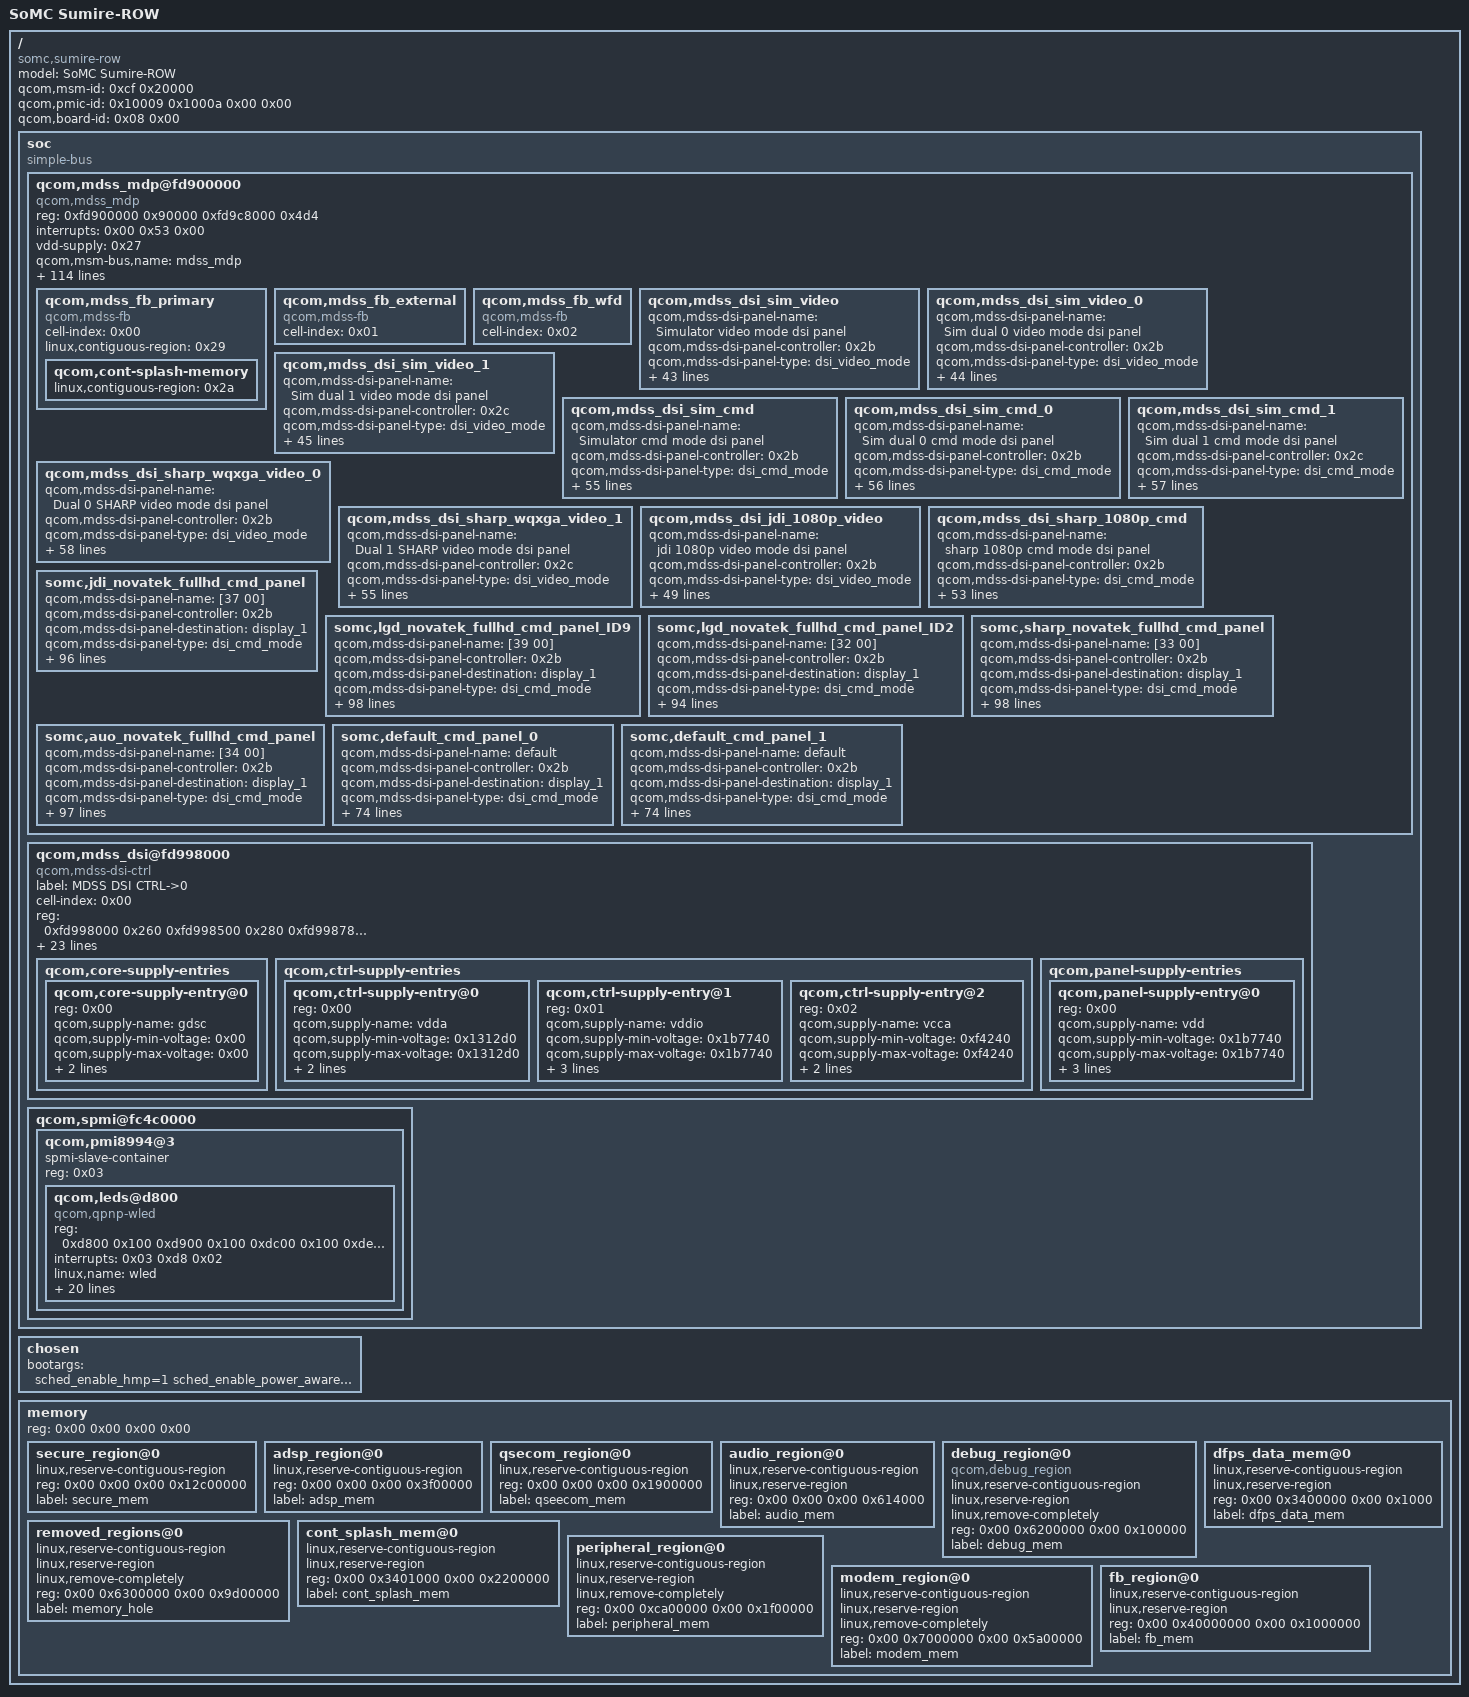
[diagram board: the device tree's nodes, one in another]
/dts-v1/;

/memreserve/	0x0000000000000000 0x0000000000001000;
/memreserve/	0x00000000ac1c0000 0x0000000000001000;
/ {
	model = "SoMC Sumire-ROW";
	compatible = "somc,sumire-row", "qcom,msm8994", "lk2nd,device";
	qcom,msm-id = <0xcf 0x20000>;
	qcom,pmic-id = <0x10009 0x1000a 0x00 0x00>;
	qcom,board-id = <0x08 0x00>;

	soc {
		#address-cells = <0x01>;
		#size-cells = <0x01>;
		ranges = <0x00 0x00 0x00 0xffffffff>;
		compatible = "simple-bus";

		qcom,mdss_mdp@fd900000 {
			compatible = "qcom,mdss_mdp";
			reg = <0xfd900000 0x90000 0xfd9c8000 0x4d4>;
			reg-names = "mdp_phys", "vbif_phys";
			interrupts = <0x00 0x53 0x00>;
			vdd-supply = <0x27>;
			qcom,msm-bus,name = "mdss_mdp";
			qcom,msm-bus,num-cases = <0x03>;
			qcom,msm-bus,num-paths = <0x02>;
			qcom,msm-bus,vectors-KBps = <0x16 0x200 0x00 0x00 0x17 0x200 0x00 0x00 0x16 0x200 0x00 0x61a800 0x17 0x200 0x00 0x61a800 0x16 0x200 0x00 0x61a800 0x17 0x200 0x00 0x61a800>;
			qcom,mdss-ab-factor = <0x01 0x01>;
			qcom,mdss-ib-factor = <0x01 0x01>;
			qcom,mdss-clk-factor = <0x69 0x64>;
			qcom,max-mixer-width = <0x800>;
			qcom,mdss-vbif-qos-rt-setting = <0x01 0x02 0x02 0x02>;
			qcom,mdss-vbif-qos-nrt-setting = <0x01 0x01 0x01 0x01>;
			qcom,mdss-mdp-reg-offset = <0x1000>;
			qcom,max-bandwidth-low-kbps = <0x6f63a0>;
			qcom,max-bandwidth-high-kbps = <0x6f63a0>;
			qcom,max-bandwidth-per-pipe-kbps = <0x1b7740>;
			qcom,max-clk-rate = <0x17d78400>;
			qcom,mdss-dram-channels = <0x02>;
			qcom,mdss-default-ot-wr-limit = <0x10>;
			qcom,mdss-default-ot-rd-limit = <0x10>;
			qcom,mdss-pipe-vig-off = <0x5000 0x7000 0x9000 0xb000>;
			qcom,mdss-pipe-rgb-off = <0x15000 0x17000 0x19000 0x1b000>;
			qcom,mdss-pipe-dma-off = <0x25000 0x27000>;
			qcom,mdss-pipe-cursor-off = <0x35000 0x37000>;
			qcom,mdss-pipe-vig-fetch-id = <0x01 0x04 0x07 0x13>;
			qcom,mdss-pipe-rgb-fetch-id = <0x10 0x11 0x12 0x16>;
			qcom,mdss-pipe-dma-fetch-id = <0x0a 0x0d>;
			qcom,mdss-pipe-vig-xin-id = <0x00 0x04 0x08 0x0c>;
			qcom,mdss-pipe-rgb-xin-id = <0x01 0x05 0x09 0x0d>;
			qcom,mdss-pipe-dma-xin-id = <0x02 0x0a>;
			qcom,mdss-pipe-cursor-xin-id = <0x07 0x07>;
			qcom,mdss-en-svs-high;
			qcom,mdss-has-panic-ctrl;
			qcom,mdss-pipe-vig-panic-ctrl-offsets = <0x00 0x01 0x02 0x03>;
			qcom,mdss-pipe-rgb-panic-ctrl-offsets = <0x04 0x05 0x06 0x07>;
			qcom,mdss-pipe-dma-panic-ctrl-offsets = <0x08 0x09>;
			qcom,mdss-pipe-rgb-fixed-mmb = <0x05 0x00 0x01 0x08 0x09 0x0a 0x05 0x02 0x03 0x0b 0x0c 0x0d 0x05 0x04 0x05 0x0e 0x0f 0x10 0x05 0x06 0x07 0x11 0x12 0x13>;
			qcom,mdss-pipe-vig-fixed-mmb = <0x01 0x14 0x01 0x15 0x01 0x16 0x01 0x17>;
			qcom,mdss-pipe-vig-clk-ctrl-offsets = <0x2ac 0x00 0x00 0x2b4 0x00 0x00 0x2bc 0x00 0x00 0x2c4 0x00 0x00>;
			qcom,mdss-pipe-rgb-clk-ctrl-offsets = <0x2ac 0x04 0x08 0x2b4 0x04 0x08 0x2bc 0x04 0x08 0x2c4 0x04 0x08>;
			qcom,mdss-pipe-dma-clk-ctrl-offsets = <0x2ac 0x08 0x0c 0x2b4 0x08 0x0c>;
			qcom,mdss-pipe-cursor-clk-ctrl-offsets = <0x3a8 0x10 0x0f 0x3b0 0x10 0x0f>;
			qcom,mdss-pipe-sw-reset-off = <0x28>;
			qcom,mdss-pipe-vig-sw-reset-map = <0x05 0x06 0x07 0x08>;
			qcom,mdss-pipe-rgb-sw-reset-map = <0x09 0x0a 0x0b 0x0c>;
			qcom,mdss-pipe-dma-sw-reset-map = <0x0d 0x0e>;
			qcom,mdss-smp-data = <0x2c 0x2000>;
			qcom,mdss-sspp-len = <0x2000>;
			qcom,mdss-ctl-off = <0x2000 0x2200 0x2400 0x2600 0x2800>;
			qcom,mdss-mixer-intf-off = <0x45000 0x46000 0x47000 0x4a000>;
			qcom,mdss-mixer-wb-off = <0x48000 0x49000>;
			qcom,mdss-dspp-off = <0x55000 0x57000 0x59000 0x5b000>;
			qcom,mdss-wb-off = <0x65000 0x65800 0x66000 0x66800 0x67000>;
			qcom,mdss-intf-off = <0x6b000 0x6b800 0x6c000 0x6c800 0x6d000>;
			qcom,mdss-pingpong-off = <0x71000 0x71800 0x72000 0x72800>;
			qcom,mdss-ad-off = <0x79000 0x79800 0x7a000>;
			qcom,mdss-highest-bank-bit = <0x03>;
			qcom,mdss-has-decimation;
			qcom,mdss-has-rotator-downscale;
			qcom,mdss-has-bwc;
			qcom,mdss-wfd-mode = "intf";
			qcom,mdss-has-source-split;
			qcom,mdss-ctl-len = <0x200>;
			clocks = <0x1e 0x684ccb41 0x1e 0xcc07d687 0x1e 0x6dc1f8f1 0x1e 0x618336ac 0x1e 0x42a022d3>;
			clock-names = "iface_clk", "bus_clk", "core_clk_src", "core_clk", "vsync_clk";
			qcom,mdp-settings = <0x117c 0xffff 0x1184 0xc000ff00 0x11e0 0xa4 0x11e4 0x00 0x12ac 0xc0000ccc 0x12b4 0xc0000ccc 0x12bc 0xcccccc 0x12c4 0xcc 0x13a8 0xcccc0c0 0x13b0 0xccccc0c0 0x13b8 0xccccc0c0 0x13d0 0xccc000>;
			qcom,regs-dump-mdp = <0x1000 0x1408 0x2000 0x2064 0x2200 0x2264 0x2400 0x2464 0x2600 0x2664 0x2800 0x2864 0x5000 0x5130 0x5200 0x5230 0x7000 0x7130 0x7200 0x7230 0x9000 0x9130 0x9200 0x9230 0xb000 0xb130 0xb200 0xb230 0x15000 0x15130 0x15200 0x15230 0x17000 0x17130 0x17200 0x17230 0x19000 0x19130 0x19200 0x19230 0x1b000 0x1b130 0x1b200 0x1b230 0x25000 0x2512c 0x27000 0x2712c 0x45000 0x4538c 0x46000 0x4638c 0x47000 0x4738c 0x48000 0x4838c 0x49000 0x4938c 0x4a000 0x4a38c 0x55000 0x5522c 0x57000 0x5722c 0x59000 0x5922c 0x5b000 0x5b22c 0x65000 0x652b4 0x65800 0x65ab4 0x66000 0x662b4 0x66800 0x66ab4 0x67000 0x672b4 0x6b800 0x6ba54 0x6c000 0x6c254 0x6c800 0x6ca54 0x71000 0x710d0 0x71800 0x718d0>;
			qcom,regs-dump-names-mdp = "MDP", "CTL_0", "CTL_1", "CTL_2", "CTL_3", "CTL_4", "VIG0_SSPP", "VIG0", "VIG1_SSPP", "VIG1", "VIG2_SSPP", "VIG2", "VIG3_SSPP", "VIG3", "RGB0_SSPP", "RGB0", "RGB1_SSPP", "RGB1", "RGB2_SSPP", "RGB2", "RGB3_SSPP", "RGB3", "DMA0_SSPP", "DMA1_SSPP", "LAYER_0", "LAYER_1", "LAYER_2", "LAYER_3", "LAYER_4", "LAYER_5", "DSPP_0", "DSPP_1", "DSPP_2", "DSPP_3", "WB_0", "WB_1", "WB_2", "WB_3", "WB_4", "INTF_1", "INTF_2", "INTF_3", "PP_0", "PP_1";
			qcom,mdss-prefill-outstanding-buffer-bytes = <0x800>;
			qcom,mdss-prefill-y-buffer-bytes = <0x1000>;
			qcom,mdss-prefill-scaler-buffer-lines-bilinear = <0x02>;
			qcom,mdss-prefill-scaler-buffer-lines-caf = <0x04>;
			qcom,mdss-prefill-post-scaler-buffer-pixels = <0x800>;
			qcom,mdss-prefill-pingpong-buffer-pixels = <0x1400>;
			qcom,mdss-prefill-fbc-lines = <0x02>;
			qcom,mdss-pref-prim-intf = "dsi";
			somc,dric-gpio = <0x28 0x38 0x00>;
			somc,mul-channel-scaling = <0x03>;
			linux,phandle = <0x32>;
			phandle = <0x32>;

			qcom,mdss_fb_primary {
				cell-index = <0x00>;
				compatible = "qcom,mdss-fb";
				linux,contiguous-region = <0x29>;
				linux,phandle = <0x31>;
				phandle = <0x31>;

				qcom,cont-splash-memory {
					linux,contiguous-region = <0x2a>;
				};
			};

			qcom,mdss_fb_external {
				cell-index = <0x01>;
				compatible = "qcom,mdss-fb";
				linux,phandle = <0x41>;
				phandle = <0x41>;
			};

			qcom,mdss_fb_wfd {
				cell-index = <0x02>;
				compatible = "qcom,mdss-fb";
				linux,phandle = <0x3e>;
				phandle = <0x3e>;
			};

			qcom,mdss_dsi_sim_video {
				qcom,mdss-dsi-panel-name = "Simulator video mode dsi panel";
				qcom,mdss-dsi-panel-controller = <0x2b>;
				qcom,mdss-dsi-panel-type = "dsi_video_mode";
				qcom,mdss-dsi-panel-destination = "display_1";
				qcom,mdss-dsi-panel-framerate = <0x3c>;
				qcom,mdss-dsi-virtual-channel-id = <0x00>;
				qcom,mdss-dsi-stream = <0x00>;
				qcom,mdss-dsi-panel-width = <0x280>;
				qcom,mdss-dsi-panel-height = <0x1e0>;
				qcom,mdss-dsi-h-front-porch = <0x06>;
				qcom,mdss-dsi-h-back-porch = <0x06>;
				qcom,mdss-dsi-h-pulse-width = <0x02>;
				qcom,mdss-dsi-h-sync-skew = <0x00>;
				qcom,mdss-dsi-v-back-porch = <0x06>;
				qcom,mdss-dsi-v-front-porch = <0x06>;
				qcom,mdss-dsi-v-pulse-width = <0x02>;
				qcom,mdss-dsi-h-left-border = <0x00>;
				qcom,mdss-dsi-h-right-border = <0x00>;
				qcom,mdss-dsi-v-top-border = <0x00>;
				qcom,mdss-dsi-v-bottom-border = <0x00>;
				qcom,mdss-dsi-bpp = <0x18>;
				qcom,mdss-dsi-underflow-color = <0xff>;
				qcom,mdss-dsi-border-color = <0x00>;
				qcom,mdss-dsi-on-command = [32 01 00 00 00 00 02 00 00];
				qcom,mdss-dsi-off-command = [22 01 00 00 00 00 02 00 00];
				qcom,mdss-dsi-on-command-state = "dsi_lp_mode";
				qcom,mdss-dsi-off-command-state = "dsi_lp_mode";
				qcom,mdss-dsi-h-sync-pulse = <0x00>;
				qcom,mdss-dsi-traffic-mode = "non_burst_sync_event";
				qcom,mdss-dsi-bllp-eof-power-mode;
				qcom,mdss-dsi-bllp-power-mode;
				qcom,mdss-dsi-lane-0-state;
				qcom,mdss-dsi-lane-1-state;
				qcom,mdss-dsi-lane-2-state;
				qcom,mdss-dsi-lane-3-state;
				qcom,mdss-dsi-panel-timings = <0x00 0x00 0x00>;
				qcom,mdss-dsi-t-clk-post = <0x04>;
				qcom,mdss-dsi-t-clk-pre = <0x1b>;
				qcom,mdss-dsi-dma-trigger = "trigger_sw";
				qcom,mdss-dsi-mdp-trigger = "none";
				qcom,mdss-dsi-reset-sequence = <0x01 0x00 0x00 0x00 0x01 0x00>;
				qcom,panel-ack-disabled;
			};

			qcom,mdss_dsi_sim_video_0 {
				qcom,mdss-dsi-panel-name = "Sim dual 0 video mode dsi panel";
				qcom,mdss-dsi-panel-controller = <0x2b>;
				qcom,mdss-dsi-panel-type = "dsi_video_mode";
				qcom,mdss-dsi-panel-destination = "display_1";
				qcom,mdss-dsi-panel-framerate = <0x3c>;
				qcom,mdss-dsi-virtual-channel-id = <0x00>;
				qcom,mdss-dsi-stream = <0x00>;
				qcom,mdss-dsi-panel-width = <0x500>;
				qcom,mdss-dsi-panel-height = <0x5a0>;
				qcom,mdss-dsi-h-front-porch = <0x78>;
				qcom,mdss-dsi-h-back-porch = <0x2c>;
				qcom,mdss-dsi-h-pulse-width = <0x10>;
				qcom,mdss-dsi-h-sync-skew = <0x00>;
				qcom,mdss-dsi-v-back-porch = <0x04>;
				qcom,mdss-dsi-v-front-porch = <0x08>;
				qcom,mdss-dsi-v-pulse-width = <0x04>;
				qcom,mdss-dsi-h-left-border = <0x00>;
				qcom,mdss-dsi-h-right-border = <0x00>;
				qcom,mdss-dsi-v-top-border = <0x00>;
				qcom,mdss-dsi-v-bottom-border = <0x00>;
				qcom,mdss-dsi-bpp = <0x18>;
				qcom,mdss-dsi-underflow-color = <0xff>;
				qcom,mdss-dsi-border-color = <0x00>;
				qcom,mdss-dsi-h-sync-pulse = <0x00>;
				qcom,mdss-dsi-traffic-mode = "non_burst_sync_event";
				qcom,mdss-dsi-bllp-eof-power-mode;
				qcom,mdss-dsi-bllp-power-mode;
				qcom,mdss-dsi-panel-broadcast-mode;
				qcom,mdss-dsi-lane-0-state;
				qcom,mdss-dsi-lane-1-state;
				qcom,mdss-dsi-lane-2-state;
				qcom,mdss-dsi-lane-3-state;
				qcom,mdss-dsi-panel-timings = <0xcd322200 0x60642634 0x29030400>;
				qcom,mdss-dsi-t-clk-post = <0x03>;
				qcom,mdss-dsi-t-clk-pre = <0x27>;
				qcom,mdss-dsi-bl-max-level = <0xfff>;
				qcom,mdss-dsi-dma-trigger = "trigger_sw";
				qcom,mdss-dsi-mdp-trigger = "none";
				qcom,mdss-dsi-on-command-state = "dsi_lp_mode";
				qcom,mdss-dsi-off-command = [05 01 00 00 32 00 02 28 00 05 01 00 00 78 00 02 10 00];
				qcom,mdss-dsi-off-command-state = "dsi_hs_mode";
				qcom,mdss-dsi-reset-sequence = <0x01 0x14 0x00 0xc8 0x01 0x14>;
				qcom,panel-ack-disabled;
			};

			qcom,mdss_dsi_sim_video_1 {
				qcom,mdss-dsi-panel-name = "Sim dual 1 video mode dsi panel";
				qcom,mdss-dsi-panel-controller = <0x2c>;
				qcom,mdss-dsi-panel-type = "dsi_video_mode";
				qcom,mdss-dsi-panel-destination = "display_2";
				qcom,mdss-dsi-panel-framerate = <0x3c>;
				qcom,mdss-dsi-virtual-channel-id = <0x00>;
				qcom,mdss-dsi-stream = <0x00>;
				qcom,mdss-dsi-panel-width = <0x500>;
				qcom,mdss-dsi-panel-height = <0x5a0>;
				qcom,mdss-dsi-h-front-porch = <0x78>;
				qcom,mdss-dsi-h-back-porch = <0x2c>;
				qcom,mdss-dsi-h-pulse-width = <0x10>;
				qcom,mdss-dsi-h-sync-skew = <0x00>;
				qcom,mdss-dsi-v-back-porch = <0x04>;
				qcom,mdss-dsi-v-front-porch = <0x08>;
				qcom,mdss-dsi-v-pulse-width = <0x04>;
				qcom,mdss-dsi-h-left-border = <0x00>;
				qcom,mdss-dsi-h-right-border = <0x00>;
				qcom,mdss-dsi-v-top-border = <0x00>;
				qcom,mdss-dsi-v-bottom-border = <0x00>;
				qcom,mdss-dsi-bpp = <0x18>;
				qcom,mdss-dsi-underflow-color = <0xff>;
				qcom,mdss-dsi-border-color = <0x00>;
				qcom,mdss-dsi-h-sync-pulse = <0x00>;
				qcom,mdss-dsi-traffic-mode = "non_burst_sync_event";
				qcom,mdss-dsi-bllp-eof-power-mode;
				qcom,mdss-dsi-bllp-power-mode;
				qcom,mdss-dsi-lane-0-state;
				qcom,mdss-dsi-lane-1-state;
				qcom,mdss-dsi-lane-2-state;
				qcom,mdss-dsi-lane-3-state;
				qcom,mdss-dsi-panel-broadcast-mode;
				qcom,mdss-dsi-panel-timings = <0xcd322200 0x60642634 0x29030400>;
				qcom,mdss-dsi-t-clk-post = <0x03>;
				qcom,mdss-dsi-t-clk-pre = <0x27>;
				qcom,mdss-dsi-bl-min-level = <0x01>;
				qcom,mdss-dsi-bl-max-level = <0xfff>;
				qcom,mdss-dsi-dma-trigger = "trigger_sw";
				qcom,mdss-dsi-mdp-trigger = "none";
				qcom,mdss-dsi-on-command-state = "dsi_lp_mode";
				qcom,mdss-dsi-off-command = [05 01 00 00 32 00 02 28 00 05 01 00 00 78 00 02 10 00];
				qcom,mdss-dsi-off-command-state = "dsi_hs_mode";
				qcom,mdss-dsi-reset-sequence = <0x01 0x14 0x00 0xc8 0x01 0x14>;
				qcom,panel-ack-disabled;
			};

			qcom,mdss_dsi_sim_cmd {
				qcom,mdss-dsi-panel-name = "Simulator cmd mode dsi panel";
				qcom,mdss-dsi-panel-controller = <0x2b>;
				qcom,mdss-dsi-panel-type = "dsi_cmd_mode";
				qcom,mdss-dsi-panel-destination = "display_1";
				qcom,mdss-dsi-panel-framerate = <0x3c>;
				qcom,mdss-dsi-virtual-channel-id = <0x00>;
				qcom,mdss-dsi-stream = <0x00>;
				qcom,mdss-dsi-panel-width = <0x438>;
				qcom,mdss-dsi-panel-height = <0x780>;
				qcom,mdss-dsi-h-front-porch = <0x60>;
				qcom,mdss-dsi-h-back-porch = <0x40>;
				qcom,mdss-dsi-h-pulse-width = <0x10>;
				qcom,mdss-dsi-h-sync-skew = <0x00>;
				qcom,mdss-dsi-v-back-porch = <0x10>;
				qcom,mdss-dsi-v-front-porch = <0x04>;
				qcom,mdss-dsi-v-pulse-width = <0x01>;
				qcom,mdss-dsi-h-left-border = <0x00>;
				qcom,mdss-dsi-h-right-border = <0x00>;
				qcom,mdss-dsi-v-top-border = <0x00>;
				qcom,mdss-dsi-v-bottom-border = <0x00>;
				qcom,mdss-dsi-bpp = <0x18>;
				qcom,mdss-dsi-color-order = "rgb_swap_rgb";
				qcom,mdss-dsi-underflow-color = <0xff>;
				qcom,mdss-dsi-border-color = <0x00>;
				qcom,mdss-dsi-h-sync-pulse = <0x00>;
				qcom,mdss-dsi-traffic-mode = "non_burst_sync_event";
				qcom,mdss-dsi-lane-map = "lane_map_0123";
				qcom,mdss-dsi-bllp-eof-power-mode;
				qcom,mdss-dsi-bllp-power-mode;
				qcom,mdss-dsi-lane-0-state;
				qcom,mdss-dsi-lane-1-state;
				qcom,mdss-dsi-lane-2-state;
				qcom,mdss-dsi-lane-3-state;
				qcom,mdss-dsi-hor-line-idle = <0x00 0x28 0x100 0x28 0x78 0x80 0x78 0xf0 0x40>;
				qcom,mdss-dsi-panel-timings = <0xcd322200 0x60642634 0x29030400>;
				qcom,mdss-dsi-reset-sequence = <0x01 0x0a 0x00 0x0a 0x01 0x0a>;
				qcom,mdss-dsi-t-clk-post = <0x03>;
				qcom,mdss-dsi-t-clk-pre = <0x27>;
				qcom,mdss-dsi-bl-max-level = <0xfff>;
				qcom,mdss-dsi-dma-trigger = "trigger_sw";
				qcom,mdss-dsi-mdp-trigger = "none";
				qcom,mdss-dsi-te-pin-select = <0x01>;
				qcom,mdss-dsi-wr-mem-start = <0x2c>;
				qcom,mdss-dsi-wr-mem-continue = <0x3c>;
				qcom,mdss-dsi-te-dcs-command = <0x01>;
				qcom,mdss-dsi-te-check-enable;
				qcom,mdss-dsi-te-using-te-pin;
				qcom,mdss-dsi-on-command = <0x29010000 0x2b0 0x3050100 0xa0001 0x150100 0xa0002 0x3a773901 0xa00 0x52a0000 0x4ff3901 0xa00 0x52b0000 0x59f1501 0xa00 0x2350039 0x100000a 0x34400 0x150100 0xa0002 0x51ff1501 0xa00 0x2532415 0x100000a 0x25500 0x5010000 0x78000111 0x5010000 0x10000129>;
				qcom,mdss-dsi-on-command-state = "dsi_lp_mode";
				qcom,mdss-dsi-off-command = [05 01 00 00 32 00 02 28 00 05 01 00 00 78 00 02 10 00];
				qcom,mdss-dsi-off-command-state = "dsi_hs_mode";
				qcom,panel-ack-disabled;
			};

			qcom,mdss_dsi_sim_cmd_0 {
				qcom,mdss-dsi-panel-name = "Sim dual 0 cmd mode dsi panel";
				qcom,mdss-dsi-panel-controller = <0x2b>;
				qcom,mdss-dsi-panel-type = "dsi_cmd_mode";
				qcom,mdss-dsi-panel-destination = "display_1";
				qcom,mdss-dsi-panel-framerate = <0x3c>;
				qcom,mdss-dsi-virtual-channel-id = <0x00>;
				qcom,mdss-dsi-stream = <0x00>;
				qcom,mdss-dsi-panel-width = <0x500>;
				qcom,mdss-dsi-panel-height = <0x5a0>;
				qcom,mdss-dsi-h-front-porch = <0x78>;
				qcom,mdss-dsi-h-back-porch = <0x2c>;
				qcom,mdss-dsi-h-pulse-width = <0x10>;
				qcom,mdss-dsi-h-sync-skew = <0x00>;
				qcom,mdss-dsi-v-back-porch = <0x04>;
				qcom,mdss-dsi-v-front-porch = <0x08>;
				qcom,mdss-dsi-v-pulse-width = <0x04>;
				qcom,mdss-dsi-h-left-border = <0x00>;
				qcom,mdss-dsi-h-right-border = <0x00>;
				qcom,mdss-dsi-v-top-border = <0x00>;
				qcom,mdss-dsi-v-bottom-border = <0x00>;
				qcom,mdss-dsi-bpp = <0x18>;
				qcom,mdss-dsi-color-order = "rgb_swap_rgb";
				qcom,mdss-dsi-underflow-color = <0xff>;
				qcom,mdss-dsi-border-color = <0x00>;
				qcom,mdss-dsi-h-sync-pulse = <0x00>;
				qcom,mdss-dsi-traffic-mode = "non_burst_sync_event";
				qcom,mdss-dsi-lane-map = "lane_map_0123";
				qcom,mdss-dsi-bllp-eof-power-mode;
				qcom,mdss-dsi-bllp-power-mode;
				qcom,cmd-sync-wait-broadcast;
				qcom,mdss-dsi-lane-0-state;
				qcom,mdss-dsi-lane-1-state;
				qcom,mdss-dsi-lane-2-state;
				qcom,mdss-dsi-lane-3-state;
				qcom,mdss-dsi-hor-line-idle = <0x00 0x28 0x100 0x28 0x78 0x80 0x78 0xf0 0x40>;
				qcom,mdss-dsi-panel-timings = <0xcd322200 0x60642634 0x29030400>;
				qcom,mdss-dsi-reset-sequence = <0x01 0x0a 0x00 0x0a 0x01 0x0a>;
				qcom,mdss-dsi-t-clk-post = <0x03>;
				qcom,mdss-dsi-t-clk-pre = <0x27>;
				qcom,mdss-dsi-bl-max-level = <0xfff>;
				qcom,mdss-dsi-dma-trigger = "trigger_sw";
				qcom,mdss-dsi-mdp-trigger = "none";
				qcom,mdss-dsi-te-pin-select = <0x01>;
				qcom,mdss-dsi-wr-mem-start = <0x2c>;
				qcom,mdss-dsi-wr-mem-continue = <0x3c>;
				qcom,mdss-dsi-te-dcs-command = <0x01>;
				qcom,mdss-dsi-te-check-enable;
				qcom,mdss-dsi-te-using-te-pin;
				qcom,mdss-dsi-on-command = <0x29010000 0x2b0 0x3050100 0xa0001 0x150100 0xa0002 0x3a773901 0xa00 0x52a0000 0x4ff3901 0xa00 0x52b0000 0x59f1501 0xa00 0x2350039 0x100000a 0x34400 0x150100 0xa0002 0x51ff1501 0xa00 0x2532415 0x100000a 0x25500 0x5010000 0x78000111 0x5010000 0x10000129>;
				qcom,mdss-dsi-on-command-state = "dsi_lp_mode";
				qcom,mdss-dsi-off-command = [05 01 00 00 32 00 02 28 00 05 01 00 00 78 00 02 10 00];
				qcom,mdss-dsi-off-command-state = "dsi_hs_mode";
				qcom,panel-ack-disabled;
			};

			qcom,mdss_dsi_sim_cmd_1 {
				qcom,mdss-dsi-panel-name = "Sim dual 1 cmd mode dsi panel";
				qcom,mdss-dsi-panel-controller = <0x2c>;
				qcom,mdss-dsi-panel-type = "dsi_cmd_mode";
				qcom,mdss-dsi-panel-destination = "display_2";
				qcom,mdss-dsi-panel-framerate = <0x3c>;
				qcom,mdss-dsi-virtual-channel-id = <0x00>;
				qcom,mdss-dsi-stream = <0x00>;
				qcom,mdss-dsi-panel-width = <0x500>;
				qcom,mdss-dsi-panel-height = <0x5a0>;
				qcom,mdss-dsi-h-front-porch = <0x78>;
				qcom,mdss-dsi-h-back-porch = <0x2c>;
				qcom,mdss-dsi-h-pulse-width = <0x10>;
				qcom,mdss-dsi-h-sync-skew = <0x00>;
				qcom,mdss-dsi-v-back-porch = <0x04>;
				qcom,mdss-dsi-v-front-porch = <0x08>;
				qcom,mdss-dsi-v-pulse-width = <0x04>;
				qcom,mdss-dsi-h-left-border = <0x00>;
				qcom,mdss-dsi-h-right-border = <0x00>;
				qcom,mdss-dsi-v-top-border = <0x00>;
				qcom,mdss-dsi-v-bottom-border = <0x00>;
				qcom,mdss-dsi-bpp = <0x18>;
				qcom,mdss-dsi-color-order = "rgb_swap_rgb";
				qcom,mdss-dsi-underflow-color = <0xff>;
				qcom,mdss-dsi-border-color = <0x00>;
				qcom,mdss-dsi-h-sync-pulse = <0x00>;
				qcom,mdss-dsi-traffic-mode = "non_burst_sync_event";
				qcom,mdss-dsi-lane-map = "lane_map_0123";
				qcom,mdss-dsi-bllp-eof-power-mode;
				qcom,mdss-dsi-bllp-power-mode;
				qcom,cmd-sync-wait-broadcast;
				qcom,cmd-sync-wait-trigger;
				qcom,mdss-dsi-lane-0-state;
				qcom,mdss-dsi-lane-1-state;
				qcom,mdss-dsi-lane-2-state;
				qcom,mdss-dsi-lane-3-state;
				qcom,mdss-dsi-hor-line-idle = <0x00 0x28 0x100 0x28 0x78 0x80 0x78 0xf0 0x40>;
				qcom,mdss-dsi-panel-timings = <0xcd322200 0x60642634 0x29030400>;
				qcom,mdss-dsi-reset-sequence = <0x01 0x0a 0x00 0x0a 0x01 0x0a>;
				qcom,mdss-dsi-t-clk-post = <0x03>;
				qcom,mdss-dsi-t-clk-pre = <0x27>;
				qcom,mdss-dsi-bl-max-level = <0xfff>;
				qcom,mdss-dsi-dma-trigger = "trigger_sw";
				qcom,mdss-dsi-mdp-trigger = "none";
				qcom,mdss-dsi-te-pin-select = <0x01>;
				qcom,mdss-dsi-wr-mem-start = <0x2c>;
				qcom,mdss-dsi-wr-mem-continue = <0x3c>;
				qcom,mdss-dsi-te-dcs-command = <0x01>;
				qcom,mdss-dsi-te-check-enable;
				qcom,mdss-dsi-te-using-te-pin;
				qcom,mdss-dsi-on-command = <0x29010000 0x2b0 0x3050100 0xa0001 0x150100 0xa0002 0x3a773901 0xa00 0x52a0000 0x4ff3901 0xa00 0x52b0000 0x59f1501 0xa00 0x2350039 0x100000a 0x34400 0x150100 0xa0002 0x51ff1501 0xa00 0x2532415 0x100000a 0x25500 0x5010000 0x78000111 0x5010000 0x10000129>;
				qcom,mdss-dsi-on-command-state = "dsi_lp_mode";
				qcom,mdss-dsi-off-command = [05 01 00 00 32 00 02 28 00 05 01 00 00 78 00 02 10 00];
				qcom,mdss-dsi-off-command-state = "dsi_hs_mode";
				qcom,panel-ack-disabled;
			};

			qcom,mdss_dsi_sharp_wqxga_video_0 {
				qcom,mdss-dsi-panel-name = "Dual 0 SHARP video mode dsi panel";
				qcom,mdss-dsi-panel-controller = <0x2b>;
				qcom,mdss-dsi-panel-type = "dsi_video_mode";
				qcom,mdss-dsi-panel-destination = "display_1";
				qcom,mdss-dsi-panel-framerate = <0x3c>;
				qcom,mdss-dsi-virtual-channel-id = <0x00>;
				qcom,mdss-dsi-stream = <0x00>;
				qcom,mdss-dsi-panel-width = <0x320>;
				qcom,mdss-dsi-panel-height = <0xa00>;
				qcom,mdss-dsi-h-front-porch = <0x4c>;
				qcom,mdss-dsi-h-back-porch = <0x20>;
				qcom,mdss-dsi-h-pulse-width = <0x10>;
				qcom,mdss-dsi-h-sync-skew = <0x00>;
				qcom,mdss-dsi-v-back-porch = <0x0b>;
				qcom,mdss-dsi-v-front-porch = <0x02>;
				qcom,mdss-dsi-v-pulse-width = <0x01>;
				qcom,mdss-dsi-bpp = <0x18>;
				qcom,mdss-dsi-underflow-color = <0xff>;
				qcom,mdss-dsi-border-color = <0x00>;
				qcom,mdss-dsi-on-command = [05 01 00 00 a0 00 02 11 00 05 01 00 00 02 00 02 29 00];
				qcom,mdss-dsi-off-command = [05 01 00 00 02 00 02 28 00 05 01 00 00 a0 00 02 10 00];
				qcom,mdss-dsi-on-command-state = "dsi_lp_mode";
				qcom,mdss-dsi-off-command-state = "dsi_hs_mode";
				qcom,mdss-dsi-h-sync-pulse = <0x00>;
				qcom,mdss-dsi-traffic-mode = "non_burst_sync_event";
				qcom,mdss-dsi-bllp-eof-power-mode;
				qcom,mdss-dsi-bllp-power-mode;
				qcom,mdss-dsi-lane-0-state;
				qcom,mdss-dsi-lane-1-state;
				qcom,mdss-dsi-lane-2-state;
				qcom,mdss-dsi-lane-3-state;
				qcom,cmd-sync-wait-broadcast;
				qcom,mdss-dsi-panel-timings = <0xe2362400 0x666a2838 0x2a030400>;
				qcom,mdss-dsi-t-clk-post = <0x02>;
				qcom,mdss-dsi-t-clk-pre = <0x2a>;
				qcom,mdss-dsi-bl-min-level = <0x01>;
				qcom,mdss-dsi-bl-max-level = <0xfff>;
				qcom,mdss-dsi-dma-trigger = "trigger_sw";
				qcom,mdss-dsi-mdp-trigger = "none";
				qcom,mdss-dsi-bl-pmic-control-type = "bl_ctrl_wled";
				qcom,mdss-dsi-bl-pmic-pwm-frequency = <0x32>;
				qcom,mdss-dsi-bl-pmic-bank-select = <0x02>;
				qcom,mdss-dsi-reset-sequence = <0x01 0x02 0x00 0x05 0x01 0x78>;
				qcom,mdss-pan-physical-width-dimension = <0x53>;
				qcom,mdss-pan-physical-height-dimension = <0x85>;
				qcom,mdss-dsi-min-refresh-rate = <0x1e>;
				qcom,mdss-dsi-max-refresh-rate = <0x3c>;
				qcom,mdss-dsi-panel-status-check-mode = "bta_check";
				qcom,mdss-dsi-tx-eot-append;
				qcom,esd-check-enabled;
				qcom,cont-splash-enabled;
				qcom,mdss-dsi-pan-enable-dynamic-fps;
				qcom,mdss-dsi-pan-fps-update = "dfps_immediate_porch_mode_vfp";
			};

			qcom,mdss_dsi_sharp_wqxga_video_1 {
				qcom,mdss-dsi-panel-name = "Dual 1 SHARP video mode dsi panel";
				qcom,mdss-dsi-panel-controller = <0x2c>;
				qcom,mdss-dsi-panel-type = "dsi_video_mode";
				qcom,mdss-dsi-panel-destination = "display_2";
				qcom,mdss-dsi-panel-framerate = <0x3c>;
				qcom,mdss-dsi-virtual-channel-id = <0x00>;
				qcom,mdss-dsi-stream = <0x00>;
				qcom,mdss-dsi-panel-width = <0x320>;
				qcom,mdss-dsi-panel-height = <0xa00>;
				qcom,mdss-dsi-h-front-porch = <0x4c>;
				qcom,mdss-dsi-h-back-porch = <0x20>;
				qcom,mdss-dsi-h-pulse-width = <0x10>;
				qcom,mdss-dsi-h-sync-skew = <0x00>;
				qcom,mdss-dsi-v-back-porch = <0x0b>;
				qcom,mdss-dsi-v-front-porch = <0x02>;
				qcom,mdss-dsi-v-pulse-width = <0x01>;
				qcom,mdss-dsi-bpp = <0x18>;
				qcom,mdss-dsi-underflow-color = <0xff>;
				qcom,mdss-dsi-border-color = <0x00>;
				qcom,mdss-dsi-on-command = [05 01 00 00 a0 00 02 11 00 05 01 00 00 02 00 02 29 00];
				qcom,mdss-dsi-off-command = [05 01 00 00 02 00 02 28 00 05 01 00 00 a0 00 02 10 00];
				qcom,mdss-dsi-on-command-state = "dsi_lp_mode";
				qcom,mdss-dsi-off-command-state = "dsi_hs_mode";
				qcom,mdss-dsi-h-sync-pulse = <0x00>;
				qcom,mdss-dsi-traffic-mode = "non_burst_sync_event";
				qcom,mdss-dsi-bllp-eof-power-mode;
				qcom,mdss-dsi-bllp-power-mode;
				qcom,mdss-dsi-lane-0-state;
				qcom,mdss-dsi-lane-1-state;
				qcom,mdss-dsi-lane-2-state;
				qcom,mdss-dsi-lane-3-state;
				qcom,cmd-sync-wait-broadcast;
				qcom,cmd-sync-wait-trigger;
				qcom,mdss-dsi-panel-timings = <0xe2362400 0x666a2838 0x2a030400>;
				qcom,mdss-dsi-t-clk-post = <0x02>;
				qcom,mdss-dsi-t-clk-pre = <0x2a>;
				qcom,mdss-dsi-bl-min-level = <0x01>;
				qcom,mdss-dsi-bl-max-level = <0xfff>;
				qcom,mdss-dsi-dma-trigger = "trigger_sw";
				qcom,mdss-dsi-mdp-trigger = "none";
				qcom,mdss-dsi-reset-sequence = <0x01 0x02 0x00 0x05 0x01 0x78>;
				qcom,mdss-pan-physical-width-dimension = <0x53>;
				qcom,mdss-pan-physical-height-dimension = <0x85>;
				qcom,mdss-dsi-min-refresh-rate = <0x1e>;
				qcom,mdss-dsi-max-refresh-rate = <0x3c>;
				qcom,mdss-dsi-panel-status-check-mode = "bta_check";
				qcom,mdss-dsi-tx-eot-append;
				qcom,esd-check-enabled;
				qcom,cont-splash-enabled;
				qcom,mdss-dsi-pan-enable-dynamic-fps;
				qcom,mdss-dsi-pan-fps-update = "dfps_immediate_porch_mode_vfp";
				linux,phandle = <0x3d>;
				phandle = <0x3d>;
			};

			qcom,mdss_dsi_jdi_1080p_video {
				qcom,mdss-dsi-panel-name = "jdi 1080p video mode dsi panel";
				qcom,mdss-dsi-panel-controller = <0x2b>;
				qcom,mdss-dsi-panel-type = "dsi_video_mode";
				qcom,mdss-dsi-panel-destination = "display_1";
				qcom,mdss-dsi-panel-framerate = <0x3c>;
				qcom,mdss-dsi-virtual-channel-id = <0x00>;
				qcom,mdss-dsi-stream = <0x00>;
				qcom,mdss-dsi-panel-width = <0x438>;
				qcom,mdss-dsi-panel-height = <0x780>;
				qcom,mdss-dsi-h-front-porch = <0x60>;
				qcom,mdss-dsi-h-back-porch = <0x40>;
				qcom,mdss-dsi-h-pulse-width = <0x10>;
				qcom,mdss-dsi-h-sync-skew = <0x00>;
				qcom,mdss-dsi-v-back-porch = <0x10>;
				qcom,mdss-dsi-v-front-porch = <0x04>;
				qcom,mdss-dsi-v-pulse-width = <0x01>;
				qcom,mdss-dsi-h-left-border = <0x00>;
				qcom,mdss-dsi-h-right-border = <0x00>;
				qcom,mdss-dsi-v-top-border = <0x00>;
				qcom,mdss-dsi-v-bottom-border = <0x00>;
				qcom,mdss-dsi-bpp = <0x18>;
				qcom,mdss-dsi-underflow-color = <0xff>;
				qcom,mdss-dsi-border-color = <0x00>;
				qcom,mdss-dsi-on-command = [15 01 00 00 00 00 02 55 00 15 01 00 00 00 00 02 53 2c 15 01 00 00 00 00 02 35 00 05 01 00 00 78 00 02 29 00 05 01 00 00 78 00 02 11 00];
				qcom,mdss-dsi-off-command = [05 01 00 00 02 00 02 28 00 05 01 00 00 79 00 02 10 00];
				qcom,mdss-dsi-on-command-state = "dsi_lp_mode";
				qcom,mdss-dsi-off-command-state = "dsi_hs_mode";
				qcom,mdss-dsi-h-sync-pulse = <0x00>;
				qcom,mdss-dsi-traffic-mode = "burst_mode";
				qcom,mdss-dsi-bllp-eof-power-mode;
				qcom,mdss-dsi-bllp-power-mode;
				qcom,mdss-dsi-lane-0-state;
				qcom,mdss-dsi-lane-1-state;
				qcom,mdss-dsi-lane-2-state;
				qcom,mdss-dsi-lane-3-state;
				qcom,mdss-dsi-panel-timings = <0xe7362400 0x666a2a3a 0x2d030400>;
				qcom,mdss-dsi-t-clk-post = <0x04>;
				qcom,mdss-dsi-t-clk-pre = <0x1b>;
				qcom,mdss-dsi-bl-min-level = <0x01>;
				qcom,mdss-dsi-bl-max-level = <0xfff>;
				qcom,mdss-dsi-dma-trigger = "trigger_sw";
				qcom,mdss-dsi-mdp-trigger = "none";
				qcom,mdss-dsi-bl-pmic-control-type = "bl_ctrl_wled";
				qcom,mdss-dsi-reset-sequence = <0x01 0x0a 0x00 0x0a 0x01 0x0a>;
				qcom,mdss-pan-physical-width-dimension = <0x3d>;
				qcom,mdss-pan-physical-height-dimension = <0x6e>;
				qcom,cont-splash-enabled;
			};

			qcom,mdss_dsi_sharp_1080p_cmd {
				qcom,mdss-dsi-panel-name = "sharp 1080p cmd mode dsi panel";
				qcom,mdss-dsi-panel-controller = <0x2b>;
				qcom,mdss-dsi-panel-type = "dsi_cmd_mode";
				qcom,mdss-dsi-panel-destination = "display_1";
				qcom,mdss-dsi-panel-framerate = <0x46>;
				qcom,mdss-dsi-virtual-channel-id = <0x00>;
				qcom,mdss-dsi-stream = <0x00>;
				qcom,mdss-dsi-panel-width = <0x438>;
				qcom,mdss-dsi-panel-height = <0x780>;
				qcom,mdss-dsi-h-front-porch = <0x00>;
				qcom,mdss-dsi-h-back-porch = <0x00>;
				qcom,mdss-dsi-h-pulse-width = <0x00>;
				qcom,mdss-dsi-h-sync-skew = <0x00>;
				qcom,mdss-dsi-v-back-porch = <0x00>;
				qcom,mdss-dsi-v-front-porch = <0x00>;
				qcom,mdss-dsi-v-pulse-width = <0x00>;
				qcom,mdss-dsi-h-left-border = <0x00>;
				qcom,mdss-dsi-h-right-border = <0x00>;
				qcom,mdss-dsi-v-top-border = <0x00>;
				qcom,mdss-dsi-v-bottom-border = <0x00>;
				qcom,mdss-dsi-bpp = <0x18>;
				qcom,mdss-dsi-underflow-color = <0xff>;
				qcom,mdss-dsi-border-color = <0x00>;
				qcom,mdss-dsi-reset-sequence = <0x01 0x0a 0x00 0x0a 0x01 0x0a>;
				qcom,mdss-dsi-on-command = [15 01 00 00 00 00 02 bb 10 15 01 00 00 00 00 02 b0 03 05 01 00 00 78 00 01 11 15 01 00 00 00 00 02 51 ff 15 01 00 00 00 00 02 53 24 15 01 00 00 00 00 02 ff 23 15 01 00 00 00 00 02 08 05 15 01 00 00 00 00 02 46 90 15 01 00 00 00 00 02 ff 10 15 01 00 00 00 00 02 ff f0 15 01 00 00 00 00 02 92 01 15 01 00 00 00 00 02 ff 10 05 01 00 00 28 00 01 29];
				qcom,mdss-dsi-off-command = <0x5010000 0x10000128 0x5010000 0x40000110>;
				qcom,mdss-dsi-on-command-state = "dsi_lp_mode";
				qcom,mdss-dsi-off-command-state = "dsi_hs_mode";
				qcom,mdss-dsi-h-sync-pulse = <0x00>;
				qcom,mdss-dsi-traffic-mode = "burst_mode";
				qcom,mdss-dsi-bllp-eof-power-mode;
				qcom,mdss-dsi-bllp-power-mode;
				qcom,mdss-dsi-lane-0-state;
				qcom,mdss-dsi-lane-1-state;
				qcom,mdss-dsi-lane-2-state;
				qcom,mdss-dsi-lane-3-state;
				qcom,mdss-dsi-panel-timings = <0xe7362400 0x666a2a3a 0x2d030400>;
				qcom,mdss-dsi-t-clk-post = <0x04>;
				qcom,mdss-dsi-t-clk-pre = <0x1b>;
				qcom,mdss-dsi-dma-trigger = "trigger_sw";
				qcom,mdss-dsi-mdp-trigger = "none";
				qcom,mdss-dsi-bl-pmic-control-type = "bl_ctrl_wled";
				qcom,mdss-dsi-te-pin-select = <0x01>;
				qcom,mdss-dsi-wr-mem-start = <0x2c>;
				qcom,mdss-dsi-wr-mem-continue = <0x3c>;
				qcom,mdss-dsi-te-dcs-command = <0x01>;
				qcom,mdss-dsi-te-check-enable;
				qcom,mdss-dsi-te-using-te-pin;
				qcom,mdss-dsi-bl-min-level = <0x01>;
				qcom,mdss-dsi-bl-max-level = <0xfff>;
				qcom,cont-splash-enabled;
			};

			somc,jdi_novatek_fullhd_cmd_panel {
				qcom,mdss-dsi-panel-name = [37 00];
				qcom,mdss-dsi-panel-controller = <0x2b>;
				qcom,mdss-dsi-panel-destination = "display_1";
				qcom,mdss-dsi-panel-type = "dsi_cmd_mode";
				qcom,mdss-dsi-panel-width = <0x438>;
				qcom,mdss-dsi-panel-height = <0x780>;
				qcom,mdss-dsi-bpp = <0x18>;
				qcom,mdss-dsi-h-back-porch = <0x08>;
				qcom,mdss-dsi-h-pulse-width = <0x08>;
				qcom,mdss-dsi-h-front-porch = <0x38>;
				qcom,mdss-dsi-v-back-porch = <0x08>;
				qcom,mdss-dsi-v-pulse-width = <0x02>;
				qcom,mdss-dsi-v-front-porch = <0xe9>;
				qcom,mdss-pan-physical-width-dimension = <0x40>;
				qcom,mdss-pan-physical-height-dimension = <0x72>;
				qcom,mdss-dsi-panel-framerate = <0x3c>;
				qcom,mdss-dsi-virtual-channel-id = <0x00>;
				qcom,mdss-dsi-stream = <0x00>;
				qcom,mdss-dsi-h-sync-skew = <0x00>;
				qcom,mdss-dsi-h-left-border = <0x00>;
				qcom,mdss-dsi-h-right-border = <0x00>;
				qcom,mdss-dsi-v-top-border = <0x00>;
				qcom,mdss-dsi-v-bottom-border = <0x00>;
				qcom,mdss-dsi-underflow-color = <0x00>;
				qcom,mdss-dsi-border-color = <0x00>;
				qcom,mdss-dsi-h-sync-pulse = <0x01>;
				qcom,mdss-dsi-traffic-mode = "non_burst_sync_event";
				qcom,mdss-dsi-bllp-eof-power-mode;
				qcom,mdss-dsi-bllp-power-mode;
				qcom,mdss-dsi-dma-trigger = "trigger_sw";
				qcom,mdss-dsi-mdp-trigger = "none";
				somc,mdss-dsi-init-command = [23 01 00 00 00 00 02 ff 10 05 01 00 00 14 00 01 01 23 01 00 00 00 00 02 fb 01 15 01 00 00 00 00 02 bb 10 15 01 00 00 00 00 02 35 00 39 01 00 00 00 00 03 44 03 00 39 01 00 00 00 00 04 3b 03 08 08 23 01 00 00 00 00 02 ff e0 23 01 00 00 00 00 02 b5 86 23 01 00 00 00 00 02 b6 77 23 01 00 00 00 00 02 b8 ad 23 01 00 00 00 00 02 fb 01 23 01 00 00 00 00 02 ff 24 23 01 00 00 00 00 02 fb 01 23 01 00 00 00 00 02 92 8e 23 01 00 00 00 00 02 ff 10 23 01 00 00 01 00 02 fb 01 05 01 00 00 00 00 01 29];
				qcom,mdss-dsi-on-command = <0x5010000 0xa000111>;
				qcom,mdss-dsi-off-command = <0x5010000 0x14000128 0x5010000 0x50000110>;
				qcom,mdss-dsi-on-command-state = "dsi_lp_mode";
				qcom,mdss-dsi-off-command-state = "dsi_hs_mode";
				qcom,mdss-dsi-te-pin-select = <0x01>;
				qcom,mdss-dsi-wr-mem-start = <0x2c>;
				qcom,mdss-dsi-wr-mem-continue = <0x3c>;
				qcom,mdss-dsi-te-dcs-command = <0x01>;
				qcom,mdss-dsi-te-check-enable;
				qcom,mdss-dsi-te-using-te-pin;
				qcom,mdss-dsi-lane-0-state;
				qcom,mdss-dsi-lane-1-state;
				qcom,mdss-dsi-lane-2-state;
				qcom,mdss-dsi-lane-3-state;
				qcom,mdss-dsi-panel-timings = <0xe6382600 0x6866323c 0x2c030400>;
				qcom,mdss-dsi-t-clk-post = <0x21>;
				qcom,mdss-dsi-t-clk-pre = <0x2b>;
				qcom,mdss-dsi-tx-eot-append;
				qcom,mdss-dsi-lp11-init;
				qcom,mdss-dsi-bl-min-level = <0x01>;
				qcom,mdss-dsi-bl-max-level = <0xfff>;
				qcom,mdss-brightness-max-level = <0xfff>;
				qcom,mdss-dsi-bl-pmic-control-type = "bl_ctrl_wled";
				qcom,qpnp-lab-limit-maximum-current = <0xc8>;
				qcom,qpnp-ibb-limit-maximum-current = <0x320>;
				somc,mdss-dsi-disp-on-in-hs = <0x00>;
				somc,mdss-dsi-wait-time-before-on-cmd = <0x00>;
				somc,platform-regulator-settings = [03 03 03 00 20 00 01];
				somc,mdss-dsi-lane-config = [02 00 ef 00 20 00 00 01 ff 02 00 ef 00 40 00 00 01 ff 02 00 ef 40 20 00 00 01 ff 02 00 ef 40 00 00 00 01 ff 00 00 45 80 00 00 00 01 97];
				somc,pw-on-rst-seq = <0x00 0x14 0x01 0x0f>;
				somc,disp-en-off-post = <0x46>;
				somc,pw-off-rst-seq = <0x00 0x00>;
				somc,pw-down-period = <0x64>;
				somc,lab-output-voltage = <0x5265c0>;
				somc,ibb-output-voltage = <0x5265c0>;
				somc,lcd-id = <0x01>;
				somc,lcd-id-adc = <0x562e8 0x65130>;
				somc,mdss-dsi-master;
				somc,change-fps-enable;
				somc,change-fps-command = [15 01 00 00 00 00 02 ff 24 15 01 00 00 00 00 02 92 8e 15 01 00 00 00 00 02 ff 10 39 01 00 00 00 00 03 44 03 00];
				somc,display-clock = <0xfe3620>;
				somc,driver-ic-vbp = <0x08>;
				somc,driver-ic-vfp = <0x08>;
				somc,change-fps-rtn-adj;
				somc,change-fps-rtn-pos = <0x01 0x01>;
				somc,fps-threshold = <0xb928>;
				somc,te-c-mode-60fps = <0x03 0x00>;
				somc,te-c-mode-45fps = <0x04 0xff>;
				somc,te-c-mode-pos = <0x03 0x01>;
				somc,mdss-dsi-lock-command = [15 01 00 00 00 00 02 ff 10 15 01 00 00 00 00 02 fb 01 15 01 00 00 00 00 02 f0 55 15 01 00 00 00 00 02 f1 aa 15 01 00 00 01 00 02 f2 66];
				somc,mdss-dsi-unlock-command = [15 01 00 00 00 00 02 ff 10 15 01 00 00 00 00 02 fb 01 15 01 00 00 00 00 02 f0 aa 15 01 00 00 00 00 02 f1 55 15 01 00 00 01 00 02 f2 99];
				somc,mdss-dsi-pcc-enable;
				somc,mdss-dsi-uv-command = <0x6010000 0x1da 0x6010000 0x1db>;
				somc,mdss-dsi-uv-param-type = <0x04>;
				somc,mdss-dsi-pcc-table-size = <0xe1>;
				somc,mdss-dsi-pcc-table = <0x00 0x01 0x38 0x3b 0x38 0x3b 0x5180 0x7000 0x8000 0x00 0x02 0x34 0x37 0x38 0x3b 0x5500 0x7000 0x8000 0x00 0x03 0x30 0x33 0x38 0x3b 0x5880 0x6f80 0x8000 0x00 0x04 0x2c 0x2f 0x38 0x3b 0x5d00 0x6f00 0x8000 0x00 0x05 0x28 0x2b 0x38 0x3b 0x6080 0x6e80 0x8000 0x00 0x06 0x24 0x27 0x38 0x3b 0x6500 0x6e80 0x8000 0x00 0x07 0x20 0x23 0x38 0x3b 0x6880 0x6e00 0x8000 0x00 0x08 0x1c 0x1f 0x38 0x3b 0x6b80 0x6d80 0x8000 0x00 0x09 0x18 0x1b 0x38 0x3b 0x6f00 0x6d80 0x8000 0x00 0x0a 0x14 0x17 0x38 0x3b 0x7400 0x6d00 0x8000 0x00 0x0b 0x10 0x13 0x38 0x3b 0x7b80 0x6d00 0x8000 0x00 0x0c 0x0c 0x0f 0x38 0x3b 0x8000 0x6c00 0x8000 0x00 0x0d 0x08 0x0b 0x38 0x3b 0x8000 0x6680 0x7900 0x00 0x0e 0x04 0x07 0x38 0x3b 0x8000 0x5f80 0x7200 0x00 0x0f 0x00 0x03 0x38 0x3b 0x8000 0x5780 0x6980 0x00 0x10 0x38 0x3b 0x34 0x37 0x5600 0x7380 0x8000 0x00 0x11 0x34 0x37 0x34 0x37 0x5980 0x7300 0x8000 0x00 0x12 0x30 0x33 0x34 0x37 0x5d80 0x7300 0x8000 0x00 0x13 0x2c 0x2f 0x34 0x37 0x6100 0x7280 0x8000 0x00 0x14 0x28 0x2b 0x34 0x37 0x6500 0x7200 0x8000 0x00 0x15 0x24 0x27 0x34 0x37 0x6880 0x7180 0x8000 0x00 0x16 0x20 0x23 0x34 0x37 0x6b80 0x7100 0x8000 0x00 0x17 0x1c 0x1f 0x34 0x37 0x6e80 0x7080 0x8000 0x00 0x18 0x18 0x1b 0x34 0x37 0x7300 0x7080 0x8000 0x00 0x19 0x14 0x17 0x34 0x37 0x7a00 0x7000 0x8000 0x00 0x1a 0x10 0x13 0x34 0x37 0x7e80 0x6f80 0x8000 0x00 0x1b 0x0c 0x0f 0x34 0x37 0x8000 0x6b00 0x7c80 0x00 0x1c 0x08 0x0b 0x34 0x37 0x8000 0x6500 0x7500 0x00 0x1d 0x04 0x07 0x34 0x37 0x8000 0x5d80 0x6d80 0x00 0x1e 0x00 0x03 0x34 0x37 0x8000 0x5500 0x6500 0x00 0x1f 0x38 0x3b 0x30 0x33 0x5a00 0x7700 0x8000 0x00 0x20 0x34 0x37 0x30 0x33 0x5e00 0x7600 0x8000 0x00 0x21 0x30 0x33 0x30 0x33 0x6100 0x7580 0x8000 0x00 0x22 0x2c 0x2f 0x30 0x33 0x6500 0x7500 0x8000 0x00 0x23 0x28 0x2b 0x30 0x33 0x6880 0x7480 0x8000 0x00 0x24 0x24 0x27 0x30 0x33 0x6b80 0x7400 0x8000 0x00 0x25 0x20 0x23 0x30 0x33 0x6e80 0x7380 0x8000 0x00 0x26 0x1c 0x1f 0x30 0x33 0x7200 0x7380 0x8000 0x00 0x27 0x18 0x1b 0x30 0x33 0x7880 0x7300 0x8000 0x00 0x28 0x14 0x17 0x30 0x33 0x7d80 0x7300 0x8000 0x00 0x29 0x10 0x13 0x30 0x33 0x8000 0x7080 0x7e80 0x00 0x2a 0x0c 0x0f 0x30 0x33 0x8000 0x6a80 0x7780 0x00 0x2b 0x08 0x0b 0x30 0x33 0x8000 0x6400 0x7180 0x00 0x2c 0x04 0x07 0x30 0x33 0x8000 0x5c00 0x6980 0x00 0x2d 0x00 0x03 0x30 0x33 0x8000 0x5280 0x6100 0x00 0x2e 0x38 0x3b 0x2c 0x2f 0x5e00 0x7a80 0x8000 0x00 0x2f 0x34 0x37 0x2c 0x2f 0x6180 0x7a00 0x8000 0x00 0x30 0x30 0x33 0x2c 0x2f 0x6580 0x7900 0x8000 0x00 0x31 0x2c 0x2f 0x2c 0x2f 0x6880 0x7880 0x8000 0x00 0x32 0x28 0x2b 0x2c 0x2f 0x6b00 0x7800 0x8000 0x00 0x33 0x24 0x27 0x2c 0x2f 0x6e00 0x7780 0x8000 0x00 0x34 0x20 0x23 0x2c 0x2f 0x7180 0x7700 0x8000 0x00 0x35 0x1c 0x1f 0x2c 0x2f 0x7780 0x7680 0x8000 0x00 0x36 0x18 0x1b 0x2c 0x2f 0x7c80 0x7600 0x8000 0x00 0x37 0x14 0x17 0x2c 0x2f 0x8000 0x7500 0x7f80 0x00 0x38 0x10 0x13 0x2c 0x2f 0x8000 0x7000 0x7a80 0x00 0x39 0x0c 0x0f 0x2c 0x2f 0x8000 0x6980 0x7400 0x00 0x3a 0x08 0x0b 0x2c 0x2f 0x8000 0x6280 0x6d80 0x00 0x3b 0x04 0x07 0x2c 0x2f 0x8000 0x5980 0x6600 0x00 0x3c 0x00 0x03 0x2c 0x2f 0x8000 0x5000 0x5d80 0x00 0x3d 0x38 0x3b 0x28 0x2b 0x6180 0x7e80 0x8000 0x00 0x3e 0x34 0x37 0x28 0x2b 0x6580 0x7e00 0x8000 0x00 0x3f 0x30 0x33 0x28 0x2b 0x6800 0x7d00 0x8000 0x00 0x40 0x2c 0x2f 0x28 0x2b 0x6a80 0x7c80 0x8000 0x00 0x41 0x28 0x2b 0x28 0x2b 0x6d80 0x7c00 0x8000 0x00 0x42 0x24 0x27 0x28 0x2b 0x7100 0x7b00 0x8000 0x00 0x43 0x20 0x23 0x28 0x2b 0x7600 0x7a80 0x8000 0x00 0x44 0x1c 0x1f 0x28 0x2b 0x7b80 0x7900 0x8000 0x00 0x45 0x18 0x1b 0x28 0x2b 0x7f80 0x7880 0x8000 0x00 0x46 0x14 0x17 0x28 0x2b 0x8000 0x7480 0x7c80 0x00 0x47 0x10 0x13 0x28 0x2b 0x8000 0x6f00 0x7680 0x00 0x48 0x0c 0x0f 0x28 0x2b 0x8000 0x6880 0x7100 0x00 0x49 0x08 0x0b 0x28 0x2b 0x8000 0x6080 0x6a80 0x00 0x4a 0x04 0x07 0x28 0x2b 0x8000 0x5780 0x6300 0x00 0x4b 0x00 0x03 0x28 0x2b 0x8000 0x4d00 0x5a00 0x00 0x4c 0x38 0x3b 0x24 0x27 0x6300 0x8000 0x7e80 0x00 0x4d 0x34 0x37 0x24 0x27 0x6780 0x8000 0x7f80 0x00 0x4e 0x30 0x33 0x24 0x27 0x6a80 0x8000 0x8000 0x00 0x4f 0x2c 0x2f 0x24 0x27 0x6d00 0x7f80 0x8000 0x00 0x50 0x28 0x2b 0x24 0x27 0x7000 0x7f00 0x8000 0x00 0x51 0x24 0x27 0x24 0x27 0x7400 0x7e80 0x8000 0x00 0x52 0x20 0x23 0x24 0x27 0x7a80 0x7e00 0x8000 0x00 0x53 0x1c 0x1f 0x24 0x27 0x7e00 0x7d00 0x8000 0x00 0x54 0x18 0x1b 0x24 0x27 0x8000 0x7a00 0x7e00 0x00 0x55 0x14 0x17 0x24 0x27 0x8000 0x7400 0x7880 0x00 0x56 0x10 0x13 0x24 0x27 0x8000 0x6e80 0x7380 0x00 0x57 0x0c 0x0f 0x24 0x27 0x8000 0x6780 0x6e00 0x00 0x58 0x08 0x0b 0x24 0x27 0x8000 0x5f00 0x6700 0x00 0x59 0x04 0x07 0x24 0x27 0x8000 0x5580 0x5f80 0x00 0x5a 0x00 0x03 0x24 0x27 0x8000 0x4a00 0x5700 0x00 0x5b 0x38 0x3b 0x20 0x23 0x6180 0x8000 0x7b00 0x00 0x5c 0x34 0x37 0x20 0x23 0x6680 0x8000 0x7c80 0x00 0x5d 0x30 0x33 0x20 0x23 0x6a00 0x8000 0x7d00 0x00 0x5e 0x2c 0x2f 0x20 0x23 0x6d00 0x8000 0x7e00 0x00 0x5f 0x28 0x2b 0x20 0x23 0x7100 0x8000 0x7e80 0x00 0x60 0x24 0x27 0x20 0x23 0x7800 0x8000 0x7f00 0x00 0x61 0x20 0x23 0x20 0x23 0x7d00 0x8000 0x8000 0x00 0x62 0x1c 0x1f 0x20 0x23 0x8000 0x7f00 0x7f80 0x00 0x63 0x18 0x1b 0x20 0x23 0x8000 0x7900 0x7b00 0x00 0x64 0x14 0x17 0x20 0x23 0x8000 0x7380 0x7600 0x00 0x65 0x10 0x13 0x20 0x23 0x8000 0x6d80 0x7100 0x00 0x66 0x0c 0x0f 0x20 0x23 0x8000 0x6600 0x6b00 0x00 0x67 0x08 0x0b 0x20 0x23 0x8000 0x5d80 0x6400 0x00 0x68 0x04 0x07 0x20 0x23 0x8000 0x5400 0x5d00 0x00 0x69 0x00 0x03 0x20 0x23 0x8000 0x4680 0x5480 0x00 0x6a 0x38 0x3b 0x1c 0x1f 0x6080 0x8000 0x7780 0x00 0x6b 0x34 0x37 0x1c 0x1f 0x6580 0x8000 0x7880 0x00 0x6c 0x30 0x33 0x1c 0x1f 0x6900 0x8000 0x7980 0x00 0x6d 0x2c 0x2f 0x1c 0x1f 0x6d00 0x8000 0x7a80 0x00 0x6e 0x28 0x2b 0x1c 0x1f 0x7080 0x8000 0x7c00 0x00 0x6f 0x24 0x27 0x1c 0x1f 0x7780 0x8000 0x7c80 0x00 0x70 0x20 0x23 0x1c 0x1f 0x7d00 0x8000 0x7d00 0x00 0x71 0x18 0x1b 0x1c 0x1f 0x8000 0x7900 0x7800 0x00 0x72 0x14 0x17 0x1c 0x1f 0x8000 0x7300 0x7380 0x00 0x73 0x10 0x13 0x1c 0x1f 0x8000 0x6d00 0x6e80 0x00 0x74 0x0c 0x0f 0x1c 0x1f 0x8000 0x6500 0x6880 0x00 0x75 0x08 0x0b 0x1c 0x1f 0x8000 0x5c00 0x6200 0x00 0x76 0x04 0x07 0x1c 0x1f 0x8000 0x5180 0x5a00 0x00 0x77 0x00 0x03 0x1c 0x1f 0x8000 0x4300 0x5200 0x00 0x78 0x38 0x3b 0x18 0x1b 0x5f80 0x8000 0x7500 0x00 0x79 0x34 0x37 0x18 0x1b 0x6480 0x8000 0x7600 0x00 0x7a 0x30 0x33 0x18 0x1b 0x6900 0x8000 0x7680 0x00 0x7b 0x2c 0x2f 0x18 0x1b 0x6c00 0x8000 0x7780 0x00 0x7c 0x28 0x2b 0x18 0x1b 0x7000 0x8000 0x7880 0x00 0x7d 0x24 0x27 0x18 0x1b 0x7600 0x8000 0x7900 0x00 0x7e 0x20 0x23 0x18 0x1b 0x7c80 0x8000 0x7980 0x00 0x7f 0x1c 0x1f 0x18 0x1b 0x8000 0x7f00 0x7980 0x00 0x80 0x18 0x1b 0x18 0x1b 0x8000 0x7880 0x7580 0x00 0x81 0x14 0x17 0x18 0x1b 0x8000 0x7300 0x7100 0x00 0x82 0x10 0x13 0x18 0x1b 0x8000 0x6c00 0x6b80 0x00 0x83 0x0c 0x0f 0x18 0x1b 0x8000 0x6400 0x6600 0x00 0x84 0x08 0x0b 0x18 0x1b 0x8000 0x5a00 0x5f80 0x00 0x85 0x04 0x07 0x18 0x1b 0x8000 0x4f00 0x5800 0x00 0x86 0x00 0x03 0x18 0x1b 0x8000 0x3f80 0x4f80 0x00 0x87 0x38 0x3b 0x14 0x17 0x5e00 0x8000 0x7200 0x00 0x88 0x34 0x37 0x14 0x17 0x6300 0x8000 0x7300 0x00 0x89 0x30 0x33 0x14 0x17 0x6800 0x8000 0x7400 0x00 0x8a 0x2c 0x2f 0x14 0x17 0x6b80 0x8000 0x7500 0x00 0x8b 0x28 0x2b 0x14 0x17 0x6f80 0x8000 0x7600 0x00 0x8c 0x24 0x27 0x14 0x17 0x7500 0x8000 0x7680 0x00 0x8d 0x20 0x23 0x14 0x17 0x7c80 0x8000 0x7780 0x00 0x8e 0x1c 0x1f 0x14 0x17 0x8000 0x7f00 0x7780 0x00 0x8f 0x18 0x1b 0x14 0x17 0x8000 0x7880 0x7380 0x00 0x90 0x14 0x17 0x14 0x17 0x8000 0x7280 0x6f00 0x00 0x91 0x10 0x13 0x14 0x17 0x8000 0x6b00 0x6980 0x00 0x92 0x0c 0x0f 0x14 0x17 0x8000 0x6280 0x6380 0x00 0x93 0x08 0x0b 0x14 0x17 0x8000 0x5880 0x5d80 0x00 0x94 0x04 0x07 0x14 0x17 0x8000 0x4c00 0x5600 0x00 0x95 0x00 0x03 0x14 0x17 0x8000 0x3b00 0x4d00 0x00 0x96 0x38 0x3b 0x10 0x13 0x5d00 0x8000 0x7000 0x00 0x97 0x34 0x37 0x10 0x13 0x6200 0x8000 0x7100 0x00 0x98 0x30 0x33 0x10 0x13 0x6780 0x8000 0x7200 0x00 0x99 0x2c 0x2f 0x10 0x13 0x6b00 0x8000 0x7300 0x00 0x9a 0x28 0x2b 0x10 0x13 0x6f00 0x8000 0x7380 0x00 0x9b 0x24 0x27 0x10 0x13 0x7500 0x8000 0x7480 0x00 0x9c 0x20 0x23 0x10 0x13 0x7c80 0x8000 0x7580 0x00 0x9d 0x1c 0x1f 0x10 0x13 0x8000 0x7f80 0x7580 0x00 0x9e 0x18 0x1b 0x10 0x13 0x8000 0x7880 0x7180 0x00 0x9f 0x14 0x17 0x10 0x13 0x8000 0x7200 0x6c00 0x00 0xa0 0x10 0x13 0x10 0x13 0x8000 0x6a80 0x6780 0x00 0xa1 0x0c 0x0f 0x10 0x13 0x8000 0x6180 0x6200 0x00 0xa2 0x08 0x0b 0x10 0x13 0x8000 0x5680 0x5b00 0x00 0xa3 0x04 0x07 0x10 0x13 0x8000 0x4980 0x5400 0x00 0xa4 0x00 0x03 0x10 0x13 0x8000 0x3680 0x4a80 0x00 0xa5 0x38 0x3b 0x0c 0x0f 0x5b00 0x8000 0x6d80 0x00 0xa6 0x34 0x37 0x0c 0x0f 0x6080 0x8000 0x6e80 0x00 0xa7 0x30 0x33 0x0c 0x0f 0x6680 0x8000 0x6f80 0x00 0xa8 0x2c 0x2f 0x0c 0x0f 0x6a80 0x8000 0x7080 0x00 0xa9 0x28 0x2b 0x0c 0x0f 0x6e80 0x8000 0x7180 0x00 0xaa 0x24 0x27 0x0c 0x0f 0x7400 0x8000 0x7280 0x00 0xab 0x20 0x23 0x0c 0x0f 0x7c00 0x8000 0x7380 0x00 0xac 0x1c 0x1f 0x0c 0x0f 0x8000 0x7f80 0x7380 0x00 0xad 0x18 0x1b 0x0c 0x0f 0x8000 0x7800 0x6f80 0x00 0xae 0x14 0x17 0x0c 0x0f 0x8000 0x7180 0x6b00 0x00 0xaf 0x10 0x13 0x0c 0x0f 0x8000 0x6980 0x6580 0x00 0xb0 0x0c 0x0f 0x0c 0x0f 0x8000 0x6000 0x6000 0x00 0xb1 0x08 0x0b 0x0c 0x0f 0x8000 0x5480 0x5980 0x00 0xb2 0x04 0x07 0x0c 0x0f 0x8000 0x4680 0x5280 0x00 0xb3 0x00 0x03 0x0c 0x0f 0x8000 0x3100 0x4880 0x00 0xb4 0x38 0x3b 0x08 0x0b 0x5980 0x8000 0x6b00 0x00 0xb5 0x34 0x37 0x08 0x0b 0x5f80 0x8000 0x6c00 0x00 0xb6 0x30 0x33 0x08 0x0b 0x6580 0x8000 0x6d80 0x00 0xb7 0x2c 0x2f 0x08 0x0b 0x6a00 0x8000 0x6e80 0x00 0xb8 0x28 0x2b 0x08 0x0b 0x6e80 0x8000 0x6f80 0x00 0xb9 0x24 0x27 0x08 0x0b 0x7380 0x8000 0x7080 0x00 0xba 0x20 0x23 0x08 0x0b 0x7c00 0x8000 0x7180 0x00 0xbb 0x1c 0x1f 0x08 0x0b 0x8000 0x7f80 0x7180 0x00 0xbc 0x18 0x1b 0x08 0x0b 0x8000 0x7800 0x6d80 0x00 0xbd 0x14 0x17 0x08 0x0b 0x8000 0x7100 0x6900 0x00 0xbe 0x10 0x13 0x08 0x0b 0x8000 0x6880 0x6400 0x00 0xbf 0x0c 0x0f 0x08 0x0b 0x8000 0x5e80 0x5e80 0x00 0xc0 0x08 0x0b 0x08 0x0b 0x8000 0x5380 0x5780 0x00 0xc1 0x04 0x07 0x08 0x0b 0x8000 0x4400 0x5080 0x00 0xc2 0x00 0x03 0x08 0x0b 0x8000 0x2b00 0x4680 0x00 0xc3 0x38 0x3b 0x04 0x07 0x5800 0x8000 0x6900 0x00 0xc4 0x34 0x37 0x04 0x07 0x5e80 0x8000 0x6a80 0x00 0xc5 0x30 0x33 0x04 0x07 0x6480 0x8000 0x6b00 0x00 0xc6 0x2c 0x2f 0x04 0x07 0x6980 0x8000 0x6d00 0x00 0xc7 0x28 0x2b 0x04 0x07 0x6d80 0x8000 0x6e00 0x00 0xc8 0x24 0x27 0x04 0x07 0x7300 0x8000 0x6f00 0x00 0xc9 0x20 0x23 0x04 0x07 0x7b80 0x8000 0x6f80 0x00 0xca 0x1c 0x1f 0x04 0x07 0x8000 0x7f80 0x7000 0x00 0xcb 0x18 0x1b 0x04 0x07 0x8000 0x7800 0x6b80 0x00 0xcc 0x14 0x17 0x04 0x07 0x8000 0x7080 0x6780 0x00 0xcd 0x10 0x13 0x04 0x07 0x8000 0x6800 0x6280 0x00 0xce 0x0c 0x0f 0x04 0x07 0x8000 0x5d80 0x5d00 0x00 0xcf 0x08 0x0b 0x04 0x07 0x8000 0x5180 0x5680 0x00 0xd0 0x04 0x07 0x04 0x07 0x8000 0x4080 0x4f00 0x00 0xd1 0x00 0x03 0x04 0x07 0x8000 0x2800 0x4500 0x00 0xd2 0x38 0x3b 0x00 0x03 0x5600 0x8000 0x6780 0x00 0xd3 0x34 0x37 0x00 0x03 0x5d00 0x8000 0x6880 0x00 0xd4 0x30 0x33 0x00 0x03 0x6300 0x8000 0x6a00 0x00 0xd5 0x2c 0x2f 0x00 0x03 0x6900 0x8000 0x6b00 0x00 0xd6 0x28 0x2b 0x00 0x03 0x6d00 0x8000 0x6b80 0x00 0xd7 0x24 0x27 0x00 0x03 0x7280 0x8000 0x6d00 0x00 0xd8 0x20 0x23 0x00 0x03 0x7b80 0x8000 0x6e00 0x00 0xd9 0x1c 0x1f 0x00 0x03 0x8000 0x7f80 0x6e80 0x00 0xda 0x18 0x1b 0x00 0x03 0x8000 0x7780 0x6a80 0x00 0xdb 0x14 0x17 0x00 0x03 0x8000 0x7000 0x6600 0x00 0xdc 0x10 0x13 0x00 0x03 0x8000 0x6700 0x6100 0x00 0xdd 0x0c 0x0f 0x00 0x03 0x8000 0x5c00 0x5b80 0x00 0xde 0x08 0x0b 0x00 0x03 0x8000 0x4f80 0x5480 0x00 0xdf 0x04 0x07 0x00 0x03 0x8000 0x3d00 0x4d00 0x00 0xe0 0x00 0x03 0x00 0x03 0x8000 0x2800 0x4380 0xff 0x00 0x00 0x3b 0x00 0x3b 0x8000 0x8000 0x8000>;
			};

			somc,lgd_novatek_fullhd_cmd_panel_ID9 {
				qcom,mdss-dsi-panel-name = [39 00];
				qcom,mdss-dsi-panel-controller = <0x2b>;
				qcom,mdss-dsi-panel-destination = "display_1";
				qcom,mdss-dsi-panel-type = "dsi_cmd_mode";
				qcom,mdss-dsi-panel-width = <0x438>;
				qcom,mdss-dsi-panel-height = <0x780>;
				qcom,mdss-dsi-bpp = <0x18>;
				qcom,mdss-dsi-h-back-porch = <0x08>;
				qcom,mdss-dsi-h-pulse-width = <0x08>;
				qcom,mdss-dsi-h-front-porch = <0x38>;
				qcom,mdss-dsi-v-back-porch = <0x08>;
				qcom,mdss-dsi-v-pulse-width = <0x02>;
				qcom,mdss-dsi-v-front-porch = <0xe9>;
				qcom,mdss-pan-physical-width-dimension = <0x40>;
				qcom,mdss-pan-physical-height-dimension = <0x72>;
				qcom,mdss-dsi-panel-framerate = <0x3c>;
				qcom,mdss-dsi-virtual-channel-id = <0x00>;
				qcom,mdss-dsi-stream = <0x00>;
				qcom,mdss-dsi-h-sync-skew = <0x00>;
				qcom,mdss-dsi-h-left-border = <0x00>;
				qcom,mdss-dsi-h-right-border = <0x00>;
				qcom,mdss-dsi-v-top-border = <0x00>;
				qcom,mdss-dsi-v-bottom-border = <0x00>;
				qcom,mdss-dsi-underflow-color = <0x00>;
				qcom,mdss-dsi-border-color = <0x00>;
				qcom,mdss-dsi-h-sync-pulse = <0x01>;
				qcom,mdss-dsi-traffic-mode = "non_burst_sync_event";
				qcom,mdss-dsi-bllp-eof-power-mode;
				qcom,mdss-dsi-bllp-power-mode;
				qcom,mdss-dsi-dma-trigger = "trigger_sw";
				qcom,mdss-dsi-mdp-trigger = "none";
				somc,mdss-dsi-init-command = [15 01 00 00 00 00 02 ff 20 15 01 00 00 00 00 02 fb 01 15 01 00 00 00 00 02 2d 94 15 01 00 00 00 00 02 60 05 15 01 00 00 00 00 02 ff e0 15 01 00 00 00 00 02 fb 01 15 01 00 00 00 00 02 b8 ad 15 01 00 00 00 00 02 b5 86 15 01 00 00 00 00 02 b6 77 15 01 00 00 00 00 02 ff 24 15 01 00 00 00 00 02 fb 01 15 01 00 00 00 00 02 c4 24 15 01 00 00 00 00 02 92 8e 15 01 00 00 00 00 02 ff 10 15 01 00 00 00 00 02 fb 01 15 01 00 00 00 00 02 35 00 39 01 00 00 00 00 03 44 03 00 05 01 00 00 1e 00 01 11];
				qcom,mdss-dsi-on-command = <0x5010000 0x129>;
				qcom,mdss-dsi-off-command = <0x5010000 0x14000128 0x5010000 0x64000110>;
				qcom,mdss-dsi-on-command-state = "dsi_lp_mode";
				qcom,mdss-dsi-off-command-state = "dsi_hs_mode";
				qcom,mdss-dsi-te-pin-select = <0x01>;
				qcom,mdss-dsi-wr-mem-start = <0x2c>;
				qcom,mdss-dsi-wr-mem-continue = <0x3c>;
				qcom,mdss-dsi-te-dcs-command = <0x01>;
				qcom,mdss-dsi-te-check-enable;
				qcom,mdss-dsi-te-using-te-pin;
				qcom,mdss-dsi-lane-0-state;
				qcom,mdss-dsi-lane-1-state;
				qcom,mdss-dsi-lane-2-state;
				qcom,mdss-dsi-lane-3-state;
				qcom,mdss-dsi-panel-timings = <0xe6382600 0x6866323c 0x2c030400>;
				qcom,mdss-dsi-t-clk-post = <0x21>;
				qcom,mdss-dsi-t-clk-pre = <0x2b>;
				qcom,mdss-dsi-tx-eot-append;
				qcom,mdss-dsi-lp11-init;
				qcom,mdss-dsi-bl-min-level = <0x01>;
				qcom,mdss-dsi-bl-max-level = <0xfff>;
				qcom,mdss-brightness-max-level = <0xfff>;
				qcom,mdss-dsi-bl-pmic-control-type = "bl_ctrl_wled";
				qcom,qpnp-lab-limit-maximum-current = <0xc8>;
				qcom,qpnp-ibb-limit-maximum-current = <0x320>;
				somc,mdss-dsi-disp-on-in-hs = <0x00>;
				somc,mdss-dsi-wait-time-before-on-cmd = <0x00>;
				somc,platform-regulator-settings = [03 03 03 00 20 00 01];
				somc,mdss-dsi-lane-config = [02 00 ef 00 20 00 00 01 ff 02 00 ef 00 40 00 00 01 ff 02 00 ef 40 20 00 00 01 ff 02 00 ef 40 00 00 00 01 ff 00 00 45 80 00 00 00 01 97];
				somc,disp-en-on-pre = <0x01>;
				somc,pw-on-rst-seq = <0x00 0x14 0x01 0x0a 0x00 0x01 0x01 0x14>;
				somc,disp-en-off-post = <0x0a>;
				somc,pw-off-rst-seq = <0x00 0x01>;
				somc,pw-down-period = <0x64>;
				somc,lab-output-voltage = <0x56f9a0>;
				somc,ibb-output-voltage = <0x56f9a0>;
				somc,lcd-id = <0x01>;
				somc,lcd-id-adc = <0x00 0xdea8>;
				somc,mdss-dsi-master;
				somc,change-fps-enable;
				somc,change-fps-command = [15 01 00 00 00 00 02 ff 24 15 01 00 00 00 00 02 92 8e 15 01 00 00 00 00 02 ff 10 39 01 00 00 00 00 03 44 03 00];
				somc,display-clock = <0xfe3620>;
				somc,driver-ic-vbp = <0x04>;
				somc,driver-ic-vfp = <0x0a>;
				somc,change-fps-rtn-adj;
				somc,change-fps-rtn-pos = <0x01 0x01>;
				somc,fps-threshold = <0xb928>;
				somc,te-c-mode-60fps = <0x03 0x00>;
				somc,te-c-mode-45fps = <0x04 0xff>;
				somc,te-c-mode-pos = <0x03 0x01>;
				somc,mdss-dsi-lock-command = [15 01 00 00 00 00 02 ff 10 15 01 00 00 00 00 02 fb 01 15 01 00 00 00 00 02 f0 55 15 01 00 00 00 00 02 f1 aa 15 01 00 00 01 00 02 f2 66];
				somc,mdss-dsi-unlock-command = [15 01 00 00 00 00 02 ff 10 15 01 00 00 00 00 02 fb 01 15 01 00 00 00 00 02 f0 aa 15 01 00 00 00 00 02 f1 55 15 01 00 00 01 00 02 f2 99];
				somc,mdss-dsi-pcc-enable;
				somc,mdss-dsi-uv-command = <0x6010000 0x1da 0x6010000 0x1db>;
				somc,mdss-dsi-uv-param-type = <0x04>;
				somc,mdss-dsi-pcc-table-size = <0xe1>;
				somc,mdss-dsi-pcc-table = <0x00 0x01 0x38 0x3b 0x38 0x3b 0x8000 0x8000 0x8000 0x00 0x02 0x34 0x37 0x38 0x3b 0x8000 0x8000 0x8000 0x00 0x03 0x30 0x33 0x38 0x3b 0x8000 0x8000 0x8000 0x00 0x04 0x2c 0x2f 0x38 0x3b 0x8000 0x8000 0x8000 0x00 0x05 0x28 0x2b 0x38 0x3b 0x8000 0x8000 0x8000 0x00 0x06 0x24 0x27 0x38 0x3b 0x8000 0x8000 0x8000 0x00 0x07 0x20 0x23 0x38 0x3b 0x8000 0x8000 0x8000 0x00 0x08 0x1c 0x1f 0x38 0x3b 0x8000 0x8000 0x8000 0x00 0x09 0x18 0x1b 0x38 0x3b 0x8000 0x8000 0x8000 0x00 0x0a 0x14 0x17 0x38 0x3b 0x8000 0x8000 0x8000 0x00 0x0b 0x10 0x13 0x38 0x3b 0x8000 0x8000 0x8000 0x00 0x0c 0x0c 0x0f 0x38 0x3b 0x8000 0x8000 0x8000 0x00 0x0d 0x08 0x0b 0x38 0x3b 0x8000 0x8000 0x8000 0x00 0x0e 0x04 0x07 0x38 0x3b 0x8000 0x8000 0x8000 0x00 0x0f 0x00 0x03 0x38 0x3b 0x8000 0x8000 0x8000 0x00 0x10 0x38 0x3b 0x34 0x37 0x8000 0x8000 0x8000 0x00 0x11 0x34 0x37 0x34 0x37 0x8000 0x8000 0x8000 0x00 0x12 0x30 0x33 0x34 0x37 0x8000 0x8000 0x8000 0x00 0x13 0x2c 0x2f 0x34 0x37 0x8000 0x8000 0x8000 0x00 0x14 0x28 0x2b 0x34 0x37 0x8000 0x8000 0x8000 0x00 0x15 0x24 0x27 0x34 0x37 0x8000 0x8000 0x8000 0x00 0x16 0x20 0x23 0x34 0x37 0x8000 0x8000 0x8000 0x00 0x17 0x1c 0x1f 0x34 0x37 0x8000 0x8000 0x8000 0x00 0x18 0x18 0x1b 0x34 0x37 0x8000 0x8000 0x8000 0x00 0x19 0x14 0x17 0x34 0x37 0x8000 0x8000 0x8000 0x00 0x1a 0x10 0x13 0x34 0x37 0x8000 0x8000 0x8000 0x00 0x1b 0x0c 0x0f 0x34 0x37 0x8000 0x8000 0x8000 0x00 0x1c 0x08 0x0b 0x34 0x37 0x8000 0x8000 0x8000 0x00 0x1d 0x04 0x07 0x34 0x37 0x8000 0x8000 0x8000 0x00 0x1e 0x00 0x03 0x34 0x37 0x8000 0x8000 0x8000 0x00 0x1f 0x38 0x3b 0x30 0x33 0x8000 0x8000 0x8000 0x00 0x20 0x34 0x37 0x30 0x33 0x8000 0x8000 0x8000 0x00 0x21 0x30 0x33 0x30 0x33 0x6b80 0x7280 0x8000 0x00 0x22 0x2c 0x2f 0x30 0x33 0x6f80 0x7200 0x8000 0x00 0x23 0x28 0x2b 0x30 0x33 0x7380 0x7180 0x8000 0x00 0x24 0x24 0x27 0x30 0x33 0x7780 0x7100 0x8000 0x00 0x25 0x20 0x23 0x30 0x33 0x7300 0x7180 0x8000 0x00 0x26 0x1c 0x1f 0x30 0x33 0x7700 0x7100 0x8000 0x00 0x27 0x18 0x1b 0x30 0x33 0x7b80 0x7080 0x8000 0x00 0x28 0x14 0x17 0x30 0x33 0x7600 0x7180 0x8000 0x00 0x29 0x10 0x13 0x30 0x33 0x7b00 0x7100 0x8000 0x00 0x2a 0x0c 0x0f 0x30 0x33 0x7580 0x7180 0x8000 0x00 0x2b 0x08 0x0b 0x30 0x33 0x7a00 0x7100 0x8000 0x00 0x2c 0x04 0x07 0x30 0x33 0x8000 0x8000 0x8000 0x00 0x2d 0x00 0x03 0x30 0x33 0x8000 0x8000 0x8000 0x00 0x2e 0x38 0x3b 0x2c 0x2f 0x8000 0x8000 0x8000 0x00 0x2f 0x34 0x37 0x2c 0x2f 0x8000 0x8000 0x8000 0x00 0x30 0x30 0x33 0x2c 0x2f 0x6f80 0x7580 0x8000 0x00 0x31 0x2c 0x2f 0x2c 0x2f 0x7300 0x7500 0x8000 0x00 0x32 0x28 0x2b 0x2c 0x2f 0x7700 0x7480 0x8000 0x00 0x33 0x24 0x27 0x2c 0x2f 0x7b00 0x7400 0x8000 0x00 0x34 0x20 0x23 0x2c 0x2f 0x7600 0x7480 0x8000 0x00 0x35 0x1c 0x1f 0x2c 0x2f 0x7580 0x7480 0x8000 0x00 0x36 0x18 0x1b 0x2c 0x2f 0x7480 0x7480 0x8000 0x00 0x37 0x14 0x17 0x2c 0x2f 0x7900 0x7400 0x8000 0x00 0x38 0x10 0x13 0x2c 0x2f 0x7400 0x7500 0x8000 0x00 0x39 0x0c 0x0f 0x2c 0x2f 0x7800 0x7400 0x8000 0x00 0x3a 0x08 0x0b 0x2c 0x2f 0x7c80 0x7380 0x8000 0x00 0x3b 0x04 0x07 0x2c 0x2f 0x8000 0x8000 0x8000 0x00 0x3c 0x00 0x03 0x2c 0x2f 0x8000 0x8000 0x8000 0x00 0x3d 0x38 0x3b 0x28 0x2b 0x8000 0x8000 0x8000 0x00 0x3e 0x34 0x37 0x28 0x2b 0x8000 0x8000 0x8000 0x00 0x3f 0x30 0x33 0x28 0x2b 0x7300 0x7880 0x8000 0x00 0x40 0x2c 0x2f 0x28 0x2b 0x7600 0x7800 0x8000 0x00 0x41 0x28 0x2b 0x28 0x2b 0x7a80 0x7780 0x8000 0x00 0x42 0x24 0x27 0x28 0x2b 0x7500 0x7800 0x8000 0x00 0x43 0x20 0x23 0x28 0x2b 0x7900 0x7780 0x8000 0x00 0x44 0x1c 0x1f 0x28 0x2b 0x7880 0x7780 0x8000 0x00 0x45 0x18 0x1b 0x28 0x2b 0x7c00 0x7700 0x8000 0x00 0x46 0x14 0x17 0x28 0x2b 0x8000 0x7600 0x7f80 0x00 0x47 0x10 0x13 0x28 0x2b 0x8000 0x7680 0x8000 0x00 0x48 0x0c 0x0f 0x28 0x2b 0x7a80 0x7700 0x8000 0x00 0x49 0x08 0x0b 0x28 0x2b 0x7f00 0x7680 0x8000 0x00 0x4a 0x04 0x07 0x28 0x2b 0x8000 0x8000 0x8000 0x00 0x4b 0x00 0x03 0x28 0x2b 0x8000 0x8000 0x8000 0x00 0x4c 0x38 0x3b 0x24 0x27 0x8000 0x8000 0x8000 0x00 0x4d 0x34 0x37 0x24 0x27 0x8000 0x8000 0x8000 0x00 0x4e 0x30 0x33 0x24 0x27 0x7580 0x7b80 0x8000 0x00 0x4f 0x2c 0x2f 0x24 0x27 0x7980 0x7b00 0x8000 0x00 0x50 0x28 0x2b 0x24 0x27 0x7400 0x7b80 0x8000 0x00 0x51 0x24 0x27 0x24 0x27 0x7800 0x7b00 0x8000 0x00 0x52 0x20 0x23 0x24 0x27 0x7700 0x7b00 0x8000 0x00 0x53 0x1c 0x1f 0x24 0x27 0x7b80 0x7a80 0x8000 0x00 0x54 0x18 0x1b 0x24 0x27 0x7f00 0x7a00 0x8000 0x00 0x55 0x14 0x17 0x24 0x27 0x8000 0x7580 0x7c00 0x00 0x56 0x10 0x13 0x24 0x27 0x8000 0x7600 0x7d80 0x00 0x57 0x0c 0x0f 0x24 0x27 0x7c80 0x7a00 0x8000 0x00 0x58 0x08 0x0b 0x24 0x27 0x8000 0x7800 0x7f00 0x00 0x59 0x04 0x07 0x24 0x27 0x8000 0x8000 0x8000 0x00 0x5a 0x00 0x03 0x24 0x27 0x8000 0x8000 0x8000 0x00 0x5b 0x38 0x3b 0x20 0x23 0x8000 0x8000 0x8000 0x00 0x5c 0x34 0x37 0x20 0x23 0x8000 0x8000 0x8000 0x00 0x5d 0x30 0x33 0x20 0x23 0x7900 0x7e80 0x8000 0x00 0x5e 0x2c 0x2f 0x20 0x23 0x7380 0x7f80 0x8000 0x00 0x5f 0x28 0x2b 0x20 0x23 0x7700 0x7e80 0x8000 0x00 0x60 0x24 0x27 0x20 0x23 0x7600 0x7e80 0x8000 0x00 0x61 0x20 0x23 0x20 0x23 0x7a00 0x7e00 0x8000 0x00 0x62 0x1c 0x1f 0x20 0x23 0x7d80 0x7d80 0x8000 0x00 0x63 0x18 0x1b 0x20 0x23 0x8000 0x7b00 0x7e80 0x00 0x64 0x14 0x17 0x20 0x23 0x8000 0x7500 0x7980 0x00 0x65 0x10 0x13 0x20 0x23 0x8000 0x7600 0x7a00 0x00 0x66 0x0c 0x0f 0x20 0x23 0x7f00 0x7d00 0x8000 0x00 0x67 0x08 0x0b 0x20 0x23 0x8000 0x7780 0x7b80 0x00 0x68 0x04 0x07 0x20 0x23 0x8000 0x8000 0x8000 0x00 0x69 0x00 0x03 0x20 0x23 0x8000 0x8000 0x8000 0x00 0x6a 0x38 0x3b 0x1c 0x1f 0x8000 0x8000 0x8000 0x00 0x6b 0x34 0x37 0x1c 0x1f 0x8000 0x8000 0x8000 0x00 0x6c 0x30 0x33 0x1c 0x1f 0x7a80 0x8000 0x7f80 0x00 0x6d 0x2c 0x2f 0x1c 0x1f 0x7400 0x8000 0x7e80 0x00 0x6e 0x28 0x2b 0x1c 0x1f 0x7880 0x8000 0x7f00 0x00 0x6f 0x24 0x27 0x1c 0x1f 0x7700 0x8000 0x7f00 0x00 0x70 0x20 0x23 0x1c 0x1f 0x7c00 0x8000 0x7f80 0x00 0x71 0x18 0x1b 0x1c 0x1f 0x8000 0x7b00 0x7b80 0x00 0x72 0x14 0x17 0x1c 0x1f 0x8000 0x7500 0x7680 0x00 0x73 0x10 0x13 0x1c 0x1f 0x8000 0x7580 0x7700 0x00 0x74 0x0c 0x0f 0x1c 0x1f 0x8000 0x7e80 0x7f00 0x00 0x75 0x08 0x0b 0x1c 0x1f 0x8000 0x7700 0x7800 0x00 0x76 0x04 0x07 0x1c 0x1f 0x8000 0x8000 0x8000 0x00 0x77 0x00 0x03 0x1c 0x1f 0x8000 0x8000 0x8000 0x00 0x78 0x38 0x3b 0x18 0x1b 0x8000 0x8000 0x8000 0x00 0x79 0x34 0x37 0x18 0x1b 0x8000 0x8000 0x8000 0x00 0x7a 0x30 0x33 0x18 0x1b 0x7a00 0x8000 0x7c80 0x00 0x7b 0x2c 0x2f 0x18 0x1b 0x7e80 0x8000 0x7d80 0x00 0x7c 0x28 0x2b 0x18 0x1b 0x7780 0x8000 0x7c00 0x00 0x7d 0x24 0x27 0x18 0x1b 0x7680 0x8000 0x7c00 0x00 0x7e 0x20 0x23 0x18 0x1b 0x7b80 0x8000 0x7c80 0x00 0x7f 0x1c 0x1f 0x18 0x1b 0x8000 0x8000 0x7d80 0x00 0x80 0x18 0x1b 0x18 0x1b 0x8000 0x7b00 0x7980 0x00 0x81 0x14 0x17 0x18 0x1b 0x8000 0x7c00 0x7a00 0x00 0x82 0x10 0x13 0x18 0x1b 0x8000 0x7500 0x7480 0x00 0x83 0x0c 0x0f 0x18 0x1b 0x8000 0x7e80 0x7c00 0x00 0x84 0x08 0x0b 0x18 0x1b 0x8000 0x7680 0x7580 0x00 0x85 0x04 0x07 0x18 0x1b 0x8000 0x8000 0x8000 0x00 0x86 0x00 0x03 0x18 0x1b 0x8000 0x8000 0x8000 0x00 0x87 0x38 0x3b 0x14 0x17 0x8000 0x8000 0x8000 0x00 0x88 0x34 0x37 0x14 0x17 0x8000 0x8000 0x8000 0x00 0x89 0x30 0x33 0x14 0x17 0x7980 0x8000 0x7a00 0x00 0x8a 0x2c 0x2f 0x14 0x17 0x7e00 0x8000 0x7a80 0x00 0x8b 0x28 0x2b 0x14 0x17 0x7700 0x8000 0x7980 0x00 0x8c 0x24 0x27 0x14 0x17 0x7600 0x8000 0x7980 0x00 0x8d 0x20 0x23 0x14 0x17 0x7b00 0x8000 0x7a00 0x00 0x8e 0x1c 0x1f 0x14 0x17 0x8000 0x8000 0x7b00 0x00 0x8f 0x18 0x1b 0x14 0x17 0x8000 0x7b00 0x7680 0x00 0x90 0x14 0x17 0x14 0x17 0x8000 0x7c00 0x7780 0x00 0x91 0x10 0x13 0x14 0x17 0x7c80 0x8000 0x7a80 0x00 0x92 0x0c 0x0f 0x14 0x17 0x8000 0x7e00 0x7980 0x00 0x93 0x08 0x0b 0x14 0x17 0x8000 0x7580 0x7300 0x00 0x94 0x04 0x07 0x14 0x17 0x8000 0x8000 0x8000 0x00 0x95 0x00 0x03 0x14 0x17 0x8000 0x8000 0x8000 0x00 0x96 0x38 0x3b 0x10 0x13 0x8000 0x8000 0x8000 0x00 0x97 0x34 0x37 0x10 0x13 0x8000 0x8000 0x8000 0x00 0x98 0x30 0x33 0x10 0x13 0x7880 0x8000 0x7700 0x00 0x99 0x2c 0x2f 0x10 0x13 0x7d80 0x8000 0x7800 0x00 0x9a 0x28 0x2b 0x10 0x13 0x7680 0x8000 0x7680 0x00 0x9b 0x24 0x27 0x10 0x13 0x7580 0x8000 0x7680 0x00 0x9c 0x20 0x23 0x10 0x13 0x7b00 0x8000 0x7780 0x00 0x9d 0x1c 0x1f 0x10 0x13 0x7f80 0x8000 0x7800 0x00 0x9e 0x18 0x1b 0x10 0x13 0x8000 0x7b00 0x7480 0x00 0x9f 0x14 0x17 0x10 0x13 0x8000 0x7c00 0x7500 0x00 0xa0 0x10 0x13 0x10 0x13 0x7c80 0x8000 0x7800 0x00 0xa1 0x0c 0x0f 0x10 0x13 0x8000 0x7e00 0x7700 0x00 0xa2 0x08 0x0b 0x10 0x13 0x8000 0x7500 0x7080 0x00 0xa3 0x04 0x07 0x10 0x13 0x8000 0x8000 0x8000 0x00 0xa4 0x00 0x03 0x10 0x13 0x8000 0x8000 0x8000 0x00 0xa5 0x38 0x3b 0x0c 0x0f 0x8000 0x8000 0x8000 0x00 0xa6 0x34 0x37 0x0c 0x0f 0x8000 0x8000 0x8000 0x00 0xa7 0x30 0x33 0x0c 0x0f 0x7800 0x8000 0x7500 0x00 0xa8 0x2c 0x2f 0x0c 0x0f 0x7d00 0x8000 0x7580 0x00 0xa9 0x28 0x2b 0x0c 0x0f 0x7600 0x8000 0x7480 0x00 0xaa 0x24 0x27 0x0c 0x0f 0x7500 0x8000 0x7480 0x00 0xab 0x20 0x23 0x0c 0x0f 0x7a80 0x8000 0x7580 0x00 0xac 0x1c 0x1f 0x0c 0x0f 0x7f80 0x8000 0x7600 0x00 0xad 0x18 0x1b 0x0c 0x0f 0x7e80 0x8000 0x7600 0x00 0xae 0x14 0x17 0x0c 0x0f 0x7780 0x8000 0x7500 0x00 0xaf 0x10 0x13 0x0c 0x0f 0x7c80 0x8000 0x7600 0x00 0xb0 0x0c 0x0f 0x0c 0x0f 0x8000 0x7e00 0x7480 0x00 0xb1 0x08 0x0b 0x0c 0x0f 0x8000 0x7480 0x6e80 0x00 0xb2 0x04 0x07 0x0c 0x0f 0x8000 0x8000 0x8000 0x00 0xb3 0x00 0x03 0x0c 0x0f 0x8000 0x8000 0x8000 0x00 0xb4 0x38 0x3b 0x08 0x0b 0x8000 0x8000 0x8000 0x00 0xb5 0x34 0x37 0x08 0x0b 0x8000 0x8000 0x8000 0x00 0xb6 0x30 0x33 0x08 0x0b 0x7700 0x8000 0x7280 0x00 0xb7 0x2c 0x2f 0x08 0x0b 0x7c80 0x8000 0x7380 0x00 0xb8 0x28 0x2b 0x08 0x0b 0x8000 0x7e80 0x7380 0x00 0xb9 0x24 0x27 0x08 0x0b 0x7b00 0x8000 0x7380 0x00 0xba 0x20 0x23 0x08 0x0b 0x8000 0x8000 0x7480 0x00 0xbb 0x1c 0x1f 0x08 0x0b 0x7900 0x8000 0x7380 0x00 0xbc 0x18 0x1b 0x08 0x0b 0x7e00 0x8000 0x7400 0x00 0xbd 0x14 0x17 0x08 0x0b 0x7700 0x8000 0x7300 0x00 0xbe 0x10 0x13 0x08 0x0b 0x7c80 0x8000 0x7400 0x00 0xbf 0x0c 0x0f 0x08 0x0b 0x8000 0x7d80 0x7300 0x00 0xc0 0x08 0x0b 0x08 0x0b 0x8000 0x7400 0x6c80 0x00 0xc1 0x04 0x07 0x08 0x0b 0x8000 0x8000 0x8000 0x00 0xc2 0x00 0x03 0x08 0x0b 0x8000 0x8000 0x8000 0x00 0xc3 0x38 0x3b 0x04 0x07 0x8000 0x8000 0x8000 0x00 0xc4 0x34 0x37 0x04 0x07 0x8000 0x8000 0x8000 0x00 0xc5 0x30 0x33 0x04 0x07 0x8000 0x8000 0x8000 0x00 0xc6 0x2c 0x2f 0x04 0x07 0x8000 0x8000 0x8000 0x00 0xc7 0x28 0x2b 0x04 0x07 0x8000 0x8000 0x8000 0x00 0xc8 0x24 0x27 0x04 0x07 0x8000 0x8000 0x8000 0x00 0xc9 0x20 0x23 0x04 0x07 0x8000 0x8000 0x8000 0x00 0xca 0x1c 0x1f 0x04 0x07 0x8000 0x8000 0x8000 0x00 0xcb 0x18 0x1b 0x04 0x07 0x8000 0x8000 0x8000 0x00 0xcc 0x14 0x17 0x04 0x07 0x8000 0x8000 0x8000 0x00 0xcd 0x10 0x13 0x04 0x07 0x8000 0x8000 0x8000 0x00 0xce 0x0c 0x0f 0x04 0x07 0x8000 0x8000 0x8000 0x00 0xcf 0x08 0x0b 0x04 0x07 0x8000 0x8000 0x8000 0x00 0xd0 0x04 0x07 0x04 0x07 0x8000 0x8000 0x8000 0x00 0xd1 0x00 0x03 0x04 0x07 0x8000 0x8000 0x8000 0x00 0xd2 0x38 0x3b 0x00 0x03 0x8000 0x8000 0x8000 0x00 0xd3 0x34 0x37 0x00 0x03 0x8000 0x8000 0x8000 0x00 0xd4 0x30 0x33 0x00 0x03 0x8000 0x8000 0x8000 0x00 0xd5 0x2c 0x2f 0x00 0x03 0x8000 0x8000 0x8000 0x00 0xd6 0x28 0x2b 0x00 0x03 0x8000 0x8000 0x8000 0x00 0xd7 0x24 0x27 0x00 0x03 0x8000 0x8000 0x8000 0x00 0xd8 0x20 0x23 0x00 0x03 0x8000 0x8000 0x8000 0x00 0xd9 0x1c 0x1f 0x00 0x03 0x8000 0x8000 0x8000 0x00 0xda 0x18 0x1b 0x00 0x03 0x8000 0x8000 0x8000 0x00 0xdb 0x14 0x17 0x00 0x03 0x8000 0x8000 0x8000 0x00 0xdc 0x10 0x13 0x00 0x03 0x8000 0x8000 0x8000 0x00 0xdd 0x0c 0x0f 0x00 0x03 0x8000 0x8000 0x8000 0x00 0xde 0x08 0x0b 0x00 0x03 0x8000 0x8000 0x8000 0x00 0xdf 0x04 0x07 0x00 0x03 0x8000 0x8000 0x8000 0x00 0xe0 0x00 0x03 0x00 0x03 0x8000 0x8000 0x8000 0xff 0x00 0x00 0x3b 0x00 0x3b 0x8000 0x8000 0x8000>;
			};

			somc,lgd_novatek_fullhd_cmd_panel_ID2 {
				qcom,mdss-dsi-panel-name = [32 00];
				qcom,mdss-dsi-panel-controller = <0x2b>;
				qcom,mdss-dsi-panel-destination = "display_1";
				qcom,mdss-dsi-panel-type = "dsi_cmd_mode";
				qcom,mdss-dsi-panel-width = <0x438>;
				qcom,mdss-dsi-panel-height = <0x780>;
				qcom,mdss-dsi-bpp = <0x18>;
				qcom,mdss-dsi-h-back-porch = <0x08>;
				qcom,mdss-dsi-h-pulse-width = <0x08>;
				qcom,mdss-dsi-h-front-porch = <0x38>;
				qcom,mdss-dsi-v-back-porch = <0x08>;
				qcom,mdss-dsi-v-pulse-width = <0x02>;
				qcom,mdss-dsi-v-front-porch = <0xe9>;
				qcom,mdss-pan-physical-width-dimension = <0x40>;
				qcom,mdss-pan-physical-height-dimension = <0x72>;
				qcom,mdss-dsi-panel-framerate = <0x3c>;
				qcom,mdss-dsi-virtual-channel-id = <0x00>;
				qcom,mdss-dsi-stream = <0x00>;
				qcom,mdss-dsi-h-sync-skew = <0x00>;
				qcom,mdss-dsi-h-left-border = <0x00>;
				qcom,mdss-dsi-h-right-border = <0x00>;
				qcom,mdss-dsi-v-top-border = <0x00>;
				qcom,mdss-dsi-v-bottom-border = <0x00>;
				qcom,mdss-dsi-underflow-color = <0x00>;
				qcom,mdss-dsi-border-color = <0x00>;
				qcom,mdss-dsi-h-sync-pulse = <0x01>;
				qcom,mdss-dsi-traffic-mode = "non_burst_sync_event";
				qcom,mdss-dsi-bllp-eof-power-mode;
				qcom,mdss-dsi-bllp-power-mode;
				qcom,mdss-dsi-dma-trigger = "trigger_sw";
				qcom,mdss-dsi-mdp-trigger = "none";
				somc,mdss-dsi-init-command = [15 01 00 00 00 00 02 ff 20 15 01 00 00 00 00 02 fb 01 15 01 00 00 00 00 02 2d 94 15 01 00 00 00 00 02 ff e0 15 01 00 00 00 00 02 fb 01 15 01 00 00 00 00 02 b8 ad 15 01 00 00 00 00 02 b5 86 15 01 00 00 00 00 02 b6 77 15 01 00 00 00 00 02 ff 24 15 01 00 00 00 00 02 fb 01 15 01 00 00 00 00 02 c4 24 15 01 00 00 00 00 02 92 8e 15 01 00 00 00 00 02 ff 10 15 01 00 00 00 00 02 fb 01 15 01 00 00 00 00 02 35 00 39 01 00 00 00 00 03 44 03 00 05 01 00 00 1e 00 01 11];
				qcom,mdss-dsi-on-command = <0x5010000 0x129>;
				qcom,mdss-dsi-off-command = <0x5010000 0x14000128 0x5010000 0x64000110>;
				qcom,mdss-dsi-on-command-state = "dsi_lp_mode";
				qcom,mdss-dsi-off-command-state = "dsi_hs_mode";
				qcom,mdss-dsi-te-pin-select = <0x01>;
				qcom,mdss-dsi-wr-mem-start = <0x2c>;
				qcom,mdss-dsi-wr-mem-continue = <0x3c>;
				qcom,mdss-dsi-te-dcs-command = <0x01>;
				qcom,mdss-dsi-te-check-enable;
				qcom,mdss-dsi-te-using-te-pin;
				qcom,mdss-dsi-lane-0-state;
				qcom,mdss-dsi-lane-1-state;
				qcom,mdss-dsi-lane-2-state;
				qcom,mdss-dsi-lane-3-state;
				qcom,mdss-dsi-panel-timings = <0xe6382600 0x6866323c 0x2c030400>;
				qcom,mdss-dsi-t-clk-post = <0x21>;
				qcom,mdss-dsi-t-clk-pre = <0x2b>;
				qcom,mdss-dsi-tx-eot-append;
				qcom,mdss-dsi-lp11-init;
				qcom,mdss-dsi-bl-min-level = <0x01>;
				qcom,mdss-dsi-bl-max-level = <0xfff>;
				qcom,mdss-brightness-max-level = <0xfff>;
				qcom,mdss-dsi-bl-pmic-control-type = "bl_ctrl_wled";
				qcom,qpnp-lab-limit-maximum-current = <0xc8>;
				qcom,qpnp-ibb-limit-maximum-current = <0x320>;
				somc,mdss-dsi-disp-on-in-hs = <0x00>;
				somc,mdss-dsi-wait-time-before-on-cmd = <0x00>;
				somc,platform-regulator-settings = [03 03 03 00 20 00 01];
				somc,mdss-dsi-lane-config = [02 00 ef 00 20 00 00 01 ff 02 00 ef 00 40 00 00 01 ff 02 00 ef 40 20 00 00 01 ff 02 00 ef 40 00 00 00 01 ff 00 00 45 80 00 00 00 01 97];
				somc,disp-en-on-pre = <0x01>;
				somc,pw-on-rst-seq = <0x00 0x14 0x01 0x0a 0x00 0x01 0x01 0x14>;
				somc,disp-en-off-post = <0x0a>;
				somc,pw-off-rst-seq = <0x00 0x01>;
				somc,pw-down-period = <0x64>;
				somc,lab-output-voltage = <0x56f9a0>;
				somc,ibb-output-voltage = <0x56f9a0>;
				somc,lcd-id = <0x01>;
				somc,lcd-id-adc = <0x15aae0 0x185290>;
				somc,mdss-dsi-master;
				somc,change-fps-enable;
				somc,change-fps-command = [15 01 00 00 00 00 02 ff 24 15 01 00 00 00 00 02 92 8e 15 01 00 00 00 00 02 ff 10 39 01 00 00 00 00 03 44 03 00];
				somc,display-clock = <0xfe3620>;
				somc,driver-ic-vbp = <0x04>;
				somc,driver-ic-vfp = <0x0a>;
				somc,change-fps-rtn-adj;
				somc,change-fps-rtn-pos = <0x01 0x01>;
				somc,fps-threshold = <0xb928>;
				somc,te-c-mode-60fps = <0x03 0x00>;
				somc,te-c-mode-45fps = <0x04 0xff>;
				somc,te-c-mode-pos = <0x03 0x01>;
				somc,mdss-dsi-pcc-enable;
				somc,mdss-dsi-uv-command = <0x6010000 0x1da 0x6010000 0x1db>;
				somc,mdss-dsi-uv-param-type = <0x04>;
				somc,mdss-dsi-pcc-table-size = <0xe1>;
				somc,mdss-dsi-pcc-table = <0x00 0x01 0x38 0x3b 0x38 0x3b 0x8000 0x8000 0x8000 0x00 0x02 0x34 0x37 0x38 0x3b 0x8000 0x8000 0x8000 0x00 0x03 0x30 0x33 0x38 0x3b 0x8000 0x8000 0x8000 0x00 0x04 0x2c 0x2f 0x38 0x3b 0x8000 0x8000 0x8000 0x00 0x05 0x28 0x2b 0x38 0x3b 0x8000 0x8000 0x8000 0x00 0x06 0x24 0x27 0x38 0x3b 0x8000 0x8000 0x8000 0x00 0x07 0x20 0x23 0x38 0x3b 0x8000 0x8000 0x8000 0x00 0x08 0x1c 0x1f 0x38 0x3b 0x8000 0x8000 0x8000 0x00 0x09 0x18 0x1b 0x38 0x3b 0x8000 0x8000 0x8000 0x00 0x0a 0x14 0x17 0x38 0x3b 0x8000 0x8000 0x8000 0x00 0x0b 0x10 0x13 0x38 0x3b 0x8000 0x8000 0x8000 0x00 0x0c 0x0c 0x0f 0x38 0x3b 0x8000 0x8000 0x8000 0x00 0x0d 0x08 0x0b 0x38 0x3b 0x8000 0x8000 0x8000 0x00 0x0e 0x04 0x07 0x38 0x3b 0x8000 0x8000 0x8000 0x00 0x0f 0x00 0x03 0x38 0x3b 0x8000 0x8000 0x8000 0x00 0x10 0x38 0x3b 0x34 0x37 0x8000 0x8000 0x8000 0x00 0x11 0x34 0x37 0x34 0x37 0x8000 0x8000 0x8000 0x00 0x12 0x30 0x33 0x34 0x37 0x8000 0x8000 0x8000 0x00 0x13 0x2c 0x2f 0x34 0x37 0x8000 0x8000 0x8000 0x00 0x14 0x28 0x2b 0x34 0x37 0x8000 0x8000 0x8000 0x00 0x15 0x24 0x27 0x34 0x37 0x8000 0x8000 0x8000 0x00 0x16 0x20 0x23 0x34 0x37 0x8000 0x8000 0x8000 0x00 0x17 0x1c 0x1f 0x34 0x37 0x8000 0x8000 0x8000 0x00 0x18 0x18 0x1b 0x34 0x37 0x8000 0x8000 0x8000 0x00 0x19 0x14 0x17 0x34 0x37 0x8000 0x8000 0x8000 0x00 0x1a 0x10 0x13 0x34 0x37 0x8000 0x8000 0x8000 0x00 0x1b 0x0c 0x0f 0x34 0x37 0x8000 0x8000 0x8000 0x00 0x1c 0x08 0x0b 0x34 0x37 0x8000 0x8000 0x8000 0x00 0x1d 0x04 0x07 0x34 0x37 0x8000 0x8000 0x8000 0x00 0x1e 0x00 0x03 0x34 0x37 0x8000 0x8000 0x8000 0x00 0x1f 0x38 0x3b 0x30 0x33 0x8000 0x8000 0x8000 0x00 0x20 0x34 0x37 0x30 0x33 0x8000 0x8000 0x8000 0x00 0x21 0x30 0x33 0x30 0x33 0x6b80 0x7280 0x8000 0x00 0x22 0x2c 0x2f 0x30 0x33 0x6f80 0x7200 0x8000 0x00 0x23 0x28 0x2b 0x30 0x33 0x7380 0x7180 0x8000 0x00 0x24 0x24 0x27 0x30 0x33 0x7780 0x7100 0x8000 0x00 0x25 0x20 0x23 0x30 0x33 0x7300 0x7180 0x8000 0x00 0x26 0x1c 0x1f 0x30 0x33 0x7700 0x7100 0x8000 0x00 0x27 0x18 0x1b 0x30 0x33 0x7b80 0x7080 0x8000 0x00 0x28 0x14 0x17 0x30 0x33 0x7600 0x7180 0x8000 0x00 0x29 0x10 0x13 0x30 0x33 0x7b00 0x7100 0x8000 0x00 0x2a 0x0c 0x0f 0x30 0x33 0x7580 0x7180 0x8000 0x00 0x2b 0x08 0x0b 0x30 0x33 0x7a00 0x7100 0x8000 0x00 0x2c 0x04 0x07 0x30 0x33 0x8000 0x8000 0x8000 0x00 0x2d 0x00 0x03 0x30 0x33 0x8000 0x8000 0x8000 0x00 0x2e 0x38 0x3b 0x2c 0x2f 0x8000 0x8000 0x8000 0x00 0x2f 0x34 0x37 0x2c 0x2f 0x8000 0x8000 0x8000 0x00 0x30 0x30 0x33 0x2c 0x2f 0x6f80 0x7580 0x8000 0x00 0x31 0x2c 0x2f 0x2c 0x2f 0x7300 0x7500 0x8000 0x00 0x32 0x28 0x2b 0x2c 0x2f 0x7700 0x7480 0x8000 0x00 0x33 0x24 0x27 0x2c 0x2f 0x7b00 0x7400 0x8000 0x00 0x34 0x20 0x23 0x2c 0x2f 0x7600 0x7480 0x8000 0x00 0x35 0x1c 0x1f 0x2c 0x2f 0x7580 0x7480 0x8000 0x00 0x36 0x18 0x1b 0x2c 0x2f 0x7480 0x7480 0x8000 0x00 0x37 0x14 0x17 0x2c 0x2f 0x7900 0x7400 0x8000 0x00 0x38 0x10 0x13 0x2c 0x2f 0x7400 0x7500 0x8000 0x00 0x39 0x0c 0x0f 0x2c 0x2f 0x7800 0x7400 0x8000 0x00 0x3a 0x08 0x0b 0x2c 0x2f 0x7c80 0x7380 0x8000 0x00 0x3b 0x04 0x07 0x2c 0x2f 0x8000 0x8000 0x8000 0x00 0x3c 0x00 0x03 0x2c 0x2f 0x8000 0x8000 0x8000 0x00 0x3d 0x38 0x3b 0x28 0x2b 0x8000 0x8000 0x8000 0x00 0x3e 0x34 0x37 0x28 0x2b 0x8000 0x8000 0x8000 0x00 0x3f 0x30 0x33 0x28 0x2b 0x7300 0x7880 0x8000 0x00 0x40 0x2c 0x2f 0x28 0x2b 0x7600 0x7800 0x8000 0x00 0x41 0x28 0x2b 0x28 0x2b 0x7a80 0x7780 0x8000 0x00 0x42 0x24 0x27 0x28 0x2b 0x7500 0x7800 0x8000 0x00 0x43 0x20 0x23 0x28 0x2b 0x7900 0x7780 0x8000 0x00 0x44 0x1c 0x1f 0x28 0x2b 0x7880 0x7780 0x8000 0x00 0x45 0x18 0x1b 0x28 0x2b 0x7c00 0x7700 0x8000 0x00 0x46 0x14 0x17 0x28 0x2b 0x8000 0x7600 0x7f80 0x00 0x47 0x10 0x13 0x28 0x2b 0x8000 0x7680 0x8000 0x00 0x48 0x0c 0x0f 0x28 0x2b 0x7a80 0x7700 0x8000 0x00 0x49 0x08 0x0b 0x28 0x2b 0x7f00 0x7680 0x8000 0x00 0x4a 0x04 0x07 0x28 0x2b 0x8000 0x8000 0x8000 0x00 0x4b 0x00 0x03 0x28 0x2b 0x8000 0x8000 0x8000 0x00 0x4c 0x38 0x3b 0x24 0x27 0x8000 0x8000 0x8000 0x00 0x4d 0x34 0x37 0x24 0x27 0x8000 0x8000 0x8000 0x00 0x4e 0x30 0x33 0x24 0x27 0x7580 0x7b80 0x8000 0x00 0x4f 0x2c 0x2f 0x24 0x27 0x7980 0x7b00 0x8000 0x00 0x50 0x28 0x2b 0x24 0x27 0x7400 0x7b80 0x8000 0x00 0x51 0x24 0x27 0x24 0x27 0x7800 0x7b00 0x8000 0x00 0x52 0x20 0x23 0x24 0x27 0x7700 0x7b00 0x8000 0x00 0x53 0x1c 0x1f 0x24 0x27 0x7b80 0x7a80 0x8000 0x00 0x54 0x18 0x1b 0x24 0x27 0x7f00 0x7a00 0x8000 0x00 0x55 0x14 0x17 0x24 0x27 0x8000 0x7580 0x7c00 0x00 0x56 0x10 0x13 0x24 0x27 0x8000 0x7600 0x7d80 0x00 0x57 0x0c 0x0f 0x24 0x27 0x7c80 0x7a00 0x8000 0x00 0x58 0x08 0x0b 0x24 0x27 0x8000 0x7800 0x7f00 0x00 0x59 0x04 0x07 0x24 0x27 0x8000 0x8000 0x8000 0x00 0x5a 0x00 0x03 0x24 0x27 0x8000 0x8000 0x8000 0x00 0x5b 0x38 0x3b 0x20 0x23 0x8000 0x8000 0x8000 0x00 0x5c 0x34 0x37 0x20 0x23 0x8000 0x8000 0x8000 0x00 0x5d 0x30 0x33 0x20 0x23 0x7900 0x7e80 0x8000 0x00 0x5e 0x2c 0x2f 0x20 0x23 0x7380 0x7f80 0x8000 0x00 0x5f 0x28 0x2b 0x20 0x23 0x7700 0x7e80 0x8000 0x00 0x60 0x24 0x27 0x20 0x23 0x7600 0x7e80 0x8000 0x00 0x61 0x20 0x23 0x20 0x23 0x7a00 0x7e00 0x8000 0x00 0x62 0x1c 0x1f 0x20 0x23 0x7d80 0x7d80 0x8000 0x00 0x63 0x18 0x1b 0x20 0x23 0x8000 0x7b00 0x7e80 0x00 0x64 0x14 0x17 0x20 0x23 0x8000 0x7500 0x7980 0x00 0x65 0x10 0x13 0x20 0x23 0x8000 0x7600 0x7a00 0x00 0x66 0x0c 0x0f 0x20 0x23 0x7f00 0x7d00 0x8000 0x00 0x67 0x08 0x0b 0x20 0x23 0x8000 0x7780 0x7b80 0x00 0x68 0x04 0x07 0x20 0x23 0x8000 0x8000 0x8000 0x00 0x69 0x00 0x03 0x20 0x23 0x8000 0x8000 0x8000 0x00 0x6a 0x38 0x3b 0x1c 0x1f 0x8000 0x8000 0x8000 0x00 0x6b 0x34 0x37 0x1c 0x1f 0x8000 0x8000 0x8000 0x00 0x6c 0x30 0x33 0x1c 0x1f 0x7a80 0x8000 0x7f80 0x00 0x6d 0x2c 0x2f 0x1c 0x1f 0x7400 0x8000 0x7e80 0x00 0x6e 0x28 0x2b 0x1c 0x1f 0x7880 0x8000 0x7f00 0x00 0x6f 0x24 0x27 0x1c 0x1f 0x7700 0x8000 0x7f00 0x00 0x70 0x20 0x23 0x1c 0x1f 0x7c00 0x8000 0x7f80 0x00 0x71 0x18 0x1b 0x1c 0x1f 0x8000 0x7b00 0x7b80 0x00 0x72 0x14 0x17 0x1c 0x1f 0x8000 0x7500 0x7680 0x00 0x73 0x10 0x13 0x1c 0x1f 0x8000 0x7580 0x7700 0x00 0x74 0x0c 0x0f 0x1c 0x1f 0x8000 0x7e80 0x7f00 0x00 0x75 0x08 0x0b 0x1c 0x1f 0x8000 0x7700 0x7800 0x00 0x76 0x04 0x07 0x1c 0x1f 0x8000 0x8000 0x8000 0x00 0x77 0x00 0x03 0x1c 0x1f 0x8000 0x8000 0x8000 0x00 0x78 0x38 0x3b 0x18 0x1b 0x8000 0x8000 0x8000 0x00 0x79 0x34 0x37 0x18 0x1b 0x8000 0x8000 0x8000 0x00 0x7a 0x30 0x33 0x18 0x1b 0x7a00 0x8000 0x7c80 0x00 0x7b 0x2c 0x2f 0x18 0x1b 0x7e80 0x8000 0x7d80 0x00 0x7c 0x28 0x2b 0x18 0x1b 0x7780 0x8000 0x7c00 0x00 0x7d 0x24 0x27 0x18 0x1b 0x7680 0x8000 0x7c00 0x00 0x7e 0x20 0x23 0x18 0x1b 0x7b80 0x8000 0x7c80 0x00 0x7f 0x1c 0x1f 0x18 0x1b 0x8000 0x8000 0x7d80 0x00 0x80 0x18 0x1b 0x18 0x1b 0x8000 0x7b00 0x7980 0x00 0x81 0x14 0x17 0x18 0x1b 0x8000 0x7c00 0x7a00 0x00 0x82 0x10 0x13 0x18 0x1b 0x8000 0x7500 0x7480 0x00 0x83 0x0c 0x0f 0x18 0x1b 0x8000 0x7e80 0x7c00 0x00 0x84 0x08 0x0b 0x18 0x1b 0x8000 0x7680 0x7580 0x00 0x85 0x04 0x07 0x18 0x1b 0x8000 0x8000 0x8000 0x00 0x86 0x00 0x03 0x18 0x1b 0x8000 0x8000 0x8000 0x00 0x87 0x38 0x3b 0x14 0x17 0x8000 0x8000 0x8000 0x00 0x88 0x34 0x37 0x14 0x17 0x8000 0x8000 0x8000 0x00 0x89 0x30 0x33 0x14 0x17 0x7980 0x8000 0x7a00 0x00 0x8a 0x2c 0x2f 0x14 0x17 0x7e00 0x8000 0x7a80 0x00 0x8b 0x28 0x2b 0x14 0x17 0x7700 0x8000 0x7980 0x00 0x8c 0x24 0x27 0x14 0x17 0x7600 0x8000 0x7980 0x00 0x8d 0x20 0x23 0x14 0x17 0x7b00 0x8000 0x7a00 0x00 0x8e 0x1c 0x1f 0x14 0x17 0x8000 0x8000 0x7b00 0x00 0x8f 0x18 0x1b 0x14 0x17 0x8000 0x7b00 0x7680 0x00 0x90 0x14 0x17 0x14 0x17 0x8000 0x7c00 0x7780 0x00 0x91 0x10 0x13 0x14 0x17 0x7c80 0x8000 0x7a80 0x00 0x92 0x0c 0x0f 0x14 0x17 0x8000 0x7e00 0x7980 0x00 0x93 0x08 0x0b 0x14 0x17 0x8000 0x7580 0x7300 0x00 0x94 0x04 0x07 0x14 0x17 0x8000 0x8000 0x8000 0x00 0x95 0x00 0x03 0x14 0x17 0x8000 0x8000 0x8000 0x00 0x96 0x38 0x3b 0x10 0x13 0x8000 0x8000 0x8000 0x00 0x97 0x34 0x37 0x10 0x13 0x8000 0x8000 0x8000 0x00 0x98 0x30 0x33 0x10 0x13 0x7880 0x8000 0x7700 0x00 0x99 0x2c 0x2f 0x10 0x13 0x7d80 0x8000 0x7800 0x00 0x9a 0x28 0x2b 0x10 0x13 0x7680 0x8000 0x7680 0x00 0x9b 0x24 0x27 0x10 0x13 0x7580 0x8000 0x7680 0x00 0x9c 0x20 0x23 0x10 0x13 0x7b00 0x8000 0x7780 0x00 0x9d 0x1c 0x1f 0x10 0x13 0x7f80 0x8000 0x7800 0x00 0x9e 0x18 0x1b 0x10 0x13 0x8000 0x7b00 0x7480 0x00 0x9f 0x14 0x17 0x10 0x13 0x8000 0x7c00 0x7500 0x00 0xa0 0x10 0x13 0x10 0x13 0x7c80 0x8000 0x7800 0x00 0xa1 0x0c 0x0f 0x10 0x13 0x8000 0x7e00 0x7700 0x00 0xa2 0x08 0x0b 0x10 0x13 0x8000 0x7500 0x7080 0x00 0xa3 0x04 0x07 0x10 0x13 0x8000 0x8000 0x8000 0x00 0xa4 0x00 0x03 0x10 0x13 0x8000 0x8000 0x8000 0x00 0xa5 0x38 0x3b 0x0c 0x0f 0x8000 0x8000 0x8000 0x00 0xa6 0x34 0x37 0x0c 0x0f 0x8000 0x8000 0x8000 0x00 0xa7 0x30 0x33 0x0c 0x0f 0x7800 0x8000 0x7500 0x00 0xa8 0x2c 0x2f 0x0c 0x0f 0x7d00 0x8000 0x7580 0x00 0xa9 0x28 0x2b 0x0c 0x0f 0x7600 0x8000 0x7480 0x00 0xaa 0x24 0x27 0x0c 0x0f 0x7500 0x8000 0x7480 0x00 0xab 0x20 0x23 0x0c 0x0f 0x7a80 0x8000 0x7580 0x00 0xac 0x1c 0x1f 0x0c 0x0f 0x7f80 0x8000 0x7600 0x00 0xad 0x18 0x1b 0x0c 0x0f 0x7e80 0x8000 0x7600 0x00 0xae 0x14 0x17 0x0c 0x0f 0x7780 0x8000 0x7500 0x00 0xaf 0x10 0x13 0x0c 0x0f 0x7c80 0x8000 0x7600 0x00 0xb0 0x0c 0x0f 0x0c 0x0f 0x8000 0x7e00 0x7480 0x00 0xb1 0x08 0x0b 0x0c 0x0f 0x8000 0x7480 0x6e80 0x00 0xb2 0x04 0x07 0x0c 0x0f 0x8000 0x8000 0x8000 0x00 0xb3 0x00 0x03 0x0c 0x0f 0x8000 0x8000 0x8000 0x00 0xb4 0x38 0x3b 0x08 0x0b 0x8000 0x8000 0x8000 0x00 0xb5 0x34 0x37 0x08 0x0b 0x8000 0x8000 0x8000 0x00 0xb6 0x30 0x33 0x08 0x0b 0x7700 0x8000 0x7280 0x00 0xb7 0x2c 0x2f 0x08 0x0b 0x7c80 0x8000 0x7380 0x00 0xb8 0x28 0x2b 0x08 0x0b 0x8000 0x7e80 0x7380 0x00 0xb9 0x24 0x27 0x08 0x0b 0x7b00 0x8000 0x7380 0x00 0xba 0x20 0x23 0x08 0x0b 0x8000 0x8000 0x7480 0x00 0xbb 0x1c 0x1f 0x08 0x0b 0x7900 0x8000 0x7380 0x00 0xbc 0x18 0x1b 0x08 0x0b 0x7e00 0x8000 0x7400 0x00 0xbd 0x14 0x17 0x08 0x0b 0x7700 0x8000 0x7300 0x00 0xbe 0x10 0x13 0x08 0x0b 0x7c80 0x8000 0x7400 0x00 0xbf 0x0c 0x0f 0x08 0x0b 0x8000 0x7d80 0x7300 0x00 0xc0 0x08 0x0b 0x08 0x0b 0x8000 0x7400 0x6c80 0x00 0xc1 0x04 0x07 0x08 0x0b 0x8000 0x8000 0x8000 0x00 0xc2 0x00 0x03 0x08 0x0b 0x8000 0x8000 0x8000 0x00 0xc3 0x38 0x3b 0x04 0x07 0x8000 0x8000 0x8000 0x00 0xc4 0x34 0x37 0x04 0x07 0x8000 0x8000 0x8000 0x00 0xc5 0x30 0x33 0x04 0x07 0x8000 0x8000 0x8000 0x00 0xc6 0x2c 0x2f 0x04 0x07 0x8000 0x8000 0x8000 0x00 0xc7 0x28 0x2b 0x04 0x07 0x8000 0x8000 0x8000 0x00 0xc8 0x24 0x27 0x04 0x07 0x8000 0x8000 0x8000 0x00 0xc9 0x20 0x23 0x04 0x07 0x8000 0x8000 0x8000 0x00 0xca 0x1c 0x1f 0x04 0x07 0x8000 0x8000 0x8000 0x00 0xcb 0x18 0x1b 0x04 0x07 0x8000 0x8000 0x8000 0x00 0xcc 0x14 0x17 0x04 0x07 0x8000 0x8000 0x8000 0x00 0xcd 0x10 0x13 0x04 0x07 0x8000 0x8000 0x8000 0x00 0xce 0x0c 0x0f 0x04 0x07 0x8000 0x8000 0x8000 0x00 0xcf 0x08 0x0b 0x04 0x07 0x8000 0x8000 0x8000 0x00 0xd0 0x04 0x07 0x04 0x07 0x8000 0x8000 0x8000 0x00 0xd1 0x00 0x03 0x04 0x07 0x8000 0x8000 0x8000 0x00 0xd2 0x38 0x3b 0x00 0x03 0x8000 0x8000 0x8000 0x00 0xd3 0x34 0x37 0x00 0x03 0x8000 0x8000 0x8000 0x00 0xd4 0x30 0x33 0x00 0x03 0x8000 0x8000 0x8000 0x00 0xd5 0x2c 0x2f 0x00 0x03 0x8000 0x8000 0x8000 0x00 0xd6 0x28 0x2b 0x00 0x03 0x8000 0x8000 0x8000 0x00 0xd7 0x24 0x27 0x00 0x03 0x8000 0x8000 0x8000 0x00 0xd8 0x20 0x23 0x00 0x03 0x8000 0x8000 0x8000 0x00 0xd9 0x1c 0x1f 0x00 0x03 0x8000 0x8000 0x8000 0x00 0xda 0x18 0x1b 0x00 0x03 0x8000 0x8000 0x8000 0x00 0xdb 0x14 0x17 0x00 0x03 0x8000 0x8000 0x8000 0x00 0xdc 0x10 0x13 0x00 0x03 0x8000 0x8000 0x8000 0x00 0xdd 0x0c 0x0f 0x00 0x03 0x8000 0x8000 0x8000 0x00 0xde 0x08 0x0b 0x00 0x03 0x8000 0x8000 0x8000 0x00 0xdf 0x04 0x07 0x00 0x03 0x8000 0x8000 0x8000 0x00 0xe0 0x00 0x03 0x00 0x03 0x8000 0x8000 0x8000 0xff 0x00 0x00 0x3b 0x00 0x3b 0x8000 0x8000 0x8000>;
			};

			somc,sharp_novatek_fullhd_cmd_panel {
				qcom,mdss-dsi-panel-name = [33 00];
				qcom,mdss-dsi-panel-controller = <0x2b>;
				qcom,mdss-dsi-panel-destination = "display_1";
				qcom,mdss-dsi-panel-type = "dsi_cmd_mode";
				qcom,mdss-dsi-panel-width = <0x438>;
				qcom,mdss-dsi-panel-height = <0x780>;
				qcom,mdss-dsi-bpp = <0x18>;
				qcom,mdss-dsi-h-back-porch = <0x08>;
				qcom,mdss-dsi-h-pulse-width = <0x08>;
				qcom,mdss-dsi-h-front-porch = <0x38>;
				qcom,mdss-dsi-v-back-porch = <0x08>;
				qcom,mdss-dsi-v-pulse-width = <0x02>;
				qcom,mdss-dsi-v-front-porch = <0xe9>;
				qcom,mdss-pan-physical-width-dimension = <0x40>;
				qcom,mdss-pan-physical-height-dimension = <0x72>;
				qcom,mdss-dsi-panel-framerate = <0x3c>;
				qcom,mdss-dsi-virtual-channel-id = <0x00>;
				qcom,mdss-dsi-stream = <0x00>;
				qcom,mdss-dsi-h-sync-skew = <0x00>;
				qcom,mdss-dsi-h-left-border = <0x00>;
				qcom,mdss-dsi-h-right-border = <0x00>;
				qcom,mdss-dsi-v-top-border = <0x00>;
				qcom,mdss-dsi-v-bottom-border = <0x00>;
				qcom,mdss-dsi-underflow-color = <0x00>;
				qcom,mdss-dsi-border-color = <0x00>;
				qcom,mdss-dsi-h-sync-pulse = <0x01>;
				qcom,mdss-dsi-traffic-mode = "non_burst_sync_event";
				qcom,mdss-dsi-bllp-eof-power-mode;
				qcom,mdss-dsi-bllp-power-mode;
				qcom,mdss-dsi-dma-trigger = "trigger_sw";
				qcom,mdss-dsi-mdp-trigger = "none";
				somc,mdss-dsi-init-command = [15 01 00 00 00 00 02 bb 10 15 01 00 00 00 00 02 ff 20 15 01 00 00 00 00 02 fb 01 15 01 00 00 00 00 02 75 00 15 01 00 00 00 00 02 76 39 15 01 00 00 00 00 02 77 00 15 01 00 00 00 00 02 78 64 15 01 00 00 00 00 02 79 00 15 01 00 00 00 00 02 7a 9b 15 01 00 00 00 00 02 7b 00 15 01 00 00 00 00 02 7c bd 15 01 00 00 00 00 02 7d 00 15 01 00 00 00 00 02 7e da 15 01 00 00 00 00 02 7f 00 15 01 00 00 00 00 02 80 f1 15 01 00 00 00 00 02 81 01 15 01 00 00 00 00 02 82 03 15 01 00 00 00 00 02 83 01 15 01 00 00 00 00 02 84 10 15 01 00 00 00 00 02 85 01 15 01 00 00 00 00 02 86 1f 15 01 00 00 00 00 02 87 01 15 01 00 00 00 00 02 88 4e 15 01 00 00 00 00 02 89 01 15 01 00 00 00 00 02 8a 72 15 01 00 00 00 00 02 8b 01 15 01 00 00 00 00 02 8c b0 15 01 00 00 00 00 02 8d 01 15 01 00 00 00 00 02 8e e0 15 01 00 00 00 00 02 8f 02 15 01 00 00 00 00 02 90 27 15 01 00 00 00 00 02 91 02 15 01 00 00 00 00 02 92 5a 15 01 00 00 00 00 02 93 02 15 01 00 00 00 00 02 94 5c 15 01 00 00 00 00 02 95 02 15 01 00 00 00 00 02 96 8c 15 01 00 00 00 00 02 97 02 15 01 00 00 00 00 02 98 b9 15 01 00 00 00 00 02 99 02 15 01 00 00 00 00 02 9a d9 15 01 00 00 00 00 02 9b 03 15 01 00 00 00 00 02 9c 0a 15 01 00 00 00 00 02 9d 03 15 01 00 00 00 00 02 9e 23 15 01 00 00 00 00 02 9f 03 15 01 00 00 00 00 02 a0 7e 15 01 00 00 00 00 02 a2 03 15 01 00 00 00 00 02 a3 a6 15 01 00 00 00 00 02 a4 03 15 01 00 00 00 00 02 a5 ca 15 01 00 00 00 00 02 a6 03 15 01 00 00 00 00 02 a7 d7 15 01 00 00 00 00 02 a9 03 15 01 00 00 00 00 02 aa da 15 01 00 00 00 00 02 ab 03 15 01 00 00 00 00 02 ac dc 15 01 00 00 00 00 02 ad 03 15 01 00 00 00 00 02 ae dc 15 01 00 00 00 00 02 af 03 15 01 00 00 00 00 02 b0 dc 15 01 00 00 00 00 02 b1 03 15 01 00 00 00 00 02 b2 dc 15 01 00 00 00 00 02 b3 00 15 01 00 00 00 00 02 b4 74 15 01 00 00 00 00 02 b5 00 15 01 00 00 00 00 02 b6 9e 15 01 00 00 00 00 02 b7 00 15 01 00 00 00 00 02 b8 d2 15 01 00 00 00 00 02 b9 00 15 01 00 00 00 00 02 ba f1 15 01 00 00 00 00 02 bb 01 15 01 00 00 00 00 02 bc 0b 15 01 00 00 00 00 02 bd 01 15 01 00 00 00 00 02 be 20 15 01 00 00 00 00 02 bf 01 15 01 00 00 00 00 02 c0 2f 15 01 00 00 00 00 02 c1 01 15 01 00 00 00 00 02 c2 3b 15 01 00 00 00 00 02 c3 01 15 01 00 00 00 00 02 c4 48 15 01 00 00 00 00 02 c5 01 15 01 00 00 00 00 02 c6 6f 15 01 00 00 00 00 02 c7 01 15 01 00 00 00 00 02 c8 8c 15 01 00 00 00 00 02 c9 01 15 01 00 00 00 00 02 ca b9 15 01 00 00 00 00 02 cb 01 15 01 00 00 00 00 02 cc db 15 01 00 00 00 00 02 cd 02 15 01 00 00 00 00 02 ce 15 15 01 00 00 00 00 02 cf 02 15 01 00 00 00 00 02 d0 48 15 01 00 00 00 00 02 d1 02 15 01 00 00 00 00 02 d2 49 15 01 00 00 00 00 02 d3 02 15 01 00 00 00 00 02 d4 79 15 01 00 00 00 00 02 d5 02 15 01 00 00 00 00 02 d6 bf 15 01 00 00 00 00 02 d7 02 15 01 00 00 00 00 02 d8 ee 15 01 00 00 00 00 02 d9 03 15 01 00 00 00 00 02 da 21 15 01 00 00 00 00 02 db 03 15 01 00 00 00 00 02 dc 39 15 01 00 00 00 00 02 dd 03 15 01 00 00 00 00 02 de 94 15 01 00 00 00 00 02 df 03 15 01 00 00 00 00 02 e0 bb 15 01 00 00 00 00 02 e1 03 15 01 00 00 00 00 02 e2 e2 15 01 00 00 00 00 02 e3 03 15 01 00 00 00 00 02 e4 ee 15 01 00 00 00 00 02 e5 03 15 01 00 00 00 00 02 e6 f2 15 01 00 00 00 00 02 e7 03 15 01 00 00 00 00 02 e8 f3 15 01 00 00 00 00 02 e9 03 15 01 00 00 00 00 02 ea f3 15 01 00 00 00 00 02 eb 03 15 01 00 00 00 00 02 ec f3 15 01 00 00 00 00 02 ed 03 15 01 00 00 00 00 02 ee f3 15 01 00 00 00 00 02 ef 00 15 01 00 00 00 00 02 f0 7c 15 01 00 00 00 00 02 f1 00 15 01 00 00 00 00 02 f2 8b 15 01 00 00 00 00 02 f3 00 15 01 00 00 00 00 02 f4 ab 15 01 00 00 00 00 02 f5 00 15 01 00 00 00 00 02 f6 c7 15 01 00 00 00 00 02 f7 00 15 01 00 00 00 00 02 f8 de 15 01 00 00 00 00 02 f9 00 15 01 00 00 00 00 02 fa f0 15 01 00 00 00 00 02 ff 21 15 01 00 00 00 00 02 fb 01 15 01 00 00 00 00 02 00 01 15 01 00 00 00 00 02 01 01 15 01 00 00 00 00 02 02 01 15 01 00 00 00 00 02 03 0e 15 01 00 00 00 00 02 04 01 15 01 00 00 00 00 02 05 1c 15 01 00 00 00 00 02 06 01 15 01 00 00 00 00 02 07 4c 15 01 00 00 00 00 02 08 01 15 01 00 00 00 00 02 09 70 15 01 00 00 00 00 02 0a 01 15 01 00 00 00 00 02 0b ad 15 01 00 00 00 00 02 0c 01 15 01 00 00 00 00 02 0d de 15 01 00 00 00 00 02 0e 02 15 01 00 00 00 00 02 0f 26 15 01 00 00 00 00 02 10 02 15 01 00 00 00 00 02 11 5a 15 01 00 00 00 00 02 12 02 15 01 00 00 00 00 02 13 5b 15 01 00 00 00 00 02 14 02 15 01 00 00 00 00 02 15 8b 15 01 00 00 00 00 02 16 02 15 01 00 00 00 00 02 17 b9 15 01 00 00 00 00 02 18 02 15 01 00 00 00 00 02 19 d6 15 01 00 00 00 00 02 1a 03 15 01 00 00 00 00 02 1b 02 15 01 00 00 00 00 02 1c 03 15 01 00 00 00 00 02 1d 1f 15 01 00 00 00 00 02 1e 03 15 01 00 00 00 00 02 1f 81 15 01 00 00 00 00 02 20 03 15 01 00 00 00 00 02 21 a9 15 01 00 00 00 00 02 22 03 15 01 00 00 00 00 02 23 cd 15 01 00 00 00 00 02 24 03 15 01 00 00 00 00 02 25 d8 15 01 00 00 00 00 02 26 03 15 01 00 00 00 00 02 27 da 15 01 00 00 00 00 02 28 03 15 01 00 00 00 00 02 29 dc 15 01 00 00 00 00 02 2a 03 15 01 00 00 00 00 02 2b dc 15 01 00 00 00 00 02 2d 03 15 01 00 00 00 00 02 2f dc 15 01 00 00 00 00 02 30 03 15 01 00 00 00 00 02 31 dc 15 01 00 00 00 00 02 32 00 15 01 00 00 00 00 02 33 bc 15 01 00 00 00 00 02 34 00 15 01 00 00 00 00 02 35 cc 15 01 00 00 00 00 02 36 00 15 01 00 00 00 00 02 37 ea 15 01 00 00 00 00 02 38 01 15 01 00 00 00 00 02 39 06 15 01 00 00 00 00 02 3a 01 15 01 00 00 00 00 02 3b 1b 15 01 00 00 00 00 02 3d 01 15 01 00 00 00 00 02 3f 2a 15 01 00 00 00 00 02 40 01 15 01 00 00 00 00 02 41 39 15 01 00 00 00 00 02 42 01 15 01 00 00 00 00 02 43 45 15 01 00 00 00 00 02 44 01 15 01 00 00 00 00 02 45 50 15 01 00 00 00 00 02 46 01 15 01 00 00 00 00 02 47 76 15 01 00 00 00 00 02 48 01 15 01 00 00 00 00 02 49 90 15 01 00 00 00 00 02 4a 01 15 01 00 00 00 00 02 4b bb 15 01 00 00 00 00 02 4c 01 15 01 00 00 00 00 02 4d dd 15 01 00 00 00 00 02 4e 02 15 01 00 00 00 00 02 4f 15 15 01 00 00 00 00 02 50 02 15 01 00 00 00 00 02 51 49 15 01 00 00 00 00 02 52 02 15 01 00 00 00 00 02 53 4a 15 01 00 00 00 00 02 54 02 15 01 00 00 00 00 02 55 79 15 01 00 00 00 00 02 56 02 15 01 00 00 00 00 02 58 bf 15 01 00 00 00 00 02 59 02 15 01 00 00 00 00 02 5a eb 15 01 00 00 00 00 02 5b 03 15 01 00 00 00 00 02 5c 19 15 01 00 00 00 00 02 5d 03 15 01 00 00 00 00 02 5e 36 15 01 00 00 00 00 02 5f 03 15 01 00 00 00 00 02 60 99 15 01 00 00 00 00 02 61 03 15 01 00 00 00 00 02 62 c2 15 01 00 00 00 00 02 63 03 15 01 00 00 00 00 02 64 e6 15 01 00 00 00 00 02 65 03 15 01 00 00 00 00 02 66 f1 15 01 00 00 00 00 02 67 03 15 01 00 00 00 00 02 68 f3 15 01 00 00 00 00 02 69 03 15 01 00 00 00 00 02 6a f4 15 01 00 00 00 00 02 6b 03 15 01 00 00 00 00 02 6c f4 15 01 00 00 00 00 02 6d 03 15 01 00 00 00 00 02 6e f4 15 01 00 00 00 00 02 6f 03 15 01 00 00 00 00 02 70 f4 15 01 00 00 00 00 02 71 00 15 01 00 00 00 00 02 72 ef 15 01 00 00 00 00 02 73 00 15 01 00 00 00 00 02 74 f4 15 01 00 00 00 00 02 75 01 15 01 00 00 00 00 02 76 03 15 01 00 00 00 00 02 77 01 15 01 00 00 00 00 02 78 11 15 01 00 00 00 00 02 79 01 15 01 00 00 00 00 02 7a 1c 15 01 00 00 00 00 02 7b 01 15 01 00 00 00 00 02 7c 27 15 01 00 00 00 00 02 7d 01 15 01 00 00 00 00 02 7e 31 15 01 00 00 00 00 02 7f 01 15 01 00 00 00 00 02 80 3c 15 01 00 00 00 00 02 81 01 15 01 00 00 00 00 02 82 46 15 01 00 00 00 00 02 83 01 15 01 00 00 00 00 02 84 6a 15 01 00 00 00 00 02 85 01 15 01 00 00 00 00 02 86 89 15 01 00 00 00 00 02 87 01 15 01 00 00 00 00 02 88 be 15 01 00 00 00 00 02 89 01 15 01 00 00 00 00 02 8a ea 15 01 00 00 00 00 02 8b 02 15 01 00 00 00 00 02 8c 2f 15 01 00 00 00 00 02 8d 02 15 01 00 00 00 00 02 8e 60 15 01 00 00 00 00 02 8f 02 15 01 00 00 00 00 02 90 62 15 01 00 00 00 00 02 91 02 15 01 00 00 00 00 02 92 90 15 01 00 00 00 00 02 93 02 15 01 00 00 00 00 02 94 bc 15 01 00 00 00 00 02 95 02 15 01 00 00 00 00 02 96 dd 15 01 00 00 00 00 02 97 03 15 01 00 00 00 00 02 98 0e 15 01 00 00 00 00 02 99 03 15 01 00 00 00 00 02 9a 27 15 01 00 00 00 00 02 9b 03 15 01 00 00 00 00 02 9c 7a 15 01 00 00 00 00 02 9d 03 15 01 00 00 00 00 02 9e a1 15 01 00 00 00 00 02 9f 03 15 01 00 00 00 00 02 a0 c8 15 01 00 00 00 00 02 a2 03 15 01 00 00 00 00 02 a3 d7 15 01 00 00 00 00 02 a4 03 15 01 00 00 00 00 02 a5 db 15 01 00 00 00 00 02 a6 03 15 01 00 00 00 00 02 a7 dc 15 01 00 00 00 00 02 a9 03 15 01 00 00 00 00 02 aa dd 15 01 00 00 00 00 02 ab 03 15 01 00 00 00 00 02 ac dd 15 01 00 00 00 00 02 ad 03 15 01 00 00 00 00 02 ae dd 15 01 00 00 00 00 02 af 01 15 01 00 00 00 00 02 b0 32 15 01 00 00 00 00 02 b1 01 15 01 00 00 00 00 02 b2 39 15 01 00 00 00 00 02 b3 01 15 01 00 00 00 00 02 b4 45 15 01 00 00 00 00 02 b5 01 15 01 00 00 00 00 02 b6 4f 15 01 00 00 00 00 02 b7 01 15 01 00 00 00 00 02 b8 59 15 01 00 00 00 00 02 b9 01 15 01 00 00 00 00 02 ba 62 15 01 00 00 00 00 02 bb 01 15 01 00 00 00 00 02 bc 6a 15 01 00 00 00 00 02 bd 01 15 01 00 00 00 00 02 be 71 15 01 00 00 00 00 02 bf 01 15 01 00 00 00 00 02 c0 78 15 01 00 00 00 00 02 c1 01 15 01 00 00 00 00 02 c2 92 15 01 00 00 00 00 02 c3 01 15 01 00 00 00 00 02 c4 a8 15 01 00 00 00 00 02 c5 01 15 01 00 00 00 00 02 c6 cd 15 01 00 00 00 00 02 c7 01 15 01 00 00 00 00 02 c8 ea 15 01 00 00 00 00 02 c9 02 15 01 00 00 00 00 02 ca 1d 15 01 00 00 00 00 02 cb 02 15 01 00 00 00 00 02 cc 4e 15 01 00 00 00 00 02 cd 02 15 01 00 00 00 00 02 ce 4f 15 01 00 00 00 00 02 cf 02 15 01 00 00 00 00 02 d0 7d 15 01 00 00 00 00 02 d1 02 15 01 00 00 00 00 02 d2 c2 15 01 00 00 00 00 02 d3 02 15 01 00 00 00 00 02 d4 f1 15 01 00 00 00 00 02 d5 03 15 01 00 00 00 00 02 d6 24 15 01 00 00 00 00 02 d7 03 15 01 00 00 00 00 02 d8 3e 15 01 00 00 00 00 02 d9 03 15 01 00 00 00 00 02 da 91 15 01 00 00 00 00 02 db 03 15 01 00 00 00 00 02 dc b8 15 01 00 00 00 00 02 dd 03 15 01 00 00 00 00 02 de df 15 01 00 00 00 00 02 df 03 15 01 00 00 00 00 02 e0 ee 15 01 00 00 00 00 02 e1 03 15 01 00 00 00 00 02 e2 f1 15 01 00 00 00 00 02 e3 03 15 01 00 00 00 00 02 e4 f3 15 01 00 00 00 00 02 e5 03 15 01 00 00 00 00 02 e6 f3 15 01 00 00 00 00 02 e7 03 15 01 00 00 00 00 02 e8 f3 15 01 00 00 00 00 02 e9 03 15 01 00 00 00 00 02 ea f3 15 01 00 00 00 00 02 ff 24 15 01 00 00 00 00 02 fb 01 15 01 00 00 00 00 02 86 39 15 01 00 00 00 00 02 87 1b 15 01 00 00 00 00 02 88 39 15 01 00 00 00 00 02 89 1b 15 01 00 00 00 00 02 8c 01 15 01 00 00 00 00 02 ff 10 15 01 00 00 00 00 02 35 00 39 01 00 00 00 00 03 44 03 00 15 01 00 00 00 00 02 ff e0 15 01 00 00 00 00 02 fb 01 15 01 00 00 00 00 02 b5 86 15 01 00 00 00 00 02 b6 77 15 01 00 00 00 00 02 b8 ad 15 01 00 00 00 00 02 ff 20 15 01 00 00 00 00 02 fb 01 15 01 00 00 00 00 02 10 04 15 01 00 00 00 00 02 ff 10 05 01 00 00 1e 00 01 11];
				qcom,mdss-dsi-on-command = <0x5010000 0x129>;
				qcom,mdss-dsi-off-command = [15 01 00 00 00 00 02 ff 10 05 01 00 00 14 00 01 28 05 01 00 00 50 00 01 10];
				qcom,mdss-dsi-on-command-state = "dsi_lp_mode";
				qcom,mdss-dsi-off-command-state = "dsi_hs_mode";
				qcom,mdss-dsi-te-pin-select = <0x01>;
				qcom,mdss-dsi-wr-mem-start = <0x2c>;
				qcom,mdss-dsi-wr-mem-continue = <0x3c>;
				qcom,mdss-dsi-te-dcs-command = <0x01>;
				qcom,mdss-dsi-te-check-enable;
				qcom,mdss-dsi-te-using-te-pin;
				qcom,mdss-dsi-lane-0-state;
				qcom,mdss-dsi-lane-1-state;
				qcom,mdss-dsi-lane-2-state;
				qcom,mdss-dsi-lane-3-state;
				qcom,mdss-dsi-panel-timings = <0xe6382600 0x6866323c 0x2c030400>;
				qcom,mdss-dsi-t-clk-post = <0x21>;
				qcom,mdss-dsi-t-clk-pre = <0x2b>;
				qcom,mdss-dsi-tx-eot-append;
				qcom,mdss-dsi-lp11-init;
				qcom,mdss-dsi-bl-min-level = <0x01>;
				qcom,mdss-dsi-bl-max-level = <0xfff>;
				qcom,mdss-brightness-max-level = <0xfff>;
				qcom,mdss-dsi-bl-pmic-control-type = "bl_ctrl_wled";
				qcom,qpnp-lab-limit-maximum-current = <0xc8>;
				qcom,qpnp-ibb-limit-maximum-current = <0x320>;
				somc,mdss-dsi-disp-on-in-hs = <0x00>;
				somc,mdss-dsi-wait-time-before-on-cmd = <0x00>;
				somc,platform-regulator-settings = [03 03 03 00 20 00 01];
				somc,mdss-dsi-lane-config = [02 00 ef 00 20 00 00 01 ff 02 00 ef 00 40 00 00 01 ff 02 00 ef 40 20 00 00 01 ff 02 00 ef 40 00 00 00 01 ff 00 00 45 80 00 00 00 01 97];
				somc,disp-en-on-pre = <0x01>;
				somc,pw-on-rst-seq = <0x00 0x14 0x01 0x01 0x00 0x01 0x01 0x0a>;
				somc,disp-en-off-post = <0x0a>;
				somc,pw-off-rst-seq = <0x00 0x01>;
				somc,pw-down-period = <0x64>;
				somc,lab-output-voltage = <0x557300>;
				somc,ibb-output-voltage = <0x557300>;
				somc,lcd-id = <0x01>;
				somc,lcd-id-adc = <0x12dc20 0x154938>;
				somc,mdss-dsi-master;
				somc,change-fps-enable;
				somc,change-fps-command = [15 01 00 00 00 00 02 ff 24 15 01 00 00 00 00 02 92 8f 15 01 00 00 00 00 02 ff 10 39 01 00 00 00 00 03 44 03 00];
				somc,display-clock = <0xfe3620>;
				somc,driver-ic-vbp = <0x06>;
				somc,driver-ic-vfp = <0x02>;
				somc,change-fps-rtn-adj;
				somc,change-fps-rtn-pos = <0x01 0x01>;
				somc,fps-threshold = <0xb928>;
				somc,te-c-mode-60fps = <0x03 0x00>;
				somc,te-c-mode-45fps = <0x04 0xff>;
				somc,te-c-mode-pos = <0x03 0x01>;
				somc,mdss-dsi-lock-command = [15 01 00 00 00 00 02 ff 10 15 01 00 00 00 00 02 fb 01 15 01 00 00 00 00 02 f0 55 15 01 00 00 00 00 02 f1 aa 15 01 00 00 01 00 02 f2 66];
				somc,mdss-dsi-unlock-command = [15 01 00 00 00 00 02 ff 10 15 01 00 00 00 00 02 fb 01 15 01 00 00 00 00 02 f0 aa 15 01 00 00 00 00 02 f1 55 15 01 00 00 01 00 02 f2 99];
				somc,mdss-dsi-pcc-enable;
				somc,mdss-dsi-uv-command = <0x6010000 0x1da 0x6010000 0x1db>;
				somc,mdss-dsi-uv-param-type = <0x04>;
				somc,mdss-dsi-pcc-table-size = <0xe1>;
				somc,mdss-dsi-pcc-table = <0x00 0x01 0x38 0x3b 0x38 0x3b 0x3d00 0x6b80 0x8000 0x00 0x02 0x34 0x37 0x38 0x3b 0x4200 0x6b00 0x8000 0x00 0x03 0x30 0x33 0x38 0x3b 0x4700 0x6a80 0x8000 0x00 0x04 0x2c 0x2f 0x38 0x3b 0x4c80 0x6a00 0x8000 0x00 0x05 0x28 0x2b 0x38 0x3b 0x5280 0x6a00 0x8000 0x00 0x06 0x24 0x27 0x38 0x3b 0x5700 0x6980 0x8000 0x00 0x07 0x20 0x23 0x38 0x3b 0x5d00 0x6900 0x8000 0x00 0x08 0x1c 0x1f 0x38 0x3b 0x6280 0x6900 0x8000 0x00 0x09 0x18 0x1b 0x38 0x3b 0x6880 0x6880 0x8000 0x00 0x0a 0x14 0x17 0x38 0x3b 0x6e00 0x6800 0x8000 0x00 0x0b 0x10 0x13 0x38 0x3b 0x7480 0x6880 0x8000 0x00 0x0c 0x0c 0x0f 0x38 0x3b 0x7b00 0x6800 0x8000 0x00 0x0d 0x08 0x0b 0x38 0x3b 0x8000 0x6580 0x7e00 0x00 0x0e 0x04 0x07 0x38 0x3b 0x8000 0x5e00 0x7600 0x00 0x0f 0x00 0x03 0x38 0x3b 0x8000 0x5580 0x6c80 0x00 0x10 0x38 0x3b 0x34 0x37 0x4300 0x6f00 0x8000 0x00 0x11 0x34 0x37 0x34 0x37 0x4880 0x6e80 0x8000 0x00 0x12 0x30 0x33 0x34 0x37 0x4d80 0x6e00 0x8000 0x00 0x13 0x2c 0x2f 0x34 0x37 0x5280 0x6d80 0x8000 0x00 0x14 0x28 0x2b 0x34 0x37 0x5700 0x6d80 0x8000 0x00 0x15 0x24 0x27 0x34 0x37 0x5c80 0x6d00 0x8000 0x00 0x16 0x20 0x23 0x34 0x37 0x6200 0x6c80 0x8000 0x00 0x17 0x1c 0x1f 0x34 0x37 0x6780 0x6c00 0x8000 0x00 0x18 0x18 0x1b 0x34 0x37 0x6d00 0x6b80 0x8000 0x00 0x19 0x14 0x17 0x34 0x37 0x7300 0x6b80 0x8000 0x00 0x1a 0x10 0x13 0x34 0x37 0x7900 0x6b00 0x8000 0x00 0x1b 0x0c 0x0f 0x34 0x37 0x8000 0x6a80 0x8000 0x00 0x1c 0x08 0x0b 0x34 0x37 0x8000 0x6400 0x7900 0x00 0x1d 0x04 0x07 0x34 0x37 0x8000 0x5c00 0x7180 0x00 0x1e 0x00 0x03 0x34 0x37 0x8000 0x5300 0x6800 0x00 0x1f 0x38 0x3b 0x30 0x33 0x4900 0x7300 0x8000 0x00 0x20 0x34 0x37 0x30 0x33 0x4e00 0x7280 0x8000 0x00 0x21 0x30 0x33 0x30 0x33 0x5280 0x7200 0x8000 0x00 0x22 0x2c 0x2f 0x30 0x33 0x5700 0x7100 0x8000 0x00 0x23 0x28 0x2b 0x30 0x33 0x5c80 0x7080 0x8000 0x00 0x24 0x24 0x27 0x30 0x33 0x6180 0x7000 0x8000 0x00 0x25 0x20 0x23 0x30 0x33 0x6680 0x6f80 0x8000 0x00 0x26 0x1c 0x1f 0x30 0x33 0x6b80 0x6f80 0x8000 0x00 0x27 0x18 0x1b 0x30 0x33 0x7180 0x6f00 0x8000 0x00 0x28 0x14 0x17 0x30 0x33 0x7700 0x6e80 0x8000 0x00 0x29 0x10 0x13 0x30 0x33 0x7e00 0x6e00 0x8000 0x00 0x2a 0x0c 0x0f 0x30 0x33 0x8000 0x6980 0x7c00 0x00 0x2b 0x08 0x0b 0x30 0x33 0x8000 0x6280 0x7500 0x00 0x2c 0x04 0x07 0x30 0x33 0x8000 0x5a80 0x6d00 0x00 0x2d 0x00 0x03 0x30 0x33 0x8000 0x5080 0x6400 0x00 0x2e 0x38 0x3b 0x2c 0x2f 0x4e80 0x7680 0x8000 0x00 0x2f 0x34 0x37 0x2c 0x2f 0x5300 0x7600 0x8000 0x00 0x30 0x30 0x33 0x2c 0x2f 0x5700 0x7580 0x8000 0x00 0x31 0x2c 0x2f 0x2c 0x2f 0x5c00 0x7480 0x8000 0x00 0x32 0x28 0x2b 0x2c 0x2f 0x6100 0x7400 0x8000 0x00 0x33 0x24 0x27 0x2c 0x2f 0x6600 0x7380 0x8000 0x00 0x34 0x20 0x23 0x2c 0x2f 0x6b00 0x7300 0x8000 0x00 0x35 0x1c 0x1f 0x2c 0x2f 0x7000 0x7280 0x8000 0x00 0x36 0x18 0x1b 0x2c 0x2f 0x7600 0x7200 0x8000 0x00 0x37 0x14 0x17 0x2c 0x2f 0x7b80 0x7180 0x8000 0x00 0x38 0x10 0x13 0x2c 0x2f 0x8000 0x6f00 0x7e80 0x00 0x39 0x0c 0x0f 0x2c 0x2f 0x8000 0x6880 0x7800 0x00 0x3a 0x08 0x0b 0x2c 0x2f 0x8000 0x6100 0x7180 0x00 0x3b 0x04 0x07 0x2c 0x2f 0x8000 0x5800 0x6980 0x00 0x3c 0x00 0x03 0x2c 0x2f 0x8000 0x4e00 0x6080 0x00 0x3d 0x38 0x3b 0x28 0x2b 0x5300 0x7a80 0x8000 0x00 0x3e 0x34 0x37 0x28 0x2b 0x5700 0x7980 0x8000 0x00 0x3f 0x30 0x33 0x28 0x2b 0x5c00 0x7880 0x8000 0x00 0x40 0x2c 0x2f 0x28 0x2b 0x6080 0x7800 0x8000 0x00 0x41 0x28 0x2b 0x28 0x2b 0x6500 0x7780 0x8000 0x00 0x42 0x24 0x27 0x28 0x2b 0x6a00 0x7700 0x8000 0x00 0x43 0x20 0x23 0x28 0x2b 0x6f80 0x7600 0x8000 0x00 0x44 0x1c 0x1f 0x28 0x2b 0x7480 0x7580 0x8000 0x00 0x45 0x18 0x1b 0x28 0x2b 0x7980 0x7500 0x8000 0x00 0x46 0x14 0x17 0x28 0x2b 0x8000 0x7480 0x8000 0x00 0x47 0x10 0x13 0x28 0x2b 0x8000 0x6e80 0x7b00 0x00 0x48 0x0c 0x0f 0x28 0x2b 0x8000 0x6780 0x7500 0x00 0x49 0x08 0x0b 0x28 0x2b 0x8000 0x5f80 0x6d80 0x00 0x4a 0x04 0x07 0x28 0x2b 0x8000 0x5600 0x6600 0x00 0x4b 0x00 0x03 0x28 0x2b 0x8000 0x4b00 0x5d00 0x00 0x4c 0x38 0x3b 0x24 0x27 0x5700 0x7e80 0x8000 0x00 0x4d 0x34 0x37 0x24 0x27 0x5b80 0x7e00 0x8000 0x00 0x4e 0x30 0x33 0x24 0x27 0x6000 0x7c80 0x8000 0x00 0x4f 0x2c 0x2f 0x24 0x27 0x6480 0x7c00 0x8000 0x00 0x50 0x28 0x2b 0x24 0x27 0x6980 0x7b00 0x8000 0x00 0x51 0x24 0x27 0x24 0x27 0x6d80 0x7a00 0x8000 0x00 0x52 0x20 0x23 0x24 0x27 0x7300 0x7980 0x8000 0x00 0x53 0x1c 0x1f 0x24 0x27 0x7800 0x7900 0x8000 0x00 0x54 0x18 0x1b 0x24 0x27 0x7e00 0x7800 0x8000 0x00 0x55 0x14 0x17 0x24 0x27 0x8000 0x7400 0x7d00 0x00 0x56 0x10 0x13 0x24 0x27 0x8000 0x6d80 0x7780 0x00 0x57 0x0c 0x0f 0x24 0x27 0x8000 0x6680 0x7180 0x00 0x58 0x08 0x0b 0x24 0x27 0x8000 0x5d80 0x6b00 0x00 0x59 0x04 0x07 0x24 0x27 0x8000 0x5400 0x6300 0x00 0x5a 0x00 0x03 0x24 0x27 0x8000 0x4780 0x5980 0x00 0x5b 0x38 0x3b 0x20 0x23 0x5800 0x8000 0x7e00 0x00 0x5c 0x34 0x37 0x20 0x23 0x5d80 0x8000 0x7f00 0x00 0x5d 0x30 0x33 0x20 0x23 0x6300 0x8000 0x7f80 0x00 0x5e 0x2c 0x2f 0x20 0x23 0x6880 0x8000 0x8000 0x00 0x5f 0x28 0x2b 0x20 0x23 0x6c80 0x7f00 0x8000 0x00 0x60 0x24 0x27 0x20 0x23 0x7180 0x7e00 0x8000 0x00 0x61 0x20 0x23 0x20 0x23 0x7680 0x7d00 0x8000 0x00 0x62 0x1c 0x1f 0x20 0x23 0x7b80 0x7c80 0x8000 0x00 0x63 0x18 0x1b 0x20 0x23 0x8000 0x7980 0x7f00 0x00 0x64 0x14 0x17 0x20 0x23 0x8000 0x7380 0x7a80 0x00 0x65 0x10 0x13 0x20 0x23 0x8000 0x6d00 0x7500 0x00 0x66 0x0c 0x0f 0x20 0x23 0x8000 0x6580 0x6f00 0x00 0x67 0x08 0x0b 0x20 0x23 0x8000 0x5c00 0x6800 0x00 0x68 0x04 0x07 0x20 0x23 0x8000 0x5180 0x6080 0x00 0x69 0x00 0x03 0x20 0x23 0x8000 0x4400 0x5680 0x00 0x6a 0x38 0x3b 0x1c 0x1f 0x5600 0x8000 0x7b00 0x00 0x6b 0x34 0x37 0x1c 0x1f 0x5c00 0x8000 0x7c00 0x00 0x6c 0x30 0x33 0x1c 0x1f 0x6200 0x8000 0x7d00 0x00 0x6d 0x2c 0x2f 0x1c 0x1f 0x6780 0x8000 0x7d80 0x00 0x6e 0x28 0x2b 0x1c 0x1f 0x6d00 0x8000 0x7e00 0x00 0x6f 0x24 0x27 0x1c 0x1f 0x7300 0x8000 0x7f00 0x00 0x70 0x20 0x23 0x1c 0x1f 0x7900 0x8000 0x7f80 0x00 0x71 0x18 0x1b 0x1c 0x1f 0x8000 0x7980 0x7c80 0x00 0x72 0x14 0x17 0x1c 0x1f 0x8000 0x7300 0x7780 0x00 0x73 0x10 0x13 0x1c 0x1f 0x8000 0x6c00 0x7200 0x00 0x74 0x0c 0x0f 0x1c 0x1f 0x8000 0x6400 0x6b80 0x00 0x75 0x08 0x0b 0x1c 0x1f 0x8000 0x5a80 0x6500 0x00 0x76 0x04 0x07 0x1c 0x1f 0x8000 0x5000 0x5d80 0x00 0x77 0x00 0x03 0x1c 0x1f 0x8000 0x4100 0x5400 0x00 0x78 0x38 0x3b 0x18 0x1b 0x5480 0x8000 0x7800 0x00 0x79 0x34 0x37 0x18 0x1b 0x5b00 0x8000 0x7880 0x00 0x7a 0x30 0x33 0x18 0x1b 0x6100 0x8000 0x7a00 0x00 0x7b 0x2c 0x2f 0x18 0x1b 0x6700 0x8000 0x7b00 0x00 0x7c 0x28 0x2b 0x18 0x1b 0x6c80 0x8000 0x7b80 0x00 0x7d 0x24 0x27 0x18 0x1b 0x7280 0x8000 0x7c80 0x00 0x7e 0x20 0x23 0x18 0x1b 0x7880 0x8000 0x7d00 0x00 0x7f 0x1c 0x1f 0x18 0x1b 0x8000 0x8000 0x7d80 0x00 0x80 0x18 0x1b 0x18 0x1b 0x8000 0x7980 0x7a00 0x00 0x81 0x14 0x17 0x18 0x1b 0x8000 0x7300 0x7500 0x00 0x82 0x10 0x13 0x18 0x1b 0x8000 0x6b00 0x6f80 0x00 0x83 0x0c 0x0f 0x18 0x1b 0x8000 0x6300 0x6980 0x00 0x84 0x08 0x0b 0x18 0x1b 0x8000 0x5900 0x6300 0x00 0x85 0x04 0x07 0x18 0x1b 0x8000 0x4d00 0x5a80 0x00 0x86 0x00 0x03 0x18 0x1b 0x8000 0x3d00 0x5100 0x00 0x87 0x38 0x3b 0x14 0x17 0x5300 0x8000 0x7500 0x00 0x88 0x34 0x37 0x14 0x17 0x5980 0x8000 0x7600 0x00 0x89 0x30 0x33 0x14 0x17 0x5f80 0x8000 0x7700 0x00 0x8a 0x2c 0x2f 0x14 0x17 0x6600 0x8000 0x7800 0x00 0x8b 0x28 0x2b 0x14 0x17 0x6b80 0x8000 0x7880 0x00 0x8c 0x24 0x27 0x14 0x17 0x7200 0x8000 0x7a00 0x00 0x8d 0x20 0x23 0x14 0x17 0x7800 0x8000 0x7a80 0x00 0x8e 0x1c 0x1f 0x14 0x17 0x7f00 0x8000 0x7b80 0x00 0x8f 0x18 0x1b 0x14 0x17 0x8000 0x7900 0x7700 0x00 0x90 0x14 0x17 0x14 0x17 0x8000 0x7280 0x7280 0x00 0x91 0x10 0x13 0x14 0x17 0x8000 0x7280 0x7280 0x00 0x92 0x0c 0x0f 0x14 0x17 0x8000 0x6a80 0x6d00 0x00 0x93 0x08 0x0b 0x14 0x17 0x8000 0x6180 0x6700 0x00 0x94 0x04 0x07 0x14 0x17 0x8000 0x4a80 0x5800 0x00 0x95 0x00 0x03 0x14 0x17 0x8000 0x3980 0x4e80 0x00 0x96 0x38 0x3b 0x10 0x13 0x5180 0x8000 0x7280 0x00 0x97 0x34 0x37 0x10 0x13 0x5800 0x8000 0x7380 0x00 0x98 0x30 0x33 0x10 0x13 0x5e80 0x8000 0x7480 0x00 0x99 0x2c 0x2f 0x10 0x13 0x6500 0x8000 0x7580 0x00 0x9a 0x28 0x2b 0x10 0x13 0x6b80 0x8000 0x7680 0x00 0x9b 0x24 0x27 0x10 0x13 0x7180 0x8000 0x7700 0x00 0x9c 0x20 0x23 0x10 0x13 0x7800 0x8000 0x7800 0x00 0x9d 0x1c 0x1f 0x10 0x13 0x7f00 0x8000 0x7880 0x00 0x9e 0x18 0x1b 0x10 0x13 0x8000 0x7900 0x7500 0x00 0x9f 0x14 0x17 0x10 0x13 0x8000 0x7200 0x7080 0x00 0xa0 0x10 0x13 0x10 0x13 0x8000 0x7200 0x7080 0x00 0xa1 0x0c 0x0f 0x10 0x13 0x8000 0x6980 0x6a80 0x00 0xa2 0x08 0x0b 0x10 0x13 0x8000 0x6080 0x6500 0x00 0xa3 0x04 0x07 0x10 0x13 0x8000 0x4800 0x5600 0x00 0xa4 0x00 0x03 0x10 0x13 0x8000 0x3500 0x4c00 0x00 0xa5 0x38 0x3b 0x0c 0x0f 0x5000 0x8000 0x7000 0x00 0xa6 0x34 0x37 0x0c 0x0f 0x5600 0x8000 0x7180 0x00 0xa7 0x30 0x33 0x0c 0x0f 0x5d00 0x8000 0x7280 0x00 0xa8 0x2c 0x2f 0x0c 0x0f 0x6400 0x8000 0x7380 0x00 0xa9 0x28 0x2b 0x0c 0x0f 0x6a80 0x8000 0x7400 0x00 0xaa 0x24 0x27 0x0c 0x0f 0x7100 0x8000 0x7500 0x00 0xab 0x20 0x23 0x0c 0x0f 0x7780 0x8000 0x7600 0x00 0xac 0x1c 0x1f 0x0c 0x0f 0x7f00 0x8000 0x7680 0x00 0xad 0x18 0x1b 0x0c 0x0f 0x8000 0x7900 0x7300 0x00 0xae 0x14 0x17 0x0c 0x0f 0x8000 0x7180 0x6e00 0x00 0xaf 0x10 0x13 0x0c 0x0f 0x8000 0x7180 0x6e00 0x00 0xb0 0x0c 0x0f 0x0c 0x0f 0x8000 0x6900 0x6900 0x00 0xb1 0x08 0x0b 0x0c 0x0f 0x8000 0x5f00 0x6380 0x00 0xb2 0x04 0x07 0x0c 0x0f 0x8000 0x4500 0x5400 0x00 0xb3 0x00 0x03 0x0c 0x0f 0x8000 0x3080 0x4a00 0x00 0xb4 0x38 0x3b 0x08 0x0b 0x4d80 0x8000 0x6d80 0x00 0xb5 0x34 0x37 0x08 0x0b 0x5480 0x8000 0x6e80 0x00 0xb6 0x30 0x33 0x08 0x0b 0x5c00 0x8000 0x7000 0x00 0xb7 0x2c 0x2f 0x08 0x0b 0x6300 0x8000 0x7100 0x00 0xb8 0x28 0x2b 0x08 0x0b 0x6a00 0x8000 0x7200 0x00 0xb9 0x24 0x27 0x08 0x0b 0x7080 0x8000 0x7300 0x00 0xba 0x20 0x23 0x08 0x0b 0x7700 0x8000 0x7400 0x00 0xbb 0x1c 0x1f 0x08 0x0b 0x7f00 0x8000 0x7480 0x00 0xbc 0x18 0x1b 0x08 0x0b 0x8000 0x7900 0x7180 0x00 0xbd 0x14 0x17 0x08 0x0b 0x8000 0x7100 0x6c00 0x00 0xbe 0x10 0x13 0x08 0x0b 0x8000 0x7100 0x6c00 0x00 0xbf 0x0c 0x0f 0x08 0x0b 0x8000 0x6880 0x6780 0x00 0xc0 0x08 0x0b 0x08 0x0b 0x8000 0x5d80 0x6180 0x00 0xc1 0x04 0x07 0x08 0x0b 0x8000 0x4280 0x5200 0x00 0xc2 0x00 0x03 0x08 0x0b 0x8000 0x2b00 0x4780 0x00 0xc3 0x38 0x3b 0x04 0x07 0x4b80 0x8000 0x6b80 0x00 0xc4 0x34 0x37 0x04 0x07 0x5300 0x8000 0x6c80 0x00 0xc5 0x30 0x33 0x04 0x07 0x5a80 0x8000 0x6d80 0x00 0xc6 0x2c 0x2f 0x04 0x07 0x6200 0x8000 0x6f80 0x00 0xc7 0x28 0x2b 0x04 0x07 0x6900 0x8000 0x7080 0x00 0xc8 0x24 0x27 0x04 0x07 0x7000 0x8000 0x7100 0x00 0xc9 0x20 0x23 0x04 0x07 0x7680 0x8000 0x7200 0x00 0xca 0x1c 0x1f 0x04 0x07 0x7e80 0x8000 0x7300 0x00 0xcb 0x18 0x1b 0x04 0x07 0x8000 0x7880 0x6f80 0x00 0xcc 0x14 0x17 0x04 0x07 0x8000 0x7080 0x6a80 0x00 0xcd 0x10 0x13 0x04 0x07 0x8000 0x6780 0x6580 0x00 0xce 0x0c 0x0f 0x04 0x07 0x8000 0x5c80 0x6080 0x00 0xcf 0x08 0x0b 0x04 0x07 0x8000 0x5000 0x5880 0x00 0xd0 0x04 0x07 0x04 0x07 0x8000 0x3f80 0x5080 0x00 0xd1 0x00 0x03 0x04 0x07 0x8000 0x2800 0x4580 0x00 0xd2 0x38 0x3b 0x00 0x03 0x4900 0x8000 0x6a00 0x00 0xd3 0x34 0x37 0x00 0x03 0x5180 0x8000 0x6a80 0x00 0xd4 0x30 0x33 0x00 0x03 0x5900 0x8000 0x6c00 0x00 0xd5 0x2c 0x2f 0x00 0x03 0x6080 0x8000 0x6d00 0x00 0xd6 0x28 0x2b 0x00 0x03 0x6800 0x8000 0x6e00 0x00 0xd7 0x24 0x27 0x00 0x03 0x6f80 0x8000 0x6f80 0x00 0xd8 0x20 0x23 0x00 0x03 0x7680 0x8000 0x7080 0x00 0xd9 0x1c 0x1f 0x00 0x03 0x7e80 0x8000 0x7180 0x00 0xda 0x18 0x1b 0x00 0x03 0x8000 0x7880 0x6d80 0x00 0xdb 0x14 0x17 0x00 0x03 0x8000 0x7000 0x6980 0x00 0xdc 0x10 0x13 0x00 0x03 0x8000 0x6680 0x6400 0x00 0xdd 0x0c 0x0f 0x00 0x03 0x8000 0x5b00 0x5e80 0x00 0xde 0x08 0x0b 0x00 0x03 0x8000 0x4e00 0x5700 0x00 0xdf 0x04 0x07 0x00 0x03 0x8000 0x3b80 0x4f00 0x00 0xe0 0x00 0x03 0x00 0x03 0x8000 0x2800 0x4380 0xff 0x00 0x00 0x3b 0x00 0x3b 0x8000 0x8000 0x8000>;
			};

			somc,auo_novatek_fullhd_cmd_panel {
				qcom,mdss-dsi-panel-name = [34 00];
				qcom,mdss-dsi-panel-controller = <0x2b>;
				qcom,mdss-dsi-panel-destination = "display_1";
				qcom,mdss-dsi-panel-type = "dsi_cmd_mode";
				qcom,mdss-dsi-panel-width = <0x438>;
				qcom,mdss-dsi-panel-height = <0x780>;
				qcom,mdss-dsi-bpp = <0x18>;
				qcom,mdss-dsi-h-back-porch = <0x08>;
				qcom,mdss-dsi-h-pulse-width = <0x08>;
				qcom,mdss-dsi-h-front-porch = <0x38>;
				qcom,mdss-dsi-v-back-porch = <0x08>;
				qcom,mdss-dsi-v-pulse-width = <0x02>;
				qcom,mdss-dsi-v-front-porch = <0xe9>;
				qcom,mdss-pan-physical-width-dimension = <0x40>;
				qcom,mdss-pan-physical-height-dimension = <0x72>;
				qcom,mdss-dsi-panel-framerate = <0x3c>;
				qcom,mdss-dsi-virtual-channel-id = <0x00>;
				qcom,mdss-dsi-stream = <0x00>;
				qcom,mdss-dsi-h-sync-skew = <0x00>;
				qcom,mdss-dsi-h-left-border = <0x00>;
				qcom,mdss-dsi-h-right-border = <0x00>;
				qcom,mdss-dsi-v-top-border = <0x00>;
				qcom,mdss-dsi-v-bottom-border = <0x00>;
				qcom,mdss-dsi-underflow-color = <0x00>;
				qcom,mdss-dsi-border-color = <0x00>;
				qcom,mdss-dsi-h-sync-pulse = <0x01>;
				qcom,mdss-dsi-traffic-mode = "non_burst_sync_event";
				qcom,mdss-dsi-bllp-eof-power-mode;
				qcom,mdss-dsi-bllp-power-mode;
				qcom,mdss-dsi-dma-trigger = "trigger_sw";
				qcom,mdss-dsi-mdp-trigger = "none";
				somc,mdss-dsi-init-command = [15 01 00 00 00 00 02 ff e0 15 01 00 00 00 00 02 fb 01 15 01 00 00 00 00 02 b5 86 15 01 00 00 00 00 02 b6 77 15 01 00 00 00 00 02 b8 ad 15 01 00 00 00 00 02 ff 20 15 01 00 00 00 00 02 fb 01 15 01 00 00 00 00 02 2d 94 15 01 00 00 00 00 02 ff 24 15 01 00 00 00 00 02 fb 01 15 01 00 00 00 00 02 c6 00 15 01 00 00 00 00 02 92 8b 15 01 00 00 00 00 02 c5 32 15 01 00 00 00 00 02 ff 10 15 01 00 00 00 00 02 35 00 39 01 00 00 00 00 03 44 03 00 39 01 00 00 00 00 04 3b 03 30 06 15 01 00 00 01 00 02 bb 10 05 01 00 00 1e 00 01 11];
				qcom,mdss-dsi-on-command = <0x5010000 0x28000129>;
				qcom,mdss-dsi-off-command = <0x5010000 0x128 0x5010000 0x64000110>;
				qcom,mdss-dsi-on-command-state = "dsi_lp_mode";
				qcom,mdss-dsi-off-command-state = "dsi_hs_mode";
				qcom,mdss-dsi-te-pin-select = <0x01>;
				qcom,mdss-dsi-wr-mem-start = <0x2c>;
				qcom,mdss-dsi-wr-mem-continue = <0x3c>;
				qcom,mdss-dsi-te-dcs-command = <0x01>;
				qcom,mdss-dsi-te-check-enable;
				qcom,mdss-dsi-te-using-te-pin;
				qcom,mdss-dsi-lane-0-state;
				qcom,mdss-dsi-lane-1-state;
				qcom,mdss-dsi-lane-2-state;
				qcom,mdss-dsi-lane-3-state;
				qcom,mdss-dsi-panel-timings = <0xe6382600 0x6866323c 0x2c030400>;
				qcom,mdss-dsi-t-clk-post = <0x21>;
				qcom,mdss-dsi-t-clk-pre = <0x2b>;
				qcom,mdss-dsi-tx-eot-append;
				qcom,mdss-dsi-lp11-init;
				qcom,mdss-dsi-bl-min-level = <0x01>;
				qcom,mdss-dsi-bl-max-level = <0xfff>;
				qcom,mdss-brightness-max-level = <0xfff>;
				qcom,mdss-dsi-bl-pmic-control-type = "bl_ctrl_wled";
				qcom,qpnp-lab-limit-maximum-current = <0xc8>;
				qcom,qpnp-ibb-limit-maximum-current = <0x320>;
				somc,mdss-dsi-disp-on-in-hs = <0x00>;
				somc,mdss-dsi-wait-time-before-on-cmd = <0x00>;
				somc,platform-regulator-settings = [03 03 03 00 20 00 01];
				somc,mdss-dsi-lane-config = [02 00 ef 00 20 00 00 01 ff 02 00 ef 00 40 00 00 01 ff 02 00 ef 40 20 00 00 01 ff 02 00 ef 40 00 00 00 01 ff 00 00 45 80 00 00 00 01 97];
				somc,disp-en-on-pre = <0x01>;
				somc,pw-on-rst-seq = <0x00 0x14 0x01 0x0a>;
				somc,disp-en-off-post = <0x46>;
				somc,pw-off-rst-seq = <0x00 0x00>;
				somc,pw-down-period = <0x64>;
				somc,lab-output-voltage = <0x5265c0>;
				somc,ibb-output-voltage = <0x5265c0>;
				somc,lcd-id = <0x01>;
				somc,lcd-id-adc = <0x109618 0x12c898>;
				somc,mdss-dsi-master;
				somc,change-fps-enable;
				somc,change-fps-command = [15 01 00 00 00 00 02 ff 24 15 01 00 00 00 00 02 92 8b 15 01 00 00 00 00 02 ff 10 39 01 00 00 00 00 03 44 03 00];
				somc,display-clock = <0xfe3620>;
				somc,driver-ic-vbp = <0x30>;
				somc,driver-ic-vfp = <0x06>;
				somc,change-fps-rtn-adj;
				somc,change-fps-rtn-pos = <0x01 0x01>;
				somc,fps-threshold = <0xb928>;
				somc,te-c-mode-60fps = <0x03 0x00>;
				somc,te-c-mode-45fps = <0x04 0xff>;
				somc,te-c-mode-pos = <0x03 0x01>;
				somc,mdss-dsi-lock-command = [15 01 00 00 00 00 02 ff 10 15 01 00 00 00 00 02 fb 01 15 01 00 00 00 00 02 f0 55 15 01 00 00 00 00 02 f1 aa 15 01 00 00 01 00 02 f2 66];
				somc,mdss-dsi-unlock-command = [15 01 00 00 00 00 02 ff 10 15 01 00 00 00 00 02 fb 01 15 01 00 00 00 00 02 f0 aa 15 01 00 00 00 00 02 f1 55 15 01 00 00 01 00 02 f2 99];
				somc,mdss-dsi-pcc-enable;
				somc,mdss-dsi-uv-command = <0x6010000 0x1da 0x6010000 0x1db>;
				somc,mdss-dsi-uv-param-type = <0x04>;
				somc,mdss-dsi-pcc-table-size = <0xe1>;
				somc,mdss-dsi-pcc-table = <0x00 0x01 0x38 0x3b 0x38 0x3b 0x5600 0x7280 0x8000 0x00 0x02 0x34 0x37 0x38 0x3b 0x5980 0x7280 0x8000 0x00 0x03 0x30 0x33 0x38 0x3b 0x5d80 0x7200 0x8000 0x00 0x04 0x2c 0x2f 0x38 0x3b 0x6180 0x7180 0x8000 0x00 0x05 0x28 0x2b 0x38 0x3b 0x6580 0x7180 0x8000 0x00 0x06 0x24 0x27 0x38 0x3b 0x6a00 0x7100 0x8000 0x00 0x07 0x20 0x23 0x38 0x3b 0x6e80 0x7080 0x8000 0x00 0x08 0x1c 0x1f 0x38 0x3b 0x7380 0x7080 0x8000 0x00 0x09 0x18 0x1b 0x38 0x3b 0x7880 0x7000 0x8000 0x00 0x0a 0x14 0x17 0x38 0x3b 0x7e00 0x7000 0x8000 0x00 0x0b 0x10 0x13 0x38 0x3b 0x8000 0x6d00 0x7d00 0x00 0x0c 0x0c 0x0f 0x38 0x3b 0x8000 0x6780 0x7680 0x00 0x0d 0x08 0x0b 0x38 0x3b 0x8000 0x6100 0x6f00 0x00 0x0e 0x04 0x07 0x38 0x3b 0x8000 0x5980 0x6600 0x00 0x0f 0x00 0x03 0x38 0x3b 0x8000 0x5100 0x5b80 0x00 0x10 0x38 0x3b 0x34 0x37 0x5a80 0x7680 0x8000 0x00 0x11 0x34 0x37 0x34 0x37 0x5e00 0x7600 0x8000 0x00 0x12 0x30 0x33 0x34 0x37 0x6200 0x7580 0x8000 0x00 0x13 0x2c 0x2f 0x34 0x37 0x6600 0x7500 0x8000 0x00 0x14 0x28 0x2b 0x34 0x37 0x6a00 0x7480 0x8000 0x00 0x15 0x24 0x27 0x34 0x37 0x6e80 0x7400 0x8000 0x00 0x16 0x20 0x23 0x34 0x37 0x7300 0x7400 0x8000 0x00 0x17 0x1c 0x1f 0x34 0x37 0x7800 0x7380 0x8000 0x00 0x18 0x18 0x1b 0x34 0x37 0x7d00 0x7300 0x8000 0x00 0x19 0x14 0x17 0x34 0x37 0x8000 0x7180 0x7e80 0x00 0x1a 0x10 0x13 0x34 0x37 0x8000 0x6c00 0x7880 0x00 0x1b 0x0c 0x0f 0x34 0x37 0x8000 0x6600 0x7200 0x00 0x1c 0x08 0x0b 0x34 0x37 0x8000 0x5f80 0x6a00 0x00 0x1d 0x04 0x07 0x34 0x37 0x8000 0x5780 0x6100 0x00 0x1e 0x00 0x03 0x34 0x37 0x8000 0x4e00 0x5680 0x00 0x1f 0x38 0x3b 0x30 0x33 0x5f00 0x7a00 0x8000 0x00 0x20 0x34 0x37 0x30 0x33 0x6280 0x7980 0x8000 0x00 0x21 0x30 0x33 0x30 0x33 0x6600 0x7900 0x8000 0x00 0x22 0x2c 0x2f 0x30 0x33 0x6a00 0x7880 0x8000 0x00 0x23 0x28 0x2b 0x30 0x33 0x6e80 0x7800 0x8000 0x00 0x24 0x24 0x27 0x30 0x33 0x7280 0x7780 0x8000 0x00 0x25 0x20 0x23 0x30 0x33 0x7700 0x7700 0x8000 0x00 0x26 0x1c 0x1f 0x30 0x33 0x7c00 0x7680 0x8000 0x00 0x27 0x18 0x1b 0x30 0x33 0x8000 0x7580 0x7f80 0x00 0x28 0x14 0x17 0x30 0x33 0x8000 0x7100 0x7a80 0x00 0x29 0x10 0x13 0x30 0x33 0x8000 0x6b00 0x7480 0x00 0x2a 0x0c 0x0f 0x30 0x33 0x8000 0x6500 0x6e00 0x00 0x2b 0x08 0x0b 0x30 0x33 0x8000 0x5e00 0x6600 0x00 0x2c 0x04 0x07 0x30 0x33 0x8000 0x5580 0x5d00 0x00 0x2d 0x00 0x03 0x30 0x33 0x8000 0x4b00 0x5200 0x00 0x2e 0x38 0x3b 0x2c 0x2f 0x6300 0x7d80 0x8000 0x00 0x2f 0x34 0x37 0x2c 0x2f 0x6680 0x7c80 0x8000 0x00 0x30 0x30 0x33 0x2c 0x2f 0x6a00 0x7c00 0x8000 0x00 0x31 0x2c 0x2f 0x2c 0x2f 0x6e00 0x7b80 0x8000 0x00 0x32 0x28 0x2b 0x2c 0x2f 0x7280 0x7b00 0x8000 0x00 0x33 0x24 0x27 0x2c 0x2f 0x7680 0x7a80 0x8000 0x00 0x34 0x20 0x23 0x2c 0x2f 0x7b00 0x7a00 0x8000 0x00 0x35 0x1c 0x1f 0x2c 0x2f 0x8000 0x7980 0x8000 0x00 0x36 0x18 0x1b 0x2c 0x2f 0x8000 0x7580 0x7c00 0x00 0x37 0x14 0x17 0x2c 0x2f 0x8000 0x7000 0x7680 0x00 0x38 0x10 0x13 0x2c 0x2f 0x8000 0x6a80 0x7100 0x00 0x39 0x0c 0x0f 0x2c 0x2f 0x8000 0x6400 0x6a00 0x00 0x3a 0x08 0x0b 0x2c 0x2f 0x8000 0x5c00 0x6200 0x00 0x3b 0x04 0x07 0x2c 0x2f 0x8000 0x5300 0x5880 0x00 0x3c 0x00 0x03 0x2c 0x2f 0x8000 0x4880 0x4d80 0x00 0x3d 0x38 0x3b 0x28 0x2b 0x6600 0x8000 0x8000 0x00 0x3e 0x34 0x37 0x28 0x2b 0x6a00 0x8000 0x8000 0x00 0x3f 0x30 0x33 0x28 0x2b 0x6e00 0x7f80 0x8000 0x00 0x40 0x2c 0x2f 0x28 0x2b 0x7200 0x7f00 0x8000 0x00 0x41 0x28 0x2b 0x28 0x2b 0x7600 0x7e00 0x8000 0x00 0x42 0x24 0x27 0x28 0x2b 0x7a80 0x7d80 0x8000 0x00 0x43 0x20 0x23 0x28 0x2b 0x7f00 0x7d00 0x8000 0x00 0x44 0x1c 0x1f 0x28 0x2b 0x8000 0x7a00 0x7d80 0x00 0x45 0x18 0x1b 0x28 0x2b 0x8000 0x7500 0x7880 0x00 0x46 0x14 0x17 0x28 0x2b 0x8000 0x6f80 0x7380 0x00 0x47 0x10 0x13 0x28 0x2b 0x8000 0x6980 0x6d80 0x00 0x48 0x0c 0x0f 0x28 0x2b 0x8000 0x6280 0x6680 0x00 0x49 0x08 0x0b 0x28 0x2b 0x8000 0x5a80 0x5e80 0x00 0x4a 0x04 0x07 0x28 0x2b 0x8000 0x5100 0x5500 0x00 0x4b 0x00 0x03 0x28 0x2b 0x8000 0x4580 0x4980 0x00 0x4c 0x38 0x3b 0x24 0x27 0x6500 0x8000 0x7c00 0x00 0x4d 0x34 0x37 0x24 0x27 0x6980 0x8000 0x7d00 0x00 0x4e 0x30 0x33 0x24 0x27 0x6e80 0x8000 0x7d80 0x00 0x4f 0x2c 0x2f 0x24 0x27 0x7300 0x8000 0x7e80 0x00 0x50 0x28 0x2b 0x24 0x27 0x7800 0x8000 0x7f00 0x00 0x51 0x24 0x27 0x24 0x27 0x7d80 0x8000 0x8000 0x00 0x52 0x20 0x23 0x24 0x27 0x8000 0x7e80 0x7e80 0x00 0x53 0x1c 0x1f 0x24 0x27 0x8000 0x7a00 0x7a00 0x00 0x54 0x18 0x1b 0x24 0x27 0x8000 0x7500 0x7580 0x00 0x55 0x14 0x17 0x24 0x27 0x8000 0x6f00 0x7000 0x00 0x56 0x10 0x13 0x24 0x27 0x8000 0x6880 0x6a00 0x00 0x57 0x0c 0x0f 0x24 0x27 0x8000 0x6180 0x6300 0x00 0x58 0x08 0x0b 0x24 0x27 0x8000 0x5880 0x5b00 0x00 0x59 0x04 0x07 0x24 0x27 0x8000 0x4e80 0x5180 0x00 0x5a 0x00 0x03 0x24 0x27 0x8000 0x4280 0x4580 0x00 0x5b 0x38 0x3b 0x20 0x23 0x6380 0x8000 0x7880 0x00 0x5c 0x34 0x37 0x20 0x23 0x6880 0x8000 0x7980 0x00 0x5d 0x30 0x33 0x20 0x23 0x6d80 0x8000 0x7a00 0x00 0x5e 0x2c 0x2f 0x20 0x23 0x7280 0x8000 0x7b00 0x00 0x5f 0x28 0x2b 0x20 0x23 0x7780 0x8000 0x7c00 0x00 0x60 0x24 0x27 0x20 0x23 0x7d00 0x8000 0x7c80 0x00 0x61 0x20 0x23 0x20 0x23 0x8000 0x7e80 0x7b80 0x00 0x62 0x1c 0x1f 0x20 0x23 0x8000 0x7a00 0x7700 0x00 0x63 0x18 0x1b 0x20 0x23 0x8000 0x7480 0x7280 0x00 0x64 0x14 0x17 0x20 0x23 0x8000 0x6e80 0x6d00 0x00 0x65 0x10 0x13 0x20 0x23 0x8000 0x6800 0x6700 0x00 0x66 0x0c 0x0f 0x20 0x23 0x8000 0x6000 0x6000 0x00 0x67 0x08 0x0b 0x20 0x23 0x8000 0x5700 0x5800 0x00 0x68 0x04 0x07 0x20 0x23 0x8000 0x4c00 0x4e00 0x00 0x69 0x00 0x03 0x20 0x23 0x8000 0x3f00 0x4200 0x00 0x6a 0x38 0x3b 0x1c 0x1f 0x6280 0x8000 0x7500 0x00 0x6b 0x34 0x37 0x1c 0x1f 0x6780 0x8000 0x7600 0x00 0x6c 0x30 0x33 0x1c 0x1f 0x6c80 0x8000 0x7700 0x00 0x6d 0x2c 0x2f 0x1c 0x1f 0x7200 0x8000 0x7800 0x00 0x6e 0x28 0x2b 0x1c 0x1f 0x7700 0x8000 0x7880 0x00 0x6f 0x24 0x27 0x1c 0x1f 0x7c80 0x8000 0x7980 0x00 0x70 0x20 0x23 0x1c 0x1f 0x8000 0x7f00 0x7900 0x00 0x71 0x18 0x1b 0x1c 0x1f 0x8000 0x7480 0x6f80 0x00 0x72 0x14 0x17 0x1c 0x1f 0x8000 0x6e00 0x6a80 0x00 0x73 0x10 0x13 0x1c 0x1f 0x8000 0x6700 0x6400 0x00 0x74 0x0c 0x0f 0x1c 0x1f 0x8000 0x5f00 0x5d00 0x00 0x75 0x08 0x0b 0x1c 0x1f 0x8000 0x5500 0x5500 0x00 0x76 0x04 0x07 0x1c 0x1f 0x8000 0x4a00 0x4b00 0x00 0x77 0x00 0x03 0x1c 0x1f 0x8000 0x3c00 0x3f00 0x00 0x78 0x38 0x3b 0x18 0x1b 0x6100 0x8000 0x7200 0x00 0x79 0x34 0x37 0x18 0x1b 0x6600 0x8000 0x7300 0x00 0x7a 0x30 0x33 0x18 0x1b 0x6b80 0x8000 0x7400 0x00 0x7b 0x2c 0x2f 0x18 0x1b 0x7100 0x8000 0x7500 0x00 0x7c 0x28 0x2b 0x18 0x1b 0x7680 0x8000 0x7600 0x00 0x7d 0x24 0x27 0x18 0x1b 0x7c00 0x8000 0x7680 0x00 0x7e 0x20 0x23 0x18 0x1b 0x8000 0x7f00 0x7680 0x00 0x7f 0x1c 0x1f 0x18 0x1b 0x8000 0x7a00 0x7200 0x00 0x80 0x18 0x1b 0x18 0x1b 0x8000 0x7400 0x6d00 0x00 0x81 0x14 0x17 0x18 0x1b 0x8000 0x6d80 0x6800 0x00 0x82 0x10 0x13 0x18 0x1b 0x8000 0x6600 0x6180 0x00 0x83 0x0c 0x0f 0x18 0x1b 0x8000 0x5d80 0x5a80 0x00 0x84 0x08 0x0b 0x18 0x1b 0x8000 0x5380 0x5200 0x00 0x85 0x04 0x07 0x18 0x1b 0x8000 0x4780 0x4800 0x00 0x86 0x00 0x03 0x18 0x1b 0x8000 0x3880 0x3c00 0x00 0x87 0x38 0x3b 0x14 0x17 0x5f80 0x8000 0x6f00 0x00 0x88 0x34 0x37 0x14 0x17 0x6500 0x8000 0x7000 0x00 0x89 0x30 0x33 0x14 0x17 0x6a80 0x8000 0x7100 0x00 0x8a 0x2c 0x2f 0x14 0x17 0x7000 0x8000 0x7200 0x00 0x8b 0x28 0x2b 0x14 0x17 0x7600 0x8000 0x7300 0x00 0x8c 0x24 0x27 0x14 0x17 0x7b80 0x8000 0x7400 0x00 0x8d 0x20 0x23 0x14 0x17 0x8000 0x7f00 0x7400 0x00 0x8e 0x1c 0x1f 0x14 0x17 0x8000 0x7a00 0x6f80 0x00 0x8f 0x18 0x1b 0x14 0x17 0x8000 0x7400 0x6b00 0x00 0x90 0x14 0x17 0x14 0x17 0x8000 0x6d00 0x6580 0x00 0x91 0x10 0x13 0x14 0x17 0x8000 0x6580 0x5f80 0x00 0x92 0x0c 0x0f 0x14 0x17 0x8000 0x5c80 0x5800 0x00 0x93 0x08 0x0b 0x14 0x17 0x8000 0x5180 0x4f80 0x00 0x94 0x04 0x07 0x14 0x17 0x8000 0x4500 0x4580 0x00 0x95 0x00 0x03 0x14 0x17 0x8000 0x3580 0x3900 0x00 0x96 0x38 0x3b 0x10 0x13 0x5e00 0x8000 0x6c00 0x00 0x97 0x34 0x37 0x10 0x13 0x6400 0x8000 0x6d80 0x00 0x98 0x30 0x33 0x10 0x13 0x6980 0x8000 0x6e80 0x00 0x99 0x2c 0x2f 0x10 0x13 0x6f80 0x8000 0x6f80 0x00 0x9a 0x28 0x2b 0x10 0x13 0x7500 0x8000 0x7080 0x00 0x9b 0x24 0x27 0x10 0x13 0x7b00 0x8000 0x7180 0x00 0x9c 0x20 0x23 0x10 0x13 0x8000 0x7f80 0x7200 0x00 0x9d 0x1c 0x1f 0x10 0x13 0x8000 0x7a00 0x6d80 0x00 0x9e 0x18 0x1b 0x10 0x13 0x8000 0x7380 0x6900 0x00 0x9f 0x14 0x17 0x10 0x13 0x8000 0x6c80 0x6380 0x00 0xa0 0x10 0x13 0x10 0x13 0x8000 0x6480 0x5d00 0x00 0xa1 0x0c 0x0f 0x10 0x13 0x8000 0x5b00 0x5600 0x00 0xa2 0x08 0x0b 0x10 0x13 0x8000 0x5000 0x4d80 0x00 0xa3 0x04 0x07 0x10 0x13 0x8000 0x4280 0x4300 0x00 0xa4 0x00 0x03 0x10 0x13 0x8000 0x3200 0x3680 0x00 0xa5 0x38 0x3b 0x0c 0x0f 0x5c80 0x8000 0x6980 0x00 0xa6 0x34 0x37 0x0c 0x0f 0x6280 0x8000 0x6b00 0x00 0xa7 0x30 0x33 0x0c 0x0f 0x6880 0x8000 0x6c00 0x00 0xa8 0x2c 0x2f 0x0c 0x0f 0x6e80 0x8000 0x6d00 0x00 0xa9 0x28 0x2b 0x0c 0x0f 0x7480 0x8000 0x6e80 0x00 0xaa 0x24 0x27 0x0c 0x0f 0x7a80 0x8000 0x6f80 0x00 0xab 0x20 0x23 0x0c 0x0f 0x8000 0x7f80 0x7000 0x00 0xac 0x1c 0x1f 0x0c 0x0f 0x8000 0x7a00 0x6b80 0x00 0xad 0x18 0x1b 0x0c 0x0f 0x8000 0x7380 0x6700 0x00 0xae 0x14 0x17 0x0c 0x0f 0x8000 0x6c00 0x6180 0x00 0xaf 0x10 0x13 0x0c 0x0f 0x8000 0x6380 0x5b00 0x00 0xb0 0x0c 0x0f 0x0c 0x0f 0x8000 0x5980 0x5400 0x00 0xb1 0x08 0x0b 0x0c 0x0f 0x8000 0x4e00 0x4b80 0x00 0xb2 0x04 0x07 0x0c 0x0f 0x8000 0x3f80 0x4100 0x00 0xb3 0x00 0x03 0x0c 0x0f 0x8000 0x2e80 0x3400 0x00 0xb4 0x38 0x3b 0x08 0x0b 0x5b00 0x8000 0x6700 0x00 0xb5 0x34 0x37 0x08 0x0b 0x6100 0x8000 0x6880 0x00 0xb6 0x30 0x33 0x08 0x0b 0x6780 0x8000 0x6980 0x00 0xb7 0x2c 0x2f 0x08 0x0b 0x6d80 0x8000 0x6b00 0x00 0xb8 0x28 0x2b 0x08 0x0b 0x7400 0x8000 0x6c00 0x00 0xb9 0x24 0x27 0x08 0x0b 0x7a00 0x8000 0x6d00 0x00 0xba 0x20 0x23 0x08 0x0b 0x8000 0x8000 0x6e00 0x00 0xbb 0x1c 0x1f 0x08 0x0b 0x8000 0x7a00 0x6a00 0x00 0xbc 0x18 0x1b 0x08 0x0b 0x8000 0x7380 0x6500 0x00 0xbd 0x14 0x17 0x08 0x0b 0x8000 0x6b80 0x5f80 0x00 0xbe 0x10 0x13 0x08 0x0b 0x8000 0x6280 0x5980 0x00 0xbf 0x0c 0x0f 0x08 0x0b 0x8000 0x5880 0x5200 0x00 0xc0 0x08 0x0b 0x08 0x0b 0x8000 0x4c00 0x4980 0x00 0xc1 0x04 0x07 0x08 0x0b 0x8000 0x3d00 0x3f00 0x00 0xc2 0x00 0x03 0x08 0x0b 0x8000 0x2a80 0x3200 0x00 0xc3 0x38 0x3b 0x04 0x07 0x5980 0x8000 0x6480 0x00 0xc4 0x34 0x37 0x04 0x07 0x5f80 0x8000 0x6600 0x00 0xc5 0x30 0x33 0x04 0x07 0x6600 0x8000 0x6780 0x00 0xc6 0x2c 0x2f 0x04 0x07 0x6c80 0x8000 0x6900 0x00 0xc7 0x28 0x2b 0x04 0x07 0x7300 0x8000 0x6a00 0x00 0xc8 0x24 0x27 0x04 0x07 0x7980 0x8000 0x6b00 0x00 0xc9 0x20 0x23 0x04 0x07 0x8000 0x8000 0x6c80 0x00 0xca 0x1c 0x1f 0x04 0x07 0x8000 0x7a00 0x6800 0x00 0xcb 0x18 0x1b 0x04 0x07 0x8000 0x7300 0x6380 0x00 0xcc 0x14 0x17 0x04 0x07 0x8000 0x6b00 0x5e00 0x00 0xcd 0x10 0x13 0x04 0x07 0x8000 0x6200 0x5780 0x00 0xce 0x0c 0x0f 0x04 0x07 0x8000 0x5700 0x5080 0x00 0xcf 0x08 0x0b 0x04 0x07 0x8000 0x4a00 0x4780 0x00 0xd0 0x04 0x07 0x04 0x07 0x8000 0x3a80 0x3d00 0x00 0xd1 0x00 0x03 0x04 0x07 0x8000 0x2700 0x2f80 0x00 0xd2 0x38 0x3b 0x00 0x03 0x5780 0x8000 0x6280 0x00 0xd3 0x34 0x37 0x00 0x03 0x5e00 0x8000 0x6400 0x00 0xd4 0x30 0x33 0x00 0x03 0x6500 0x8000 0x6580 0x00 0xd5 0x2c 0x2f 0x00 0x03 0x6b80 0x8000 0x6700 0x00 0xd6 0x28 0x2b 0x00 0x03 0x7200 0x8000 0x6800 0x00 0xd7 0x24 0x27 0x00 0x03 0x7900 0x8000 0x6980 0x00 0xd8 0x20 0x23 0x00 0x03 0x8000 0x8000 0x6a80 0x00 0xd9 0x1c 0x1f 0x00 0x03 0x8000 0x7a00 0x6680 0x00 0xda 0x18 0x1b 0x00 0x03 0x8000 0x7300 0x6200 0x00 0xdb 0x14 0x17 0x00 0x03 0x8000 0x6a80 0x5c80 0x00 0xdc 0x10 0x13 0x00 0x03 0x8000 0x6100 0x5600 0x00 0xdd 0x0c 0x0f 0x00 0x03 0x8000 0x5580 0x4f00 0x00 0xde 0x08 0x0b 0x00 0x03 0x8000 0x4800 0x4600 0x00 0xdf 0x04 0x07 0x00 0x03 0x8000 0x3780 0x3b80 0x00 0xe0 0x00 0x03 0x00 0x03 0x8000 0x2300 0x2e00 0xff 0x00 0x00 0x3b 0x00 0x3b 0x8000 0x8000 0x8000>;
			};

			somc,default_cmd_panel_0 {
				qcom,mdss-dsi-panel-name = "default";
				qcom,mdss-dsi-panel-controller = <0x2b>;
				qcom,mdss-dsi-panel-destination = "display_1";
				qcom,mdss-dsi-panel-type = "dsi_cmd_mode";
				qcom,mdss-dsi-panel-width = <0x438>;
				qcom,mdss-dsi-panel-height = <0x780>;
				qcom,mdss-dsi-bpp = <0x18>;
				qcom,mdss-dsi-h-back-porch = <0x08>;
				qcom,mdss-dsi-h-pulse-width = <0x08>;
				qcom,mdss-dsi-h-front-porch = <0x38>;
				qcom,mdss-dsi-v-back-porch = <0x08>;
				qcom,mdss-dsi-v-pulse-width = <0x02>;
				qcom,mdss-dsi-v-front-porch = <0xe9>;
				qcom,mdss-pan-physical-width-dimension = <0x40>;
				qcom,mdss-pan-physical-height-dimension = <0x72>;
				qcom,mdss-dsi-panel-framerate = <0x3c>;
				qcom,mdss-dsi-virtual-channel-id = <0x00>;
				qcom,mdss-dsi-stream = <0x00>;
				qcom,mdss-dsi-h-sync-skew = <0x00>;
				qcom,mdss-dsi-h-left-border = <0x00>;
				qcom,mdss-dsi-h-right-border = <0x00>;
				qcom,mdss-dsi-v-top-border = <0x00>;
				qcom,mdss-dsi-v-bottom-border = <0x00>;
				qcom,mdss-dsi-underflow-color = <0x00>;
				qcom,mdss-dsi-border-color = <0x00>;
				qcom,mdss-dsi-h-sync-pulse = <0x01>;
				qcom,mdss-dsi-traffic-mode = "non_burst_sync_event";
				qcom,mdss-dsi-bllp-eof-power-mode;
				qcom,mdss-dsi-bllp-power-mode;
				qcom,mdss-dsi-dma-trigger = "trigger_sw";
				qcom,mdss-dsi-mdp-trigger = "none";
				somc,mdss-dsi-init-command = [15 01 00 00 00 00 02 ff e0 15 01 00 00 00 00 02 fb 01 15 01 00 00 00 00 02 b5 86 15 01 00 00 00 00 02 b6 77 15 01 00 00 00 00 02 b8 ad 15 01 00 00 00 00 02 ff 20 15 01 00 00 00 00 02 fb 01 15 01 00 00 00 00 02 2d 14 15 01 00 00 00 00 02 ff 24 15 01 00 00 00 00 02 fb 01 15 01 00 00 00 00 02 c6 00 15 01 00 00 00 00 02 92 8b 15 01 00 00 00 00 02 c5 32 15 01 00 00 00 00 02 ff 10 15 01 00 00 00 00 02 35 00 39 01 00 00 00 00 03 44 03 00 39 01 00 00 00 00 04 3b 03 30 06 15 01 00 00 01 00 02 bb 10 05 01 00 00 1e 00 01 11];
				qcom,mdss-dsi-on-command = <0x5010000 0x28000129>;
				qcom,mdss-dsi-off-command = <0x5010000 0x128 0x5010000 0x64000110>;
				qcom,mdss-dsi-on-command-state = "dsi_lp_mode";
				qcom,mdss-dsi-off-command-state = "dsi_hs_mode";
				qcom,mdss-dsi-te-pin-select = <0x01>;
				qcom,mdss-dsi-wr-mem-start = <0x2c>;
				qcom,mdss-dsi-wr-mem-continue = <0x3c>;
				qcom,mdss-dsi-te-dcs-command = <0x01>;
				qcom,mdss-dsi-te-check-enable;
				qcom,mdss-dsi-te-using-te-pin;
				qcom,mdss-dsi-lane-0-state;
				qcom,mdss-dsi-lane-1-state;
				qcom,mdss-dsi-lane-2-state;
				qcom,mdss-dsi-lane-3-state;
				qcom,mdss-dsi-panel-timings = <0xe6382600 0x6866323c 0x2c030400>;
				qcom,mdss-dsi-t-clk-post = <0x21>;
				qcom,mdss-dsi-t-clk-pre = <0x2b>;
				qcom,mdss-dsi-tx-eot-append;
				qcom,mdss-dsi-lp11-init;
				qcom,mdss-dsi-bl-min-level = <0x01>;
				qcom,mdss-dsi-bl-max-level = <0xfff>;
				qcom,mdss-brightness-max-level = <0xfff>;
				qcom,mdss-dsi-bl-pmic-control-type = "bl_ctrl_wled";
				qcom,qpnp-lab-limit-maximum-current = <0xc8>;
				qcom,qpnp-ibb-limit-maximum-current = <0x320>;
				somc,mdss-dsi-disp-on-in-hs = <0x00>;
				somc,mdss-dsi-wait-time-before-on-cmd = <0x00>;
				somc,platform-regulator-settings = [03 03 03 00 20 00 01];
				somc,mdss-dsi-lane-config = [02 00 ef 00 20 00 00 01 ff 02 00 ef 00 40 00 00 01 ff 02 00 ef 40 20 00 00 01 ff 02 00 ef 40 00 00 00 01 ff 00 00 45 80 00 00 00 01 97];
				somc,disp-en-on-pre = <0x01>;
				somc,pw-on-rst-seq = <0x00 0x14 0x01 0x0a>;
				somc,disp-en-off-post = <0x46>;
				somc,pw-off-rst-seq = <0x00 0x00>;
				somc,pw-down-period = <0x64>;
				somc,lab-output-voltage = <0x5265c0>;
				somc,ibb-output-voltage = <0x5265c0>;
				somc,lcd-id = <0x00>;
				somc,lcd-id-adc = <0x00 0x7fffffff>;
				somc,mdss-dsi-master;
				linux,phandle = <0x35>;
				phandle = <0x35>;
			};

			somc,default_cmd_panel_1 {
				qcom,mdss-dsi-panel-name = "default";
				qcom,mdss-dsi-panel-controller = <0x2b>;
				qcom,mdss-dsi-panel-destination = "display_1";
				qcom,mdss-dsi-panel-type = "dsi_cmd_mode";
				qcom,mdss-dsi-panel-width = <0x438>;
				qcom,mdss-dsi-panel-height = <0x780>;
				qcom,mdss-dsi-bpp = <0x18>;
				qcom,mdss-dsi-h-back-porch = <0x08>;
				qcom,mdss-dsi-h-pulse-width = <0x08>;
				qcom,mdss-dsi-h-front-porch = <0x38>;
				qcom,mdss-dsi-v-back-porch = <0x08>;
				qcom,mdss-dsi-v-pulse-width = <0x02>;
				qcom,mdss-dsi-v-front-porch = <0xe9>;
				qcom,mdss-pan-physical-width-dimension = <0x40>;
				qcom,mdss-pan-physical-height-dimension = <0x72>;
				qcom,mdss-dsi-panel-framerate = <0x3c>;
				qcom,mdss-dsi-virtual-channel-id = <0x00>;
				qcom,mdss-dsi-stream = <0x00>;
				qcom,mdss-dsi-h-sync-skew = <0x00>;
				qcom,mdss-dsi-h-left-border = <0x00>;
				qcom,mdss-dsi-h-right-border = <0x00>;
				qcom,mdss-dsi-v-top-border = <0x00>;
				qcom,mdss-dsi-v-bottom-border = <0x00>;
				qcom,mdss-dsi-underflow-color = <0x00>;
				qcom,mdss-dsi-border-color = <0x00>;
				qcom,mdss-dsi-h-sync-pulse = <0x01>;
				qcom,mdss-dsi-traffic-mode = "non_burst_sync_event";
				qcom,mdss-dsi-bllp-eof-power-mode;
				qcom,mdss-dsi-bllp-power-mode;
				qcom,mdss-dsi-dma-trigger = "trigger_sw";
				qcom,mdss-dsi-mdp-trigger = "none";
				somc,mdss-dsi-init-command = [15 01 00 00 00 00 02 ff e0 15 01 00 00 00 00 02 fb 01 15 01 00 00 00 00 02 b5 86 15 01 00 00 00 00 02 b6 77 15 01 00 00 00 00 02 b8 ad 15 01 00 00 00 00 02 ff 20 15 01 00 00 00 00 02 fb 01 15 01 00 00 00 00 02 2d 14 15 01 00 00 00 00 02 ff 24 15 01 00 00 00 00 02 fb 01 15 01 00 00 00 00 02 c6 00 15 01 00 00 00 00 02 92 8b 15 01 00 00 00 00 02 c5 32 15 01 00 00 00 00 02 ff 10 15 01 00 00 00 00 02 35 00 39 01 00 00 00 00 03 44 03 00 39 01 00 00 00 00 04 3b 03 30 06 15 01 00 00 01 00 02 bb 10 05 01 00 00 1e 00 01 11];
				qcom,mdss-dsi-on-command = <0x5010000 0x28000129>;
				qcom,mdss-dsi-off-command = <0x5010000 0x128 0x5010000 0x64000110>;
				qcom,mdss-dsi-on-command-state = "dsi_lp_mode";
				qcom,mdss-dsi-off-command-state = "dsi_hs_mode";
				qcom,mdss-dsi-te-pin-select = <0x01>;
				qcom,mdss-dsi-wr-mem-start = <0x2c>;
				qcom,mdss-dsi-wr-mem-continue = <0x3c>;
				qcom,mdss-dsi-te-dcs-command = <0x01>;
				qcom,mdss-dsi-te-check-enable;
				qcom,mdss-dsi-te-using-te-pin;
				qcom,mdss-dsi-lane-0-state;
				qcom,mdss-dsi-lane-1-state;
				qcom,mdss-dsi-lane-2-state;
				qcom,mdss-dsi-lane-3-state;
				qcom,mdss-dsi-panel-timings = <0xe6382600 0x6866323c 0x2c030400>;
				qcom,mdss-dsi-t-clk-post = <0x21>;
				qcom,mdss-dsi-t-clk-pre = <0x2b>;
				qcom,mdss-dsi-tx-eot-append;
				qcom,mdss-dsi-lp11-init;
				qcom,mdss-dsi-bl-min-level = <0x01>;
				qcom,mdss-dsi-bl-max-level = <0xfff>;
				qcom,mdss-brightness-max-level = <0xfff>;
				qcom,mdss-dsi-bl-pmic-control-type = "bl_ctrl_wled";
				qcom,qpnp-lab-limit-maximum-current = <0xc8>;
				qcom,qpnp-ibb-limit-maximum-current = <0x320>;
				somc,mdss-dsi-disp-on-in-hs = <0x00>;
				somc,mdss-dsi-wait-time-before-on-cmd = <0x00>;
				somc,platform-regulator-settings = [03 03 03 00 20 00 01];
				somc,mdss-dsi-lane-config = [02 00 ef 00 20 00 00 01 ff 02 00 ef 00 40 00 00 01 ff 02 00 ef 40 20 00 00 01 ff 02 00 ef 40 00 00 00 01 ff 00 00 45 80 00 00 00 01 97];
				somc,disp-en-on-pre = <0x01>;
				somc,pw-on-rst-seq = <0x00 0x14 0x01 0x0a>;
				somc,disp-en-off-post = <0x46>;
				somc,pw-off-rst-seq = <0x00 0x00>;
				somc,pw-down-period = <0x64>;
				somc,lab-output-voltage = <0x5265c0>;
				somc,ibb-output-voltage = <0x5265c0>;
				somc,lcd-id = <0x01>;
				somc,lcd-id-adc = <0x00 0x7fffffff>;
				somc,mdss-dsi-master;
			};
		};

		qcom,mdss_dsi@fd998000 {
			compatible = "qcom,mdss-dsi-ctrl";
			label = "MDSS DSI CTRL->0";
			cell-index = <0x00>;
			reg = <0xfd998000 0x260 0xfd998500 0x280 0xfd998780 0x30 0xfd828000 0x108>;
			reg-names = "dsi_ctrl", "dsi_phy", "dsi_phy_regulator", "mmss_misc_phys";
			gdsc-supply = <0x27>;
			vdd-supply = <0x2d>;
			vddio-supply = <0x2e>;
			vdda-supply = <0x2f>;
			vcca-supply = <0x30>;
			qcom,mdss-fb-map = <0x31>;
			qcom,mdss-mdp = <0x32>;
			clocks = <0x1e 0x618336ac 0x1e 0x684ccb41 0x1e 0xea30b0e7 0x1e 0xcc07d687 0x1e 0xf5a03f64 0x1e 0x3487234a 0x1e 0x28cafbe6 0x33 0x64a23fa0 0x33 0xf261a1a6 0x33 0x63154efc 0x33 0x1708ae85 0x33 0x5e69f8ef 0x33 0xa6b20c5a 0x34 0xfcd15658>;
			clock-names = "mdp_core_clk", "iface_clk", "core_mmss_clk", "bus_clk", "byte_clk", "pixel_clk", "core_clk", "mdss_byte_clk_mux", "mdss_pixel_clk_mux", "byte_clk_src", "pixel_clk_src", "shadow_byte_clk_src", "shadow_pixel_clk_src", "clk_mdss_dsi1_vco_clk_src";
			qcom,platform-strength-ctrl = [77 06];
			qcom,platform-bist-ctrl = [00 00 b1 ff 00 00];
			qcom,platform-regulator-settings;
			qcom,platform-lane-config;
			qcom,mmss-ulp-clamp-ctrl-offset = <0x14>;
			qcom,mmss-phyreset-ctrl-offset = <0x108>;
			qcom,timing-db-mode;
			qcom,dsi-clk-ln-recovery;
			qcom,dsi-pref-prim-pan = <0x35>;
			pinctrl-names = "mdss_default", "mdss_sleep";
			pinctrl-0 = <0x36 0x37 0x38>;
			pinctrl-1 = <0x39 0x3a 0x3b>;
			qcom,dsi-panel-bias-vreg;
			qcom,platform-reset-gpio = <0x28 0x4e 0x00>;
			qcom,platform-bklight-en-gpio = <0x3c 0x02 0x00>;
			linux,phandle = <0x2b>;
			phandle = <0x2b>;

			qcom,core-supply-entries {
				#address-cells = <0x01>;
				#size-cells = <0x00>;

				qcom,core-supply-entry@0 {
					reg = <0x00>;
					qcom,supply-name = "gdsc";
					qcom,supply-min-voltage = <0x00>;
					qcom,supply-max-voltage = <0x00>;
					qcom,supply-enable-load = <0x00>;
					qcom,supply-disable-load = <0x00>;
				};
			};

			qcom,ctrl-supply-entries {
				#address-cells = <0x01>;
				#size-cells = <0x00>;

				qcom,ctrl-supply-entry@0 {
					reg = <0x00>;
					qcom,supply-name = "vdda";
					qcom,supply-min-voltage = <0x1312d0>;
					qcom,supply-max-voltage = <0x1312d0>;
					qcom,supply-enable-load = <0x186a0>;
					qcom,supply-disable-load = <0x64>;
				};

				qcom,ctrl-supply-entry@1 {
					reg = <0x01>;
					qcom,supply-name = "vddio";
					qcom,supply-min-voltage = <0x1b7740>;
					qcom,supply-max-voltage = <0x1b7740>;
					qcom,supply-enable-load = <0x186a0>;
					qcom,supply-disable-load = <0x64>;
					qcom,supply-post-on-sleep = <0x05>;
				};

				qcom,ctrl-supply-entry@2 {
					reg = <0x02>;
					qcom,supply-name = "vcca";
					qcom,supply-min-voltage = <0xf4240>;
					qcom,supply-max-voltage = <0xf4240>;
					qcom,supply-enable-load = <0x2710>;
					qcom,supply-disable-load = <0x64>;
				};
			};

			qcom,panel-supply-entries {
				#address-cells = <0x01>;
				#size-cells = <0x00>;

				qcom,panel-supply-entry@0 {
					reg = <0x00>;
					qcom,supply-name = "vdd";
					qcom,supply-min-voltage = <0x1b7740>;
					qcom,supply-max-voltage = <0x1b7740>;
					qcom,supply-enable-load = <0x186a0>;
					qcom,supply-disable-load = <0x64>;
					qcom,supply-post-on-sleep = <0x05>;
				};
			};
		};

		qcom,spmi@fc4c0000 {
			qcom,pmi8994@3 {
				spmi-slave-container;
				reg = <0x03>;
				#address-cells = <0x01>;
				#size-cells = <0x01>;

				qcom,leds@d800 {
					compatible = "qcom,qpnp-wled";
					reg = <0xd800 0x100 0xd900 0x100 0xdc00 0x100 0xde00 0x100>;
					reg-names = "qpnp-wled-ctrl-base", "qpnp-wled-sink-base", "qpnp-wled-ibb-base", "qpnp-wled-lab-base";
					interrupts = <0x03 0xd8 0x02>;
					interrupt-names = "sc-irq";
					status = "okay";
					linux,name = "wled";
					linux,default-trigger = "bkl-trigger";
					qcom,fdbk-output = "auto";
					qcom,vref-mv = <0x15e>;
					qcom,switch-freq-khz = <0x320>;
					qcom,ovp-mv = <0x733c>;
					qcom,ilim-ma = <0x294>;
					qcom,boost-duty-ns = <0x1a>;
					qcom,mod-freq-khz = <0x2580>;
					qcom,dim-mode = "hybrid";
					qcom,dim-method = "linear";
					qcom,hyb-thres = <0x271>;
					qcom,sync-dly-us = <0x320>;
					qcom,fs-curr-ua = <0x5dc0>;
					qcom,en-phase-stag;
					qcom,ibb-pwrup-dly = <0x08>;
					qcom,led-strings-list = [00 01];
					qcom,en-ext-pfet-sc-pro;
					somc,calc-curr;
					somc,init-br = <0x666>;
					somc-s1,br-power-save = <0x83>;
				};
			};
		};
	};

	chosen {
		bootargs = "sched_enable_hmp=1 sched_enable_power_aware=1";
	};

	memory {
		device_type = "memory";
		reg = <0x00 0x00 0x00 0x00>;
		#address-cells = <0x02>;
		#size-cells = <0x02>;

		secure_region@0 {
			linux,reserve-contiguous-region;
			reg = <0x00 0x00 0x00 0x12c00000>;
			label = "secure_mem";
			linux,phandle = <0x198>;
			phandle = <0x198>;
		};

		adsp_region@0 {
			linux,reserve-contiguous-region;
			reg = <0x00 0x00 0x00 0x3f00000>;
			label = "adsp_mem";
			linux,phandle = <0xc4>;
			phandle = <0xc4>;
		};

		qsecom_region@0 {
			linux,reserve-contiguous-region;
			reg = <0x00 0x00 0x00 0x1900000>;
			label = "qseecom_mem";
			linux,phandle = <0x199>;
			phandle = <0x199>;
		};

		audio_region@0 {
			linux,reserve-contiguous-region;
			linux,reserve-region;
			reg = <0x00 0x00 0x00 0x614000>;
			label = "audio_mem";
			linux,phandle = <0x170>;
			phandle = <0x170>;
		};

		debug_region@0 {
			compatible = "qcom,debug_region";
			linux,reserve-contiguous-region;
			linux,reserve-region;
			linux,remove-completely;
			reg = <0x00 0x6200000 0x00 0x100000>;
			label = "debug_mem";
		};

		removed_regions@0 {
			linux,reserve-contiguous-region;
			linux,reserve-region;
			linux,remove-completely;
			reg = <0x00 0x6300000 0x00 0x9d00000>;
			label = "memory_hole";
		};

		dfps_data_mem@0 {
			linux,reserve-contiguous-region;
			linux,reserve-region;
			reg = <0x00 0x3400000 0x00 0x1000>;
			label = "dfps_data_mem";
			linux,phandle = <0x46>;
			phandle = <0x46>;
		};

		cont_splash_mem@0 {
			linux,reserve-contiguous-region;
			linux,reserve-region;
			reg = <0x00 0x3401000 0x00 0x2200000>;
			label = "cont_splash_mem";
			linux,phandle = <0x2a>;
			phandle = <0x2a>;
		};

		peripheral_region@0 {
			linux,reserve-contiguous-region;
			linux,reserve-region;
			linux,remove-completely;
			reg = <0x00 0xca00000 0x00 0x1f00000>;
			label = "peripheral_mem";
			linux,phandle = <0x106>;
			phandle = <0x106>;
		};

		modem_region@0 {
			linux,reserve-contiguous-region;
			linux,reserve-region;
			linux,remove-completely;
			reg = <0x00 0x7000000 0x00 0x5a00000>;
			label = "modem_mem";
			linux,phandle = <0x10a>;
			phandle = <0x10a>;
		};

		fb_region@0 {
			linux,reserve-contiguous-region;
			linux,reserve-region;
			reg = <0x00 0x40000000 0x00 0x1000000>;
			label = "fb_mem";
			linux,phandle = <0x29>;
			phandle = <0x29>;
		};
	};
};
